VERSION "created by canmatrix"

NS_ :

BS_:

BU_: IPD

BO_ 882 BCM_BDCAN_100ms_FrP41: 8 Vector__XXX
 SG_ RrTireStdPrs : 35|4@0+ (0.1,1.5) [1.5|3] "null" IPD
 SG_ FrtTireStdPrs : 39|4@0+ (0.1,1.5) [1.5|3] "null" IPD

BO_ 1949 DIAG_DTCInfo_ICBAD: 8 IPD
 SG_ DTCInfomationIPD : 7|56@0+ (1,0) [0|72057594037927935] "null" Vector__XXX

BO_ 1319 DKMM_LHBDCANFD_Event_FrS03: 8 Vector__XXX
 SG_ AIParkngSpcID : 31|5@0+ (1,0) [0|31] "null" IPD

BO_ 2015 Diag_BKPCANFD_FuncReq: 64 Vector__XXX

BO_ 1845 Diag_BKPCANFD_PhyReq_IPD: 64 Vector__XXX

BO_ 1853 Diag_BKPCANFD_PhyResp_IPD: 64 IPD

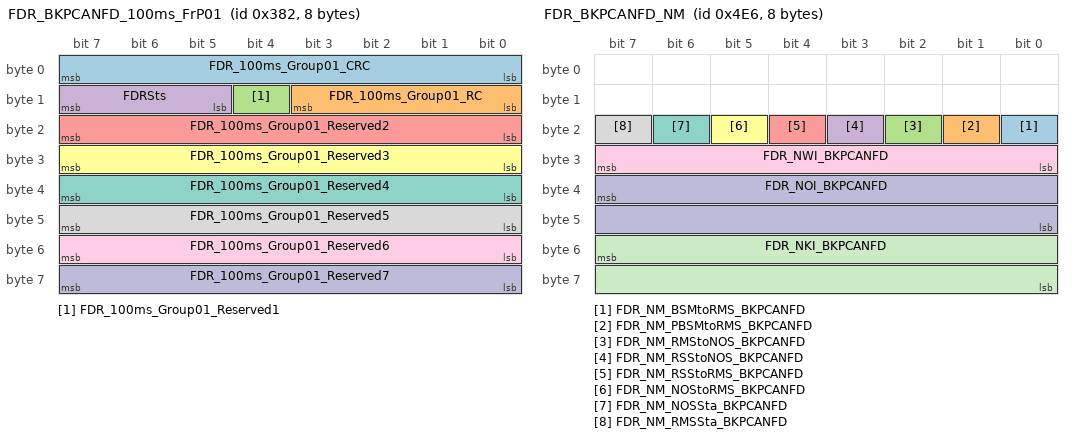
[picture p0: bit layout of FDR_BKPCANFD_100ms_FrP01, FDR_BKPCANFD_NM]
BO_ 898 FDR_BKPCANFD_100ms_FrP01: 8 Vector__XXX
 SG_ FDR_100ms_Group01_CRC : 7|8@0+ (1,0) [0|255] "null" IPD
 SG_ FDR_100ms_Group01_RC : 11|4@0+ (1,0) [0|15] "null" IPD
 SG_ FDR_100ms_Group01_Reserved1 : 12|1@0+ (1,0) [0|1] "null" IPD
 SG_ FDRSts : 15|3@0+ (1,0) [0|7] "null" IPD
 SG_ FDR_100ms_Group01_Reserved2 : 23|8@0+ (1,0) [0|255] "null" IPD
 SG_ FDR_100ms_Group01_Reserved3 : 31|8@0+ (1,0) [0|255] "null" IPD
 SG_ FDR_100ms_Group01_Reserved4 : 39|8@0+ (1,0) [0|255] "null" IPD
 SG_ FDR_100ms_Group01_Reserved5 : 47|8@0+ (1,0) [0|255] "null" IPD
 SG_ FDR_100ms_Group01_Reserved6 : 55|8@0+ (1,0) [0|255] "null" IPD
 SG_ FDR_100ms_Group01_Reserved7 : 63|8@0+ (1,0) [0|255] "null" IPD

BO_ 1254 FDR_BKPCANFD_NM: 8 Vector__XXX
 SG_ FDR_NM_BSMtoRMS_BKPCANFD : 16|1@0+ (1,0) [0|1] "null" Vector__XXX
 SG_ FDR_NM_PBSMtoRMS_BKPCANFD : 17|1@0+ (1,0) [0|1] "null" Vector__XXX
 SG_ FDR_NM_RMStoNOS_BKPCANFD : 18|1@0+ (1,0) [0|1] "null" Vector__XXX
 SG_ FDR_NM_RSStoNOS_BKPCANFD : 19|1@0+ (1,0) [0|1] "null" Vector__XXX
 SG_ FDR_NM_RSStoRMS_BKPCANFD : 20|1@0+ (1,0) [0|1] "null" Vector__XXX
 SG_ FDR_NM_NOStoRMS_BKPCANFD : 21|1@0+ (1,0) [0|1] "null" Vector__XXX
 SG_ FDR_NM_NOSSta_BKPCANFD : 22|1@0+ (1,0) [0|1] "null" Vector__XXX
 SG_ FDR_NM_RMSSta_BKPCANFD : 23|1@0+ (1,0) [0|1] "null" Vector__XXX
 SG_ FDR_NWI_BKPCANFD : 31|8@0+ (1,0) [0|255] "null" Vector__XXX
 SG_ FDR_NOI_BKPCANFD : 39|16@0+ (1,0) [0|65535] "null" Vector__XXX
 SG_ FDR_NKI_BKPCANFD : 55|16@0+ (1,0) [0|65535] "null" Vector__XXX

BO_ 958 FVCM_BKPCANFD_100ms_FrP04: 64 IPD
 SG_ ACCDetObj1LatRltvDist : 23|15@0+ (0.0078,-128) [-128.0000|127.5826] "null" Vector__XXX
 SG_ ACCDetObj1Risk : 24|1@0+ (1,0) [0|1] "null" Vector__XXX
 SG_ ACCDetObj2LatRltvDist : 39|15@0+ (0.0078,-128) [-128.0000|127.5826] "null" Vector__XXX
 SG_ ACCDetObj2Risk : 40|1@0+ (1,0) [0|1] "null" Vector__XXX
 SG_ ACCDetObj3LatRltvDist : 55|15@0+ (0.0078,-128) [-128.0000|127.5826] "null" Vector__XXX
 SG_ ACCDetObj3Risk : 56|1@0+ (1,0) [0|1] "null" Vector__XXX
 SG_ ACCDetObj1LongtRltvDist : 71|12@0+ (0.0625,0) [0.0000|255.9375] "null" Vector__XXX
 SG_ ACCDetObj1LongtRltvSpd : 75|12@0+ (0.0625,-128) [-128.0000|127.9375] "null" Vector__XXX
 SG_ ACCDetObj2LongtRltvDist : 95|12@0+ (0.0625,0) [0.0000|255.9375] "null" Vector__XXX
 SG_ ACCDetObj2LongtRltvSpd : 99|12@0+ (0.0625,-128) [-128.0000|127.9375] "null" Vector__XXX
 SG_ ACCDetObj3LongtRltvDist : 119|12@0+ (0.0625,0) [0.0000|255.9375] "null" Vector__XXX
 SG_ ACCDetObj3LongtRltvSpd : 123|12@0+ (0.0625,-128) [-128.0000|127.9375] "null" Vector__XXX
 SG_ ACCConfmSw : 137|2@0+ (1,0) [0|3] "null" Vector__XXX
 SG_ ACCDetObj1ExistPrblty : 143|6@0+ (0.015625,0) [0.000000|0.984375] "null" Vector__XXX
 SG_ ACCCurveSpdSw : 145|2@0+ (1,0) [0|3] "null" Vector__XXX
 SG_ ACCDetObj1Id : 151|6@0+ (1,0) [0|63] "null" Vector__XXX
 SG_ ACCDetObj2Id : 153|6@0+ (1,0) [0|63] "null" Vector__XXX
 SG_ ACCDetObj2ExistPrblty : 159|6@0+ (0.015625,0) [0.000000|0.984375] "null" Vector__XXX
 SG_ ACCDetObj3ExistPrblty : 163|6@0+ (0.015625,0) [0.000000|0.984375] "null" Vector__XXX
 SG_ ACCDetObj3Id : 183|6@0+ (1,0) [0|63] "null" Vector__XXX
 SG_ ELKWarning : 191|4@0+ (1,0) [0|15] "null" Vector__XXX
 SG_ ACCDetObj2SyncCtr : 195|4@0+ (1,0) [0|15] "null" Vector__XXX
 SG_ ACCDetObj1SyncCtr : 199|4@0+ (1,0) [0|15] "null" Vector__XXX
 SG_ ACCDetObj3SyncCtr : 207|4@0+ (1,0) [0|15] "null" Vector__XXX
 SG_ ACCDetObj2Typ : 217|3@0+ (1,0) [0|7] "null" Vector__XXX
 SG_ ACCDetObj1Typ : 230|3@0+ (1,0) [0|7] "null" Vector__XXX
 SG_ ACCDrvrTkovReq : 256|1@0+ (1,0) [0|1] "null" Vector__XXX
 SG_ ACCDetObj3Typ : 506|3@0+ (1,0) [0|7] "null" Vector__XXX

BO_ 956 FVCM_BKPCANFD_100ms_FrP05: 64 IPD
 SG_ PilotSysMsg : 15|4@0+ (1,0) [0|15] "null" Vector__XXX
 SG_ Lane0_C0 : 23|12@0+ (0.00390625,-8) [-8.00000000|7.99609375] "null" Vector__XXX
 SG_ Lane0_C1 : 27|12@0+ (0.00048828125,-1) [-1.00000000000|0.99951171875] "null" Vector__XXX
 SG_ Lane0_C2 : 47|12@0+ (0.000015259,-0.03124285) [-0.031242850|0.031242755] "null" Vector__XXX
 SG_ Lane0_C3 : 51|12@0+ (4.768E-007,-2.3842E-007) [-2.3842E-007|0.00195225758] "null" Vector__XXX
 SG_ Lane1_C0 : 71|12@0+ (0.00390625,-8) [-8.00000000|7.99609375] "null" Vector__XXX
 SG_ Lane1_C1 : 75|12@0+ (0.00048828125,-1) [-1.00000000000|0.99951171875] "null" Vector__XXX
 SG_ Lane1_C2 : 95|12@0+ (0.000015259,-0.03124285) [-0.031242850|0.031242755] "null" Vector__XXX
 SG_ Lane1_C3 : 99|12@0+ (4.768E-007,-2.3842E-007) [-2.3842E-007|0.00195225758] "null" Vector__XXX
 SG_ Lane2_C0 : 119|12@0+ (0.00390625,-8) [-8.00000000|7.99609375] "null" Vector__XXX
 SG_ Lane2_C1 : 123|12@0+ (0.00048828125,-1) [-1.00000000000|0.99951171875] "null" Vector__XXX
 SG_ Lane2_C2 : 143|12@0+ (0.000015259,-0.03124285) [-0.031242850|0.031242755] "null" Vector__XXX
 SG_ Lane2_C3 : 147|12@0+ (0.0000038147,-0.0078125) [-0.0078125000|0.0078086965] "null" Vector__XXX
 SG_ Lane3_C0 : 167|12@0+ (0.00390625,-8) [-8.00000000|7.99609375] "null" Vector__XXX
 SG_ Lane3_C1 : 171|12@0+ (0.00048828125,-1) [-1.00000000000|0.99951171875] "null" Vector__XXX
 SG_ Lane3_C2 : 191|12@0+ (0.000015259,-0.03124285) [-0.031242850|0.031242755] "null" Vector__XXX
 SG_ Lane3_C3 : 195|12@0+ (0.0000038147,-0.0078125) [-0.0078125000|0.0078086965] "null" Vector__XXX
 SG_ Lane0_ViewRangeStart : 215|8@0+ (0.25,0) [0.00|63.75] "null" Vector__XXX
 SG_ Lane1_ViewRangeStart : 223|8@0+ (0.25,0) [0.00|63.75] "null" Vector__XXX
 SG_ Lane2_ViewRangeStart : 231|8@0+ (0.25,0) [0.00|63.75] "null" Vector__XXX
 SG_ Lane3_ViewRangeStart : 239|8@0+ (0.25,0) [0.00|63.75] "null" Vector__XXX
 SG_ Lane0_ViewRangeEnd : 247|9@0+ (0.25,0) [0.00|127.75] "null" Vector__XXX
 SG_ Lane1_ViewRangeEnd : 248|9@0+ (0.25,0) [0.00|127.75] "null" Vector__XXX
 SG_ Lane0_ExistPrblty : 254|6@0+ (0.015625,0) [0.000000|0.984375] "null" Vector__XXX
 SG_ Lane2_ViewRangeEnd : 271|9@0+ (0.25,0) [0.00|127.75] "null" Vector__XXX
 SG_ Lane3_ViewRangeEnd : 272|9@0+ (0.25,0) [0.00|127.75] "null" Vector__XXX
 SG_ Lane1_ExistPrblty : 278|6@0+ (0.015625,0) [0.000000|0.984375] "null" Vector__XXX
 SG_ Lane0_Part0_SyncFrameIndex : 291|4@0+ (1,0) [0|15] "null" Vector__XXX
 SG_ Lane0_ID : 295|4@0+ (1,0) [0|15] "null" Vector__XXX
 SG_ Lane1_Part0_SyncFrameIndex : 299|4@0+ (1,0) [0|15] "null" Vector__XXX
 SG_ Lane1_ID : 303|4@0+ (1,0) [0|15] "null" Vector__XXX
 SG_ Lane2_Part0_SyncFrameIndex : 307|4@0+ (1,0) [0|15] "null" Vector__XXX
 SG_ Lane2_ID : 311|4@0+ (1,0) [0|15] "null" Vector__XXX
 SG_ Lane3_Part0_SyncFrameIndex : 315|4@0+ (1,0) [0|15] "null" Vector__XXX
 SG_ Lane3_ID : 319|4@0+ (1,0) [0|15] "null" Vector__XXX
 SG_ TLRMsgReq : 321|2@0+ (1,0) [0|3] "null" Vector__XXX
 SG_ Lane0_MarkerColor : 324|3@0+ (1,0) [0|7] "null" Vector__XXX
 SG_ Lane0_location : 327|3@0+ (1,0) [0|7] "null" Vector__XXX
 SG_ TLRSysSts : 329|2@0+ (1,0) [0|3] "null" Vector__XXX
 SG_ Lane1_location : 332|3@0+ (1,0) [0|7] "null" Vector__XXX
 SG_ Lane0_MarkerType : 335|3@0+ (1,0) [0|7] "null" Vector__XXX
 SG_ Lane1_MarkerType : 340|3@0+ (1,0) [0|7] "null" Vector__XXX
 SG_ Lane1_MarkerColor : 343|3@0+ (1,0) [0|7] "null" Vector__XXX
 SG_ Lane2_ExistPrblty : 351|6@0+ (0.015625,0) [0.000000|0.984375] "null" Vector__XXX
 SG_ Lane2_MarkerColor : 356|3@0+ (1,0) [0|7] "null" Vector__XXX
 SG_ Lane2_location : 359|3@0+ (1,0) [0|7] "null" Vector__XXX
 SG_ Lane3_location : 364|3@0+ (1,0) [0|7] "null" Vector__XXX
 SG_ Lane2_MarkerType : 367|3@0+ (1,0) [0|7] "null" Vector__XXX
 SG_ Lane3_ExistPrblty : 375|6@0+ (0.015625,0) [0.000000|0.984375] "null" Vector__XXX
 SG_ Lane3_MarkerType : 380|3@0+ (1,0) [0|7] "null" Vector__XXX
 SG_ Lane3_MarkerColor : 383|3@0+ (1,0) [0|7] "null" Vector__XXX
 SG_ TLRWarning : 388|3@0+ (1,0) [0|7] "null" Vector__XXX
 SG_ TLRMdSwDspCmd : 391|3@0+ (1,0) [0|7] "null" Vector__XXX
 SG_ SpdLmtOfstSetResp : 399|6@0+ (1,-20) [-20|43] "null" Vector__XXX
 SG_ ACCDetObjHdngAng : 495|8@0+ (2,-180) [-180|330] "null" Vector__XXX
 SG_ CCSpdVcCmdCnfm : 503|3@0+ (1,0) [0|7] "null" Vector__XXX

BO_ 307 FVCM_BKPCANFD_20ms_FrP02: 16 IPD
 SG_ FVCM_20ms_Group02_CRC : 7|8@0+ (1,0) [0|255] "null" Vector__XXX
 SG_ FVCM_20ms_Group02_RC : 11|4@0+ (1,0) [0|15] "null" Vector__XXX
 SG_ FVCM_20ms_Group02_Reserved1 : 15|4@0+ (1,0) [0|15] "null" Vector__XXX
 SG_ ACCTotWhlToqReqVal : 23|16@0+ (1,-30000) [-30000|35535] "null" Vector__XXX
 SG_ ACCDrvrSelTrgtSpd : 39|15@0+ (0.015625,0) [0.000000|511.984375] "ms" Vector__XXX
 SG_ ACCGoNotfr : 40|1@0+ (1,0) [0|1] "null" Vector__XXX
 SG_ FVCM_20ms_Group02_Reserved2 : 48|1@0+ (1,0) [0|1] "null" Vector__XXX
 SG_ ACCDetObjDistLvl : 51|3@0+ (1,0) [0|7] "null" Vector__XXX
 SG_ ELKSysSts_IPD : 55|4@0+ (1,0) [0|15] "null" Vector__XXX
 SG_ ACCTotWhlToqReqSts : 57|2@0+ (1,0) [0|3] "null" Vector__XXX
 SG_ ACCTJAMdSwDspCmd : 60|3@0+ (1,0) [0|7] "null" Vector__XXX
 SG_ ACCSeldTrgtDistLvl : 63|3@0+ (1,0) [0|7] "null" Vector__XXX
 SG_ FVCM_20ms_Group02_Reserved3 : 71|8@0+ (1,0) [0|255] "null" Vector__XXX
 SG_ HandOffStrgWhlDetnSta : 73|2@0+ (1,0) [0|3] "null" Vector__XXX
 SG_ ILCActvnDircnDspCmd : 76|3@0+ (1,0) [0|7] "null" Vector__XXX
 SG_ FVCM_20ms_Group02_Reserved4 : 79|3@0+ (1,0) [0|7] "null" Vector__XXX
 SG_ ILCSwDspCmd : 81|2@0+ (1,0) [0|3] "null" Vector__XXX
 SG_ ILCSysSts : 84|3@0+ (1,0) [0|7] "null" Vector__XXX
 SG_ ILCActvnVelDspCmd : 87|3@0+ (1,0) [0|7] "null" Vector__XXX
 SG_ HandOffStrgWhlDetnStaV : 88|1@0+ (1,0) [0|1] "null" Vector__XXX
 SG_ LDWLKAAudReq : 90|2@0+ (1,0) [0|3] "null" Vector__XXX
 SG_ LDWAdoWrnngDspCmd : 92|2@0+ (1,0) [0|3] "null" Vector__XXX
 SG_ LDWLKADspCmd : 95|3@0+ (1,0) [0|7] "null" Vector__XXX
 SG_ FVCM_20ms_Group02_Reserved5 : 98|3@0+ (1,0) [0|7] "null" Vector__XXX
 SG_ LKADrvrTkovReq : 99|1@0+ (1,0) [0|1] "null" Vector__XXX
 SG_ LDWSnstvtLvl : 101|2@0+ (1,0) [0|3] "null" Vector__XXX
 SG_ LDWLKAHptWrnngDspCmd : 103|2@0+ (1,0) [0|3] "null" Vector__XXX
 SG_ EyeOffRoadDetnSta : 105|2@0+ (1,0) [0|3] "null" Vector__XXX
 SG_ FVCM_20ms_Group02_Reserved6 : 111|6@0+ (1,0) [0|63] "null" Vector__XXX
 SG_ FVCM_20ms_Group02_Reserved7 : 113|2@0+ (1,0) [0|3] "null" Vector__XXX
 SG_ EyeOffRoadDetnStaV : 114|1@0+ (1,0) [0|1] "null" Vector__XXX
 SG_ ACCMsgReq : 119|5@0+ (1,0) [0|31] "null" Vector__XXX
 SG_ FVCM_20ms_Group02_Reserved8 : 127|8@0+ (1,0) [0|255] "null" Vector__XXX

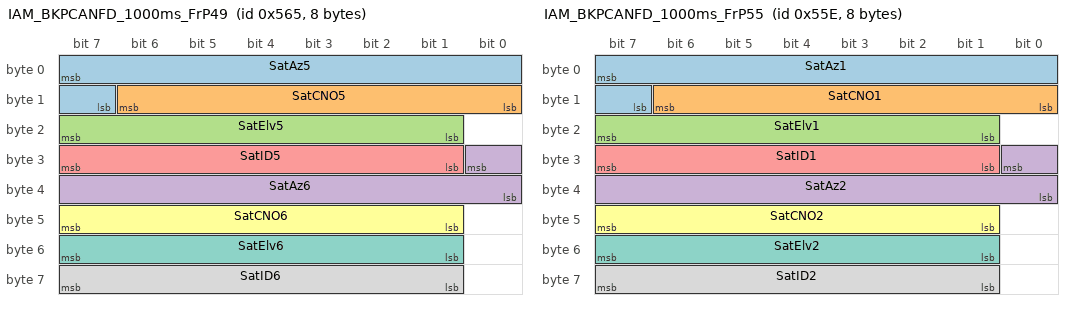
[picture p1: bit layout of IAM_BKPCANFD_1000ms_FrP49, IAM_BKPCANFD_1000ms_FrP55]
BO_ 1381 IAM_BKPCANFD_1000ms_FrP49: 8 Vector__XXX
 SG_ SatAz5 : 7|9@0+ (1,0) [0|511] "Degree" IPD
 SG_ SatCNO5 : 14|7@0+ (1,0) [0|127] "dB" IPD
 SG_ SatElv5 : 23|7@0+ (1,0) [0|127] "Degree" IPD
 SG_ SatAz6 : 24|9@0+ (1,0) [0|511] "Degree" IPD
 SG_ SatID5 : 31|7@0+ (1,0) [0|127] "null" IPD
 SG_ SatCNO6 : 47|7@0+ (1,0) [0|127] "dB" IPD
 SG_ SatElv6 : 55|7@0+ (1,0) [0|127] "Degree" IPD
 SG_ SatID6 : 63|7@0+ (1,0) [0|127] "null" IPD

BO_ 1374 IAM_BKPCANFD_1000ms_FrP55: 8 Vector__XXX
 SG_ SatAz1 : 7|9@0+ (1,0) [0|511] "Degree" IPD
 SG_ SatCNO1 : 14|7@0+ (1,0) [0|127] "dB" IPD
 SG_ SatElv1 : 23|7@0+ (1,0) [0|127] "Degree" IPD
 SG_ SatAz2 : 24|9@0+ (1,0) [0|511] "Degree" IPD
 SG_ SatID1 : 31|7@0+ (1,0) [0|127] "null" IPD
 SG_ SatCNO2 : 47|7@0+ (1,0) [0|127] "dB" IPD
 SG_ SatElv2 : 55|7@0+ (1,0) [0|127] "Degree" IPD
 SG_ SatID2 : 63|7@0+ (1,0) [0|127] "null" IPD

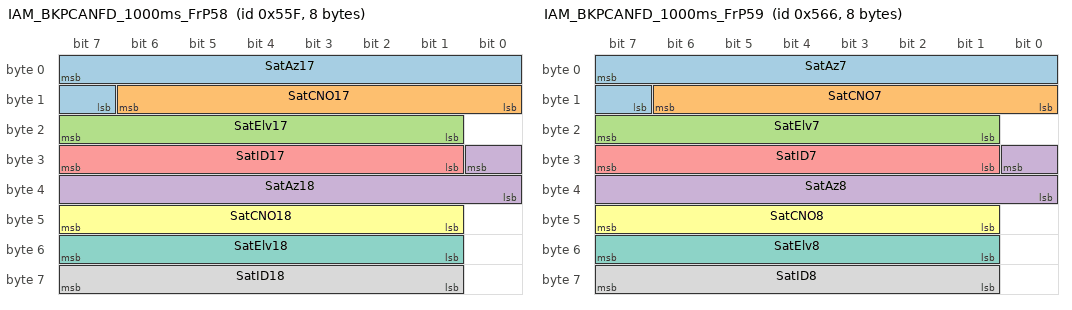
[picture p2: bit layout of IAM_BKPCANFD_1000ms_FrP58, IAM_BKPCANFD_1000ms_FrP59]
BO_ 1375 IAM_BKPCANFD_1000ms_FrP58: 8 Vector__XXX
 SG_ SatAz17 : 7|9@0+ (1,0) [0|511] "Degree" IPD
 SG_ SatCNO17 : 14|7@0+ (1,0) [0|127] "dB" IPD
 SG_ SatElv17 : 23|7@0+ (1,0) [0|127] "Degree" IPD
 SG_ SatAz18 : 24|9@0+ (1,0) [0|511] "Degree" IPD
 SG_ SatID17 : 31|7@0+ (1,0) [0|127] "null" IPD
 SG_ SatCNO18 : 47|7@0+ (1,0) [0|127] "dB" IPD
 SG_ SatElv18 : 55|7@0+ (1,0) [0|127] "Degree" IPD
 SG_ SatID18 : 63|7@0+ (1,0) [0|127] "null" IPD

BO_ 1382 IAM_BKPCANFD_1000ms_FrP59: 8 Vector__XXX
 SG_ SatAz7 : 7|9@0+ (1,0) [0|511] "Degree" IPD
 SG_ SatCNO7 : 14|7@0+ (1,0) [0|127] "dB" IPD
 SG_ SatElv7 : 23|7@0+ (1,0) [0|127] "Degree" IPD
 SG_ SatAz8 : 24|9@0+ (1,0) [0|511] "Degree" IPD
 SG_ SatID7 : 31|7@0+ (1,0) [0|127] "null" IPD
 SG_ SatCNO8 : 47|7@0+ (1,0) [0|127] "dB" IPD
 SG_ SatElv8 : 55|7@0+ (1,0) [0|127] "Degree" IPD
 SG_ SatID8 : 63|7@0+ (1,0) [0|127] "null" IPD

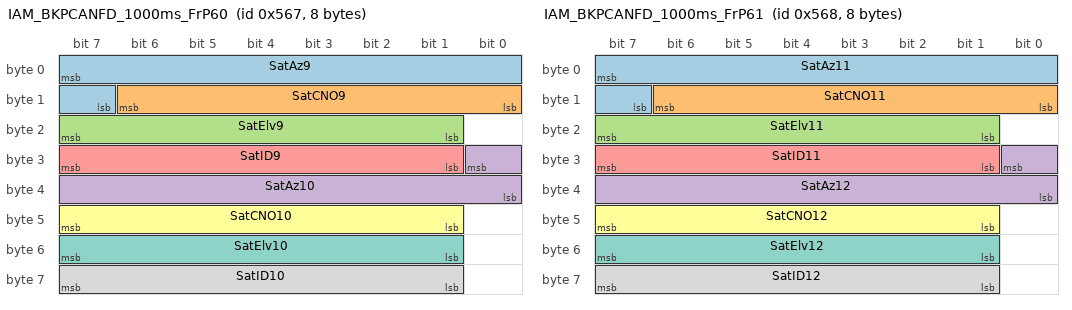
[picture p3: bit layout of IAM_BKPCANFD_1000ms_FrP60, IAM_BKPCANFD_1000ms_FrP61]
BO_ 1383 IAM_BKPCANFD_1000ms_FrP60: 8 Vector__XXX
 SG_ SatAz9 : 7|9@0+ (1,0) [0|511] "Degree" IPD
 SG_ SatCNO9 : 14|7@0+ (1,0) [0|127] "dB" IPD
 SG_ SatElv9 : 23|7@0+ (1,0) [0|127] "Degree" IPD
 SG_ SatAz10 : 24|9@0+ (1,0) [0|511] "Degree" IPD
 SG_ SatID9 : 31|7@0+ (1,0) [0|127] "null" IPD
 SG_ SatCNO10 : 47|7@0+ (1,0) [0|127] "dB" IPD
 SG_ SatElv10 : 55|7@0+ (1,0) [0|127] "Degree" IPD
 SG_ SatID10 : 63|7@0+ (1,0) [0|127] "null" IPD

BO_ 1384 IAM_BKPCANFD_1000ms_FrP61: 8 Vector__XXX
 SG_ SatAz11 : 7|9@0+ (1,0) [0|511] "Degree" IPD
 SG_ SatCNO11 : 14|7@0+ (1,0) [0|127] "dB" IPD
 SG_ SatElv11 : 23|7@0+ (1,0) [0|127] "Degree" IPD
 SG_ SatAz12 : 24|9@0+ (1,0) [0|511] "Degree" IPD
 SG_ SatID11 : 31|7@0+ (1,0) [0|127] "null" IPD
 SG_ SatCNO12 : 47|7@0+ (1,0) [0|127] "dB" IPD
 SG_ SatElv12 : 55|7@0+ (1,0) [0|127] "Degree" IPD
 SG_ SatID12 : 63|7@0+ (1,0) [0|127] "null" IPD

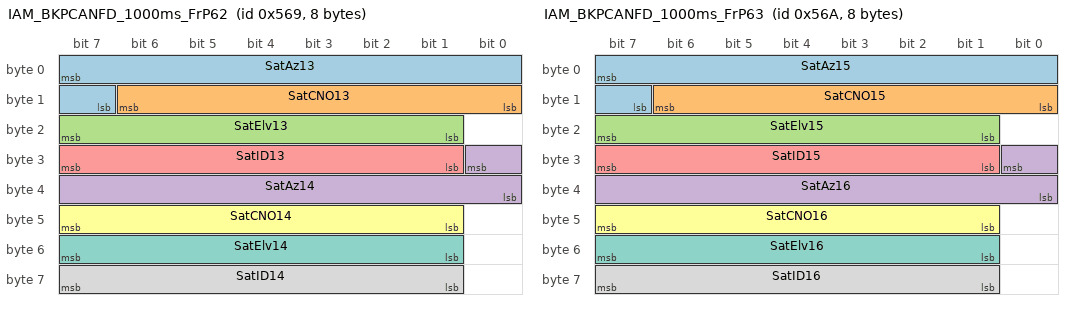
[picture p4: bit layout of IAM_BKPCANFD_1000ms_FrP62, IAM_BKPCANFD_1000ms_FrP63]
BO_ 1385 IAM_BKPCANFD_1000ms_FrP62: 8 Vector__XXX
 SG_ SatAz13 : 7|9@0+ (1,0) [0|511] "Degree" IPD
 SG_ SatCNO13 : 14|7@0+ (1,0) [0|127] "dB" IPD
 SG_ SatElv13 : 23|7@0+ (1,0) [0|127] "Degree" IPD
 SG_ SatAz14 : 24|9@0+ (1,0) [0|511] "Degree" IPD
 SG_ SatID13 : 31|7@0+ (1,0) [0|127] "null" IPD
 SG_ SatCNO14 : 47|7@0+ (1,0) [0|127] "dB" IPD
 SG_ SatElv14 : 55|7@0+ (1,0) [0|127] "Degree" IPD
 SG_ SatID14 : 63|7@0+ (1,0) [0|127] "null" IPD

BO_ 1386 IAM_BKPCANFD_1000ms_FrP63: 8 Vector__XXX
 SG_ SatAz15 : 7|9@0+ (1,0) [0|511] "Degree" IPD
 SG_ SatCNO15 : 14|7@0+ (1,0) [0|127] "dB" IPD
 SG_ SatElv15 : 23|7@0+ (1,0) [0|127] "Degree" IPD
 SG_ SatAz16 : 24|9@0+ (1,0) [0|511] "Degree" IPD
 SG_ SatID15 : 31|7@0+ (1,0) [0|127] "null" IPD
 SG_ SatCNO16 : 47|7@0+ (1,0) [0|127] "dB" IPD
 SG_ SatElv16 : 55|7@0+ (1,0) [0|127] "Degree" IPD
 SG_ SatID16 : 63|7@0+ (1,0) [0|127] "null" IPD

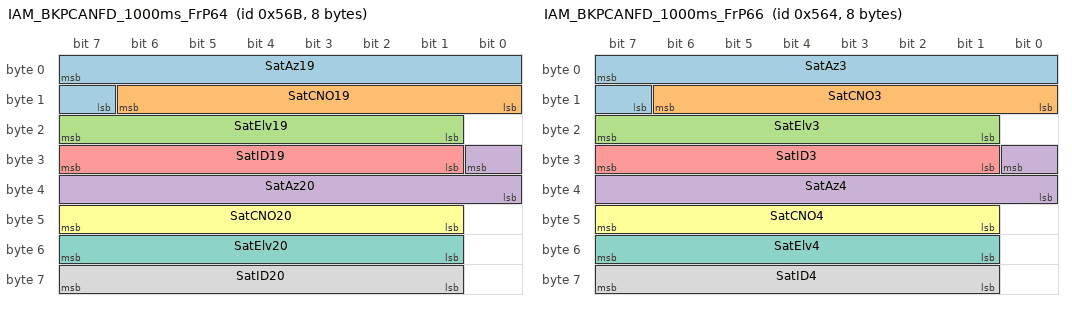
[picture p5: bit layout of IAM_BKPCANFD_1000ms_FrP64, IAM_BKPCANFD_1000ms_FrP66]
BO_ 1387 IAM_BKPCANFD_1000ms_FrP64: 8 Vector__XXX
 SG_ SatAz19 : 7|9@0+ (1,0) [0|511] "Degree" IPD
 SG_ SatCNO19 : 14|7@0+ (1,0) [0|127] "dB" IPD
 SG_ SatElv19 : 23|7@0+ (1,0) [0|127] "Degree" IPD
 SG_ SatAz20 : 24|9@0+ (1,0) [0|511] "Degree" IPD
 SG_ SatID19 : 31|7@0+ (1,0) [0|127] "null" IPD
 SG_ SatCNO20 : 47|7@0+ (1,0) [0|127] "dB" IPD
 SG_ SatElv20 : 55|7@0+ (1,0) [0|127] "Degree" IPD
 SG_ SatID20 : 63|7@0+ (1,0) [0|127] "null" IPD

BO_ 1388 IAM_BKPCANFD_1000ms_FrP65: 8 Vector__XXX
 SG_ SatNum : 7|7@0+ (1,0) [0|127] "null" IPD
 SG_ SvGroup : 15|8@0+ (1,0) [0|255] "null" IPD

BO_ 1380 IAM_BKPCANFD_1000ms_FrP66: 8 Vector__XXX
 SG_ SatAz3 : 7|9@0+ (1,0) [0|511] "Degree" IPD
 SG_ SatCNO3 : 14|7@0+ (1,0) [0|127] "dB" IPD
 SG_ SatElv3 : 23|7@0+ (1,0) [0|127] "Degree" IPD
 SG_ SatAz4 : 24|9@0+ (1,0) [0|511] "Degree" IPD
 SG_ SatID3 : 31|7@0+ (1,0) [0|127] "null" IPD
 SG_ SatCNO4 : 47|7@0+ (1,0) [0|127] "dB" IPD
 SG_ SatElv4 : 55|7@0+ (1,0) [0|127] "Degree" IPD
 SG_ SatID4 : 63|7@0+ (1,0) [0|127] "null" IPD

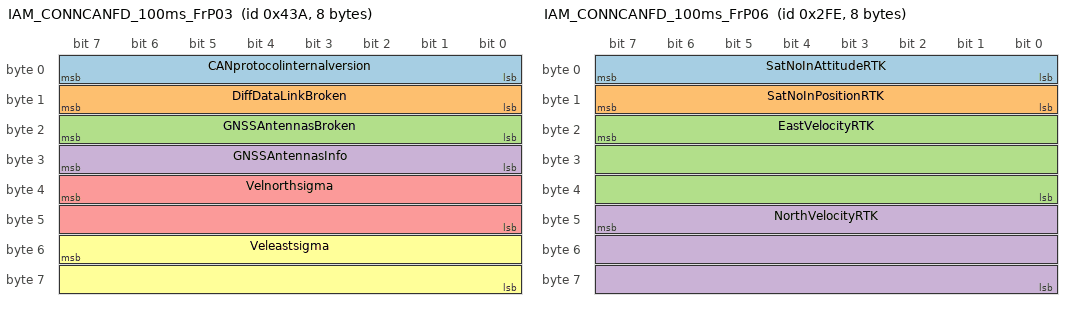
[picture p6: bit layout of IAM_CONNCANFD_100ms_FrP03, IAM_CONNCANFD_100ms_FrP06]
BO_ 1082 IAM_CONNCANFD_100ms_FrP03: 8 Vector__XXX
 SG_ CANprotocolinternalversion : 7|8@0+ (1,0) [0|255] "null" IPD
 SG_ DiffDataLinkBroken : 15|8@0+ (1,0) [0|255] "null" IPD
 SG_ GNSSAntennasBroken : 23|8@0+ (1,0) [0|255] "null" IPD
 SG_ GNSSAntennasInfo : 31|8@0+ (1,0) [0|255] "null" IPD
 SG_ Velnorthsigma : 39|16@0+ (0.001,0) [0.000|65.535] "null" IPD
 SG_ Veleastsigma : 55|16@0+ (0.001,0) [0.000|65.535] "null" IPD

BO_ 766 IAM_CONNCANFD_100ms_FrP06: 8 Vector__XXX
 SG_ SatNoInAttitudeRTK : 7|8@0+ (1,0) [0|255] "null" IPD
 SG_ SatNoInPositionRTK : 15|8@0+ (1,0) [0|255] "null" IPD
 SG_ EastVelocityRTK : 23|24@0- (0.001,0) [-8388.608|8388.607] "null" IPD
 SG_ NorthVelocityRTK : 47|24@0- (0.001,0) [-8388.608|8388.607] "null" IPD

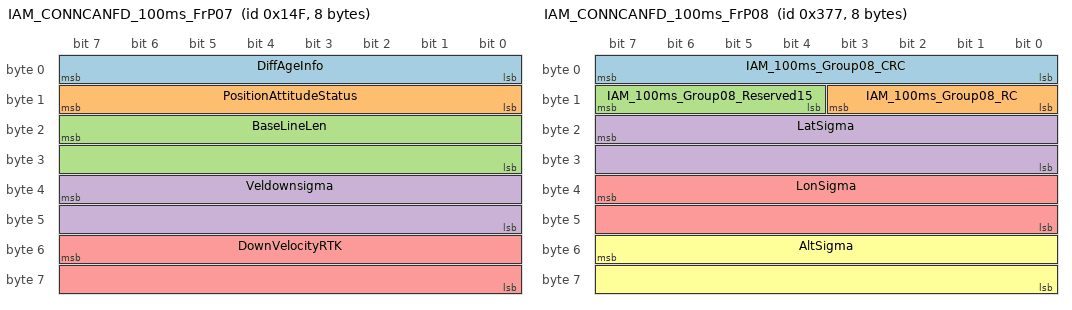
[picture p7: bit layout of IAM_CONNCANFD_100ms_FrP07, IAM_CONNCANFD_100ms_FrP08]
BO_ 335 IAM_CONNCANFD_100ms_FrP07: 8 Vector__XXX
 SG_ DiffAgeInfo : 7|8@0+ (1,0) [0|255] "null" IPD
 SG_ PositionAttitudeStatus : 15|8@0+ (1,0) [0|255] "null" IPD
 SG_ BaseLineLen : 23|16@0+ (0.001,0) [0.000|65.535] "null" IPD
 SG_ Veldownsigma : 39|16@0+ (0.001,0) [0.000|65.535] "null" IPD
 SG_ DownVelocityRTK : 55|16@0- (0.001,0) [-32.768|32.767] "null" IPD

BO_ 887 IAM_CONNCANFD_100ms_FrP08: 8 Vector__XXX
 SG_ IAM_100ms_Group08_CRC : 7|8@0+ (1,0) [0|255] "null" IPD
 SG_ IAM_100ms_Group08_RC : 11|4@0+ (1,0) [0|15] "null" IPD
 SG_ IAM_100ms_Group08_Reserved15 : 15|4@0+ (1,0) [0|15] "null" IPD
 SG_ LatSigma : 23|16@0+ (0.001,0) [0.000|65.535] "null" IPD
 SG_ LonSigma : 39|16@0+ (0.001,0) [0.000|65.535] "null" IPD
 SG_ AltSigma : 55|16@0+ (0.001,0) [0.000|65.535] "null" IPD

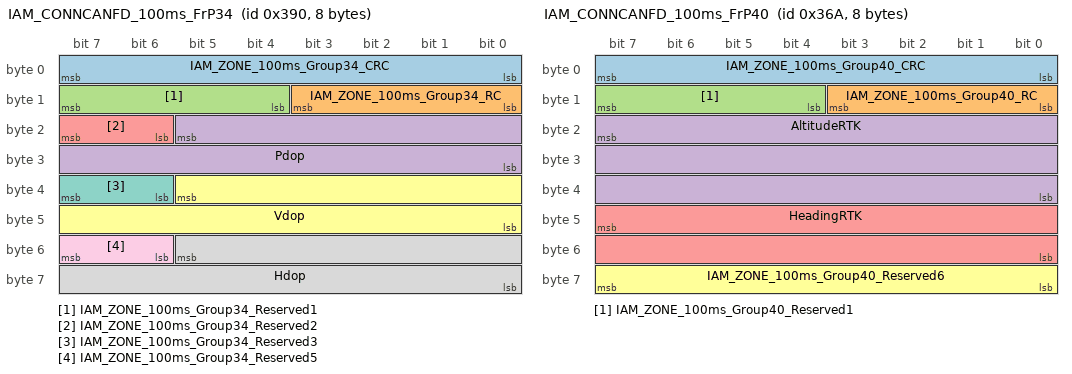
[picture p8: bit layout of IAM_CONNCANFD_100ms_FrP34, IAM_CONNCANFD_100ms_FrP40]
BO_ 912 IAM_CONNCANFD_100ms_FrP34: 8 Vector__XXX
 SG_ IAM_ZONE_100ms_Group34_CRC : 7|8@0+ (1,0) [0|255] "null" IPD
 SG_ IAM_ZONE_100ms_Group34_RC : 11|4@0+ (1,0) [0|15] "null" IPD
 SG_ IAM_ZONE_100ms_Group34_Reserved1 : 15|4@0+ (1,0) [0|15] "null" IPD
 SG_ Pdop : 21|14@0+ (0.01,0) [0.00|163.83] "null" IPD
 SG_ IAM_ZONE_100ms_Group34_Reserved2 : 23|2@0+ (1,0) [0|3] "null" IPD
 SG_ Vdop : 37|14@0+ (0.01,0) [0.00|163.83] "null" IPD
 SG_ IAM_ZONE_100ms_Group34_Reserved3 : 39|2@0+ (1,0) [0|3] "null" IPD
 SG_ Hdop : 53|14@0+ (0.01,0) [0.00|163.83] "null" IPD
 SG_ IAM_ZONE_100ms_Group34_Reserved5 : 55|2@0+ (1,0) [0|3] "null" IPD

BO_ 874 IAM_CONNCANFD_100ms_FrP40: 8 Vector__XXX
 SG_ IAM_ZONE_100ms_Group40_CRC : 7|8@0+ (1,0) [0|255] "null" IPD
 SG_ IAM_ZONE_100ms_Group40_RC : 11|4@0+ (1,0) [0|15] "null" IPD
 SG_ IAM_ZONE_100ms_Group40_Reserved1 : 15|4@0+ (1,0) [0|15] "null" IPD
 SG_ AltitudeRTK : 23|24@0- (0.001,0) [-8388.608|8388.607] "null" IPD
 SG_ HeadingRTK : 47|16@0+ (0.01,0) [0.00|655.35] "null" IPD
 SG_ IAM_ZONE_100ms_Group40_Reserved6 : 63|8@0+ (1,0) [0|255] "null" IPD

BO_ 336 IAM_CONNCANFD_20ms_FrP32: 16 Vector__XXX
 SG_ IAM_20ms_Group32_CRC : 7|8@0+ (1,0) [0|255] "null" IPD
 SG_ IAM_20ms_Group32_RC : 11|4@0+ (1,0) [0|15] "null" IPD
 SG_ RmtParkngAstParkngOutDircnSeln : 15|4@0+ (1,0) [0|15] "null" IPD
 SG_ RmtParkngAstBtnSts : 16|1@0+ (1,0) [0|1] "null" IPD
 SG_ VehFwdSwReq : 18|2@0+ (1,0) [0|3] "null" IPD
 SG_ VehBkwdSwReq : 20|2@0+ (1,0) [0|3] "null" IPD
 SG_ RmtParkngAstDvcSts : 23|3@0+ (1,0) [0|7] "null" IPD
 SG_ RmtDrvrTrgtEPSStrgWhlAng : 31|16@0+ (0.0625,-2048) [-2048.0000|2047.9375] "degree" IPD
 SG_ VehRoadWhlRReq : 41|2@0+ (1,0) [0|3] "null" IPD
 SG_ VehRoadWhlLReq : 43|2@0+ (1,0) [0|3] "null" IPD
 SG_ RmtParkngAstAbotBtnSts : 44|1@0+ (1,0) [0|1] "null" IPD
 SG_ RmtParkngAstDvcFlrRsn : 47|3@0+ (1,0) [0|7] "null" IPD
 SG_ IAM_20ms_Group32_Reserved1 : 51|4@0+ (1,0) [0|15] "null" IPD
 SG_ VehRoadWhlRReqV : 52|1@0+ (1,0) [0|1] "null" IPD
 SG_ VehRoadWhlLReqV : 53|1@0+ (1,0) [0|1] "null" IPD
 SG_ VehFwdSwReqV : 54|1@0+ (1,0) [0|1] "null" IPD
 SG_ VehBkwdSwReqV : 55|1@0+ (1,0) [0|1] "null" IPD
 SG_ IAM_20ms_Group32_Reserved2 : 63|8@0+ (1,0) [0|255] "null" IPD
 SG_ IAM_20ms_Group32_Reserved3 : 71|8@0+ (1,0) [0|255] "null" IPD
 SG_ IAM_20ms_Group32_Reserved4 : 79|8@0+ (1,0) [0|255] "null" IPD
 SG_ IAM_20ms_Group32_Reserved5 : 87|8@0+ (1,0) [0|255] "null" IPD
 SG_ IAM_20ms_Group32_Reserved6 : 95|8@0+ (1,0) [0|255] "null" IPD
 SG_ IAM_20ms_Group32_Reserved7 : 103|8@0+ (1,0) [0|255] "null" IPD
 SG_ IAM_20ms_Group32_Reserved8 : 111|8@0+ (1,0) [0|255] "null" IPD
 SG_ IAM_20ms_Group32_Reserved9 : 119|8@0+ (1,0) [0|255] "null" IPD
 SG_ IAM_20ms_Group32_Reserved10 : 127|8@0+ (1,0) [0|255] "null" IPD

BO_ 89 IAM_CONNCANFD_Event_FrS04: 16 Vector__XXX
 SG_ IAMReststs : 33|2@0+ (1,0) [0|3] "null" IPD

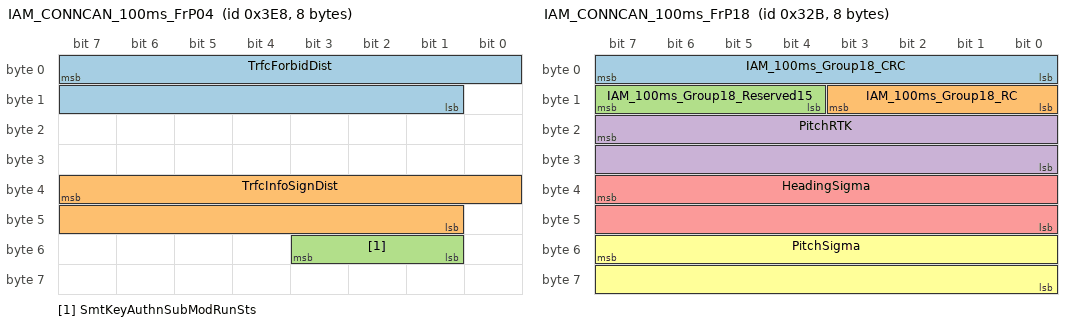
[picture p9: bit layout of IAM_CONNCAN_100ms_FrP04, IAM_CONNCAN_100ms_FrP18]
BO_ 1000 IAM_CONNCAN_100ms_FrP04: 8 Vector__XXX
 SG_ TrfcForbidDist : 7|15@0+ (0.0156,-256) [-256.0000|255.1652] "null" IPD
 SG_ TrfcInfoSignDist : 39|15@0+ (0.0156,-256) [-256.0000|255.1652] "null" IPD
 SG_ SmtKeyAuthnSubModRunSts : 51|3@0+ (1,0) [0|7] "null" Vector__XXX

BO_ 811 IAM_CONNCAN_100ms_FrP18: 8 Vector__XXX
 SG_ IAM_100ms_Group18_CRC : 7|8@0+ (1,0) [0|255] "null" IPD
 SG_ IAM_100ms_Group18_RC : 11|4@0+ (1,0) [0|15] "null" IPD
 SG_ IAM_100ms_Group18_Reserved15 : 15|4@0+ (1,0) [0|15] "null" IPD
 SG_ PitchRTK : 23|16@0- (0.01,0) [-327.68|327.67] "null" IPD
 SG_ HeadingSigma : 39|16@0+ (0.001,0) [0.000|65.535] "null" IPD
 SG_ PitchSigma : 55|16@0+ (0.001,0) [0.000|65.535] "null" IPD

BO_ 1358 IAM_CONNCAN_100ms_FrS21: 8 Vector__XXX
 SG_ KeyDeleResp : 43|4@0+ (1,0) [0|15] "null" Vector__XXX
 SG_ AIParkngReq : 55|8@0+ (1,0) [0|255] "null" IPD

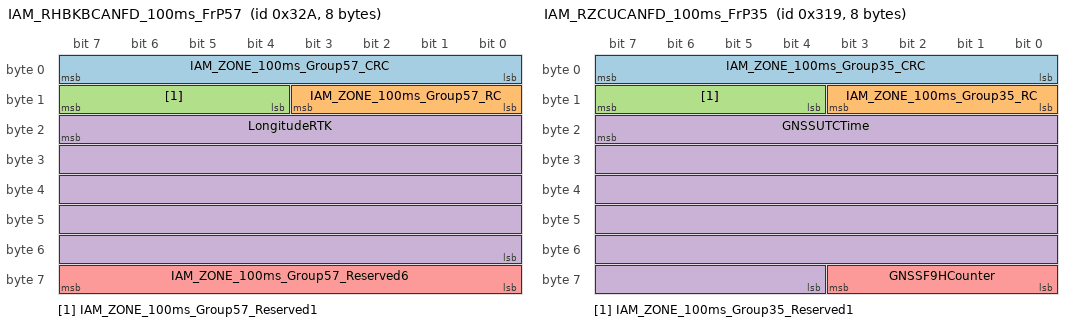
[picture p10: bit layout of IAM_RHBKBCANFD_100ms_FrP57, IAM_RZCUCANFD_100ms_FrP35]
BO_ 810 IAM_RHBKBCANFD_100ms_FrP57: 8 Vector__XXX
 SG_ IAM_ZONE_100ms_Group57_CRC : 7|8@0+ (1,0) [0|255] "null" IPD
 SG_ IAM_ZONE_100ms_Group57_RC : 11|4@0+ (1,0) [0|15] "null" IPD
 SG_ IAM_ZONE_100ms_Group57_Reserved1 : 15|4@0+ (1,0) [0|15] "null" IPD
 SG_ LongitudeRTK : 23|40@0- (1.0E-009,0) [-549.7558138880|549.7558138870] "null" IPD
 SG_ IAM_ZONE_100ms_Group57_Reserved6 : 63|8@0+ (1,0) [0|255] "null" IPD

BO_ 793 IAM_RZCUCANFD_100ms_FrP35: 8 Vector__XXX
 SG_ IAM_ZONE_100ms_Group35_CRC : 7|8@0+ (1,0) [0|255] "null" IPD
 SG_ IAM_ZONE_100ms_Group35_RC : 11|4@0+ (1,0) [0|15] "null" IPD
 SG_ IAM_ZONE_100ms_Group35_Reserved1 : 15|4@0+ (1,0) [0|15] "null" IPD
 SG_ GNSSUTCTime : 23|44@0+ (1,0) [0|17592186044415] "null" IPD
 SG_ GNSSF9HCounter : 59|4@0+ (1,0) [0|15] "null" IPD

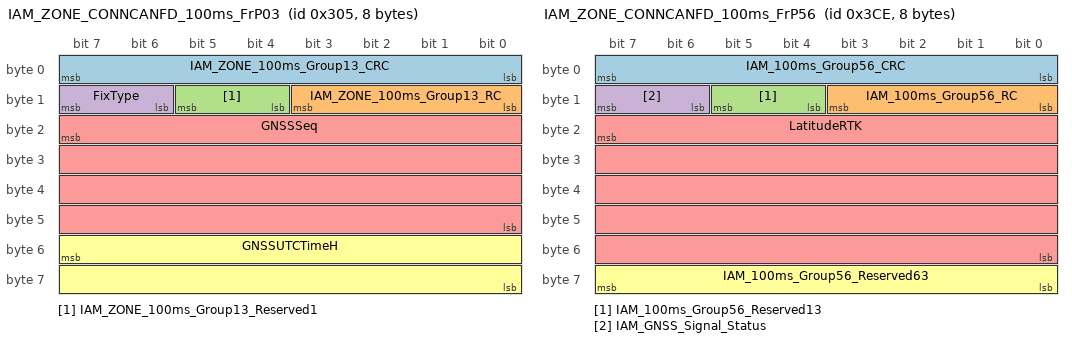
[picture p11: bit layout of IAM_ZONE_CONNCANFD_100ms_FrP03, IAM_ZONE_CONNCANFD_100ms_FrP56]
BO_ 773 IAM_ZONE_CONNCANFD_100ms_FrP03: 8 Vector__XXX
 SG_ IAM_ZONE_100ms_Group13_CRC : 7|8@0+ (1,0) [0|255] "null" IPD
 SG_ IAM_ZONE_100ms_Group13_RC : 11|4@0+ (1,0) [0|15] "null" IPD
 SG_ IAM_ZONE_100ms_Group13_Reserved1 : 13|2@0+ (1,0) [0|3] "null" IPD
 SG_ FixType : 15|2@0+ (1,0) [0|3] "null" IPD
 SG_ GNSSSeq : 23|32@0+ (1,0) [0|4294967295] "null" IPD
 SG_ GNSSUTCTimeH : 55|16@0+ (1,0) [0|65535] "null" IPD

BO_ 974 IAM_ZONE_CONNCANFD_100ms_FrP56: 8 Vector__XXX
 SG_ IAM_100ms_Group56_CRC : 7|8@0+ (1,0) [0|255] "null" IPD
 SG_ IAM_100ms_Group56_RC : 11|4@0+ (1,0) [0|15] "null" IPD
 SG_ IAM_100ms_Group56_Reserved13 : 13|2@0+ (1,0) [0|3] "null" IPD
 SG_ IAM_GNSS_Signal_Status : 15|2@0+ (1,0) [0|3] "null" IPD
 SG_ LatitudeRTK : 23|40@0- (1.0E-009,0) [-549.7558138880|549.7558138870] "null" IPD
 SG_ IAM_100ms_Group56_Reserved63 : 63|8@0+ (1,0) [0|255] "null" IPD

BO_ 348 ICBAD_BKPCANFD_100ms_FrP27: 16 IPD
 SG_ FCWSnstvtLvl : 15|3@0+ (1,0) [0|7] "null" Vector__XXX
 SG_ AEBDspCmd : 19|2@0+ (1,0) [0|3] "null" Vector__XXX
 SG_ AEBMsgReq : 23|4@0+ (1,0) [0|15] "null" Vector__XXX
 SG_ FCWDspCmd : 25|2@0+ (1,0) [0|3] "null" Vector__XXX
 SG_ FCWSysFltSts : 28|3@0+ (1,0) [0|7] "null" Vector__XXX
 SG_ FCWrnngSts : 31|3@0+ (1,0) [0|7] "null" Vector__XXX
 SG_ FCTSysFltSts : 81|2@0+ (1,0) [0|3] "null" Vector__XXX
 SG_ FCTSwSts : 86|3@0+ (1,0) [0|7] "null" Vector__XXX
 SG_ LFCTWrnng : 92|3@0+ (1,0) [0|7] "null" Vector__XXX
 SG_ RFCTWrnng : 95|3@0+ (1,0) [0|7] "null" Vector__XXX

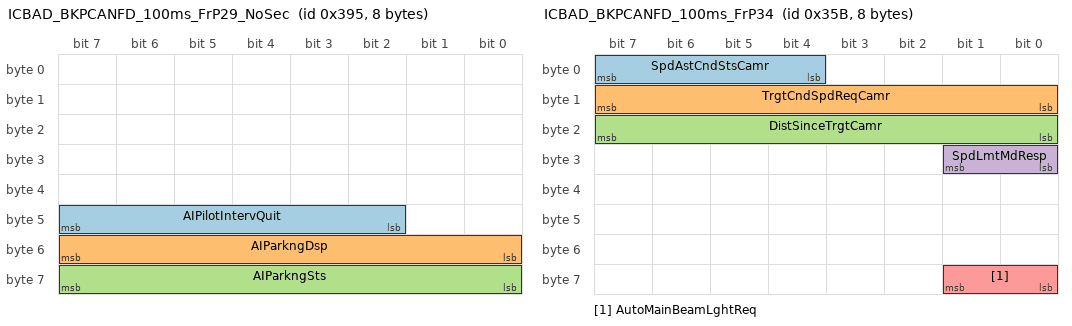
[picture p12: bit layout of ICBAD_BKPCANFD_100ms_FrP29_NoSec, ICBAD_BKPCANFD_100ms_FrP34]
BO_ 917 ICBAD_BKPCANFD_100ms_FrP29_NoSec: 8 IPD
 SG_ AIPilotIntervQuit : 47|6@0+ (1,0) [0|63] "null" Vector__XXX
 SG_ AIParkngDsp : 55|8@0+ (1,0) [0|255] "null" Vector__XXX
 SG_ AIParkngSts : 63|8@0+ (1,0) [0|255] "null" Vector__XXX

BO_ 859 ICBAD_BKPCANFD_100ms_FrP34: 8 IPD
 SG_ SpdAstCndStsCamr : 7|4@0+ (1,0) [0|15] "null" Vector__XXX
 SG_ TrgtCndSpdReqCamr : 15|8@0+ (1.5,0) [0|382.5] "kph/mph" Vector__XXX
 SG_ DistSinceTrgtCamr : 23|8@0+ (8.235,-100) [-100.000|1999.925] "null" Vector__XXX
 SG_ SpdLmtMdResp : 25|2@0+ (1,0) [0|3] "null" Vector__XXX
 SG_ AutoMainBeamLghtReq : 57|2@0+ (1,0) [0|3] "null" Vector__XXX

BO_ 895 ICBAD_BKPCANFD_100ms_FrP36: 16 IPD
 SG_ NarwSpcAstSwSts : 9|2@0+ (1,0) [0|3] "null" Vector__XXX
 SG_ IPDStsResp : 11|2@0+ (1,0) [0|3] "null" Vector__XXX
 SG_ NarwSpcAstBtnSts : 23|3@0+ (1,0) [0|7] "null" Vector__XXX
 SG_ IPD_VehLckCtrlReq : 31|8@0+ (1,0) [0|255] "null" Vector__XXX
 SG_ IPDMCUTemp : 71|8@0+ (1,-40) [-40|215] "" Vector__XXX
 SG_ IPDWtrClntInltReqFlg : 79|1@0+ (1,0) [0|1] "null" Vector__XXX
 SG_ TrfGreenLghtActn : 103|1@0+ (1,0) [0|1] "null" Vector__XXX

BA_DEF_ BO_ "FrameTriggeringName" STRING;
BA_DEF_ BO_ "GenMsgCycleTime" INT 0 65535;
BA_DEF_ BO_ "GenMsgDelayTime" INT 0 65535;
BA_DEF_ BO_ "GenMsgSendType" ENUM  "cyclicX","spontanX","cyclicIfActiveX","spontanWithDelay","cyclicAndSpontanX","cyclicAndSpontanWithDelay","spontanWithRepitition","cyclicIfActiveAndSpontanWD","cyclicIfActiveFast","cyclicWithRepeatOnDemand","none";
BA_DEF_ BO_ "GenMsgStartValue" STRING;
BA_DEF_ BO_ "PduName" STRING;
BA_DEF_ BO_ "SystemMessageLongSymbol" STRING;
BA_DEF_ BO_ "VFrameFormat" ENUM  "StandardCAN","ExtendedCAN","reserved","reserved","reserved","reserved","reserved","reserved","reserved","reserved","reserved","reserved","reserved","reserved","StandardCAN_FD","ExtendedCAN_FD";
BA_DEF_ SG_ "CompuMethodName" STRING;
BA_DEF_ SG_ "GenSigStartValue" FLOAT 0 100000000000;
BA_DEF_ SG_ "ISignalName" STRING;
BA_DEF_ SG_ "LongName" STRING;
BA_DEF_ SG_ "SysSignalName" STRING;
BA_DEF_ SG_ "SystemSignalLongSymbol" STRING;
BA_DEF_ BU_ "NWM-Knoten" ENUM  "nein","ja";
BA_DEF_ BU_ "NWM-Stationsadresse" HEX 0 63;
BA_DEF_  "BusType" STRING;
BA_ "NWM-Knoten" BU_ IPD 0;
BA_ "NWM-Stationsadresse" BU_ IPD 0;

BA_ "BusType"   "CAN FD";

BA_ "FrameTriggeringName" BO_ 882 "BCM_BDCAN_100ms_FrP41";
BA_ "GenMsgCycleTime" BO_ 882 100;
BA_ "GenMsgSendType" BO_ 882 0;
BA_ "GenMsgStartValue" BO_ 882 "0000000000000000";
BA_ "PduName" BO_ 882 "BCM_100ms_PDU41";
BA_ "VFrameFormat" BO_ 882 14;
BA_ "FrameTriggeringName" BO_ 1949 "DIAG_DTCInfo_ICBAD";
BA_ "GenMsgSendType" BO_ 1949 1;
BA_ "GenMsgStartValue" BO_ 1949 "0000000000000000";
BA_ "PduName" BO_ 1949 "DIAG_DTCInfo_ICBAD";
BA_ "VFrameFormat" BO_ 1949 14;
BA_ "FrameTriggeringName" BO_ 1319 "DKMM_LHBDCANFD_Event_FrS03";
BA_ "GenMsgDelayTime" BO_ 1319 10;
BA_ "GenMsgSendType" BO_ 1319 1;
BA_ "GenMsgStartValue" BO_ 1319 "0000000000000000";
BA_ "PduName" BO_ 1319 "DKMM_Sporadic_PDU03";
BA_ "VFrameFormat" BO_ 1319 14;
BA_ "FrameTriggeringName" BO_ 2015 "Diag_BKPCANFD_FuncReq_BKPCANFD";
BA_ "GenMsgSendType" BO_ 2015 1;
BA_ "GenMsgStartValue" BO_ 2015 "00000000000000000000000000000000000000000000000000000000000000000000000000000000000000000000000000000000000000000000000000000000";
BA_ "PduName" BO_ 2015 "Diag_BKPCANFD_FuncReq";
BA_ "VFrameFormat" BO_ 2015 14;
BA_ "FrameTriggeringName" BO_ 1845 "Diag_BKPCANFD_PhyReq_IPD_BKPCANFD";
BA_ "GenMsgSendType" BO_ 1845 1;
BA_ "GenMsgStartValue" BO_ 1845 "00000000000000000000000000000000000000000000000000000000000000000000000000000000000000000000000000000000000000000000000000000000";
BA_ "PduName" BO_ 1845 "Diag_BKPCANFD_PhyReq_IPD";
BA_ "VFrameFormat" BO_ 1845 14;
BA_ "FrameTriggeringName" BO_ 1853 "Diag_BKPCANFD_PhyResp_IPD_BKPCANFD";
BA_ "GenMsgSendType" BO_ 1853 1;
BA_ "GenMsgStartValue" BO_ 1853 "00000000000000000000000000000000000000000000000000000000000000000000000000000000000000000000000000000000000000000000000000000000";
BA_ "PduName" BO_ 1853 "Diag_BKPCANFD_PhyResp_IPD";
BA_ "VFrameFormat" BO_ 1853 14;
BA_ "FrameTriggeringName" BO_ 898 "FDR_BKPCANFD_100ms_FrP01";
BA_ "GenMsgCycleTime" BO_ 898 100;
BA_ "GenMsgSendType" BO_ 898 0;
BA_ "GenMsgStartValue" BO_ 898 "0010ffffffffffff";
BA_ "PduName" BO_ 898 "FDR_100ms_PDU01";
BA_ "VFrameFormat" BO_ 898 14;
BA_ "FrameTriggeringName" BO_ 1254 "FDR_BKPCANFD_NM";
BA_ "GenMsgSendType" BO_ 1254 1;
BA_ "GenMsgStartValue" BO_ 1254 "0000000000000000";
BA_ "PduName" BO_ 1254 "NmPDU_BKPCANFD_FDR";
BA_ "VFrameFormat" BO_ 1254 14;
BA_ "FrameTriggeringName" BO_ 958 "FVCM_BKPCANFD_100ms_FrP04";
BA_ "GenMsgCycleTime" BO_ 958 100;
BA_ "GenMsgSendType" BO_ 958 0;
BA_ "GenMsgStartValue" BO_ 958 "00000000000000000000000000000000000000000000006000000000000000000000000000000000000000000000000000000000000000000000000000000000";
BA_ "PduName" BO_ 958 "FVCM_100ms_PDU04";
BA_ "VFrameFormat" BO_ 958 14;
BA_ "FrameTriggeringName" BO_ 956 "FVCM_BKPCANFD_100ms_FrP05";
BA_ "GenMsgCycleTime" BO_ 956 100;
BA_ "GenMsgSendType" BO_ 956 0;
BA_ "GenMsgStartValue" BO_ 956 "00000000000000000000000000000000000000000000000000000000000000000000000000000000000000000000000000500000000000000000000000000000";
BA_ "PduName" BO_ 956 "FVCM_100ms_PDU05";
BA_ "VFrameFormat" BO_ 956 14;
BA_ "FrameTriggeringName" BO_ 307 "FVCM_BKPCANFD_20ms_FrP02";
BA_ "GenMsgCycleTime" BO_ 307 20;
BA_ "GenMsgSendType" BO_ 307 0;
BA_ "GenMsgStartValue" BO_ 307 "00f0753000000160ffe0000007fc03ff";
BA_ "PduName" BO_ 307 "FVCM_20ms_PDU02";
BA_ "VFrameFormat" BO_ 307 14;
BA_ "FrameTriggeringName" BO_ 1381 "IAM_BKPCANFD_1000ms_FrP49";
BA_ "GenMsgCycleTime" BO_ 1381 1000;
BA_ "GenMsgSendType" BO_ 1381 0;
BA_ "GenMsgStartValue" BO_ 1381 "0000000000000000";
BA_ "PduName" BO_ 1381 "IAM_ZONE_1000ms_PDU49";
BA_ "VFrameFormat" BO_ 1381 14;
BA_ "FrameTriggeringName" BO_ 1374 "IAM_BKPCANFD_1000ms_FrP55";
BA_ "GenMsgCycleTime" BO_ 1374 1000;
BA_ "GenMsgSendType" BO_ 1374 0;
BA_ "GenMsgStartValue" BO_ 1374 "0000000000000000";
BA_ "PduName" BO_ 1374 "IAM_ZONE_1000ms_PDU55";
BA_ "VFrameFormat" BO_ 1374 14;
BA_ "FrameTriggeringName" BO_ 1375 "IAM_BKPCANFD_1000ms_FrP58";
BA_ "GenMsgCycleTime" BO_ 1375 1000;
BA_ "GenMsgSendType" BO_ 1375 0;
BA_ "GenMsgStartValue" BO_ 1375 "0000000000000000";
BA_ "PduName" BO_ 1375 "IAM_ZONE_1000ms_PDU58";
BA_ "VFrameFormat" BO_ 1375 14;
BA_ "FrameTriggeringName" BO_ 1382 "IAM_BKPCANFD_1000ms_FrP59";
BA_ "GenMsgCycleTime" BO_ 1382 1000;
BA_ "GenMsgSendType" BO_ 1382 0;
BA_ "GenMsgStartValue" BO_ 1382 "0000000000000000";
BA_ "PduName" BO_ 1382 "IAM_ZONE_1000ms_PDU59";
BA_ "VFrameFormat" BO_ 1382 14;
BA_ "FrameTriggeringName" BO_ 1383 "IAM_BKPCANFD_1000ms_FrP60";
BA_ "GenMsgCycleTime" BO_ 1383 1000;
BA_ "GenMsgSendType" BO_ 1383 0;
BA_ "GenMsgStartValue" BO_ 1383 "0000000000000000";
BA_ "PduName" BO_ 1383 "IAM_ZONE_1000ms_PDU60";
BA_ "VFrameFormat" BO_ 1383 14;
BA_ "FrameTriggeringName" BO_ 1384 "IAM_BKPCANFD_1000ms_FrP61";
BA_ "GenMsgCycleTime" BO_ 1384 1000;
BA_ "GenMsgSendType" BO_ 1384 0;
BA_ "GenMsgStartValue" BO_ 1384 "0000000000000000";
BA_ "PduName" BO_ 1384 "IAM_ZONE_1000ms_PDU61";
BA_ "VFrameFormat" BO_ 1384 14;
BA_ "FrameTriggeringName" BO_ 1385 "IAM_BKPCANFD_1000ms_FrP62";
BA_ "GenMsgCycleTime" BO_ 1385 1000;
BA_ "GenMsgSendType" BO_ 1385 0;
BA_ "GenMsgStartValue" BO_ 1385 "0000000000000000";
BA_ "PduName" BO_ 1385 "IAM_ZONE_1000ms_PDU62";
BA_ "VFrameFormat" BO_ 1385 14;
BA_ "FrameTriggeringName" BO_ 1386 "IAM_BKPCANFD_1000ms_FrP63";
BA_ "GenMsgCycleTime" BO_ 1386 1000;
BA_ "GenMsgSendType" BO_ 1386 0;
BA_ "GenMsgStartValue" BO_ 1386 "0000000000000000";
BA_ "PduName" BO_ 1386 "IAM_ZONE_1000ms_PDU63";
BA_ "VFrameFormat" BO_ 1386 14;
BA_ "FrameTriggeringName" BO_ 1387 "IAM_BKPCANFD_1000ms_FrP64";
BA_ "GenMsgCycleTime" BO_ 1387 1000;
BA_ "GenMsgSendType" BO_ 1387 0;
BA_ "GenMsgStartValue" BO_ 1387 "0000000000000000";
BA_ "PduName" BO_ 1387 "IAM_ZONE_1000ms_PDU64";
BA_ "VFrameFormat" BO_ 1387 14;
BA_ "FrameTriggeringName" BO_ 1388 "IAM_BKPCANFD_1000ms_FrP65";
BA_ "GenMsgCycleTime" BO_ 1388 1000;
BA_ "GenMsgSendType" BO_ 1388 0;
BA_ "GenMsgStartValue" BO_ 1388 "0000000000000000";
BA_ "PduName" BO_ 1388 "IAM_ZONE_1000ms_PDU65";
BA_ "VFrameFormat" BO_ 1388 14;
BA_ "FrameTriggeringName" BO_ 1380 "IAM_BKPCANFD_1000ms_FrP66";
BA_ "GenMsgCycleTime" BO_ 1380 1000;
BA_ "GenMsgSendType" BO_ 1380 0;
BA_ "GenMsgStartValue" BO_ 1380 "0000000000000000";
BA_ "PduName" BO_ 1380 "IAM_ZONE_1000ms_PDU66";
BA_ "VFrameFormat" BO_ 1380 14;
BA_ "FrameTriggeringName" BO_ 1082 "IAM_CONNCANFD_100ms_FrP03";
BA_ "GenMsgCycleTime" BO_ 1082 100;
BA_ "GenMsgSendType" BO_ 1082 0;
BA_ "GenMsgStartValue" BO_ 1082 "0000000000000000";
BA_ "PduName" BO_ 1082 "IAM_100ms_PDU03";
BA_ "VFrameFormat" BO_ 1082 14;
BA_ "FrameTriggeringName" BO_ 766 "IAM_CONNCANFD_100ms_FrP06";
BA_ "GenMsgCycleTime" BO_ 766 100;
BA_ "GenMsgSendType" BO_ 766 0;
BA_ "GenMsgStartValue" BO_ 766 "0000000000000000";
BA_ "PduName" BO_ 766 "IAM_100ms_PDU06";
BA_ "VFrameFormat" BO_ 766 14;
BA_ "FrameTriggeringName" BO_ 335 "IAM_CONNCANFD_100ms_FrP07";
BA_ "GenMsgCycleTime" BO_ 335 100;
BA_ "GenMsgSendType" BO_ 335 0;
BA_ "GenMsgStartValue" BO_ 335 "0000000000000000";
BA_ "PduName" BO_ 335 "IAM_100ms_PDU07";
BA_ "VFrameFormat" BO_ 335 14;
BA_ "FrameTriggeringName" BO_ 887 "IAM_CONNCANFD_100ms_FrP08";
BA_ "GenMsgCycleTime" BO_ 887 100;
BA_ "GenMsgSendType" BO_ 887 0;
BA_ "GenMsgStartValue" BO_ 887 "00f0000000000000";
BA_ "PduName" BO_ 887 "IAM_100ms_PDU08";
BA_ "VFrameFormat" BO_ 887 14;
BA_ "FrameTriggeringName" BO_ 912 "IAM_CONNCANFD_100ms_FrP34";
BA_ "GenMsgCycleTime" BO_ 912 100;
BA_ "GenMsgSendType" BO_ 912 0;
BA_ "GenMsgStartValue" BO_ 912 "00f0c000c000c000";
BA_ "PduName" BO_ 912 "IAM_ZONE_100ms_PDU34";
BA_ "VFrameFormat" BO_ 912 14;
BA_ "FrameTriggeringName" BO_ 874 "IAM_CONNCANFD_100ms_FrP40";
BA_ "GenMsgCycleTime" BO_ 874 100;
BA_ "GenMsgSendType" BO_ 874 0;
BA_ "GenMsgStartValue" BO_ 874 "00f00000000000ff";
BA_ "PduName" BO_ 874 "IAM_ZONE_100ms_PDU40";
BA_ "VFrameFormat" BO_ 874 14;
BA_ "FrameTriggeringName" BO_ 336 "IAM_CONNCANFD_20ms_FrP32";
BA_ "GenMsgCycleTime" BO_ 336 20;
BA_ "GenMsgSendType" BO_ 336 0;
BA_ "GenMsgStartValue" BO_ 336 "0000008000100fffffffffffffffffff";
BA_ "PduName" BO_ 336 "IAM_20ms_PDU32";
BA_ "VFrameFormat" BO_ 336 14;
BA_ "FrameTriggeringName" BO_ 89 "IAM_CONNCANFD_Event_FrS04";
BA_ "GenMsgSendType" BO_ 89 1;
BA_ "GenMsgStartValue" BO_ 89 "00000000000000000000000000000000";
BA_ "PduName" BO_ 89 "IAM_Sporadic_PDU04";
BA_ "VFrameFormat" BO_ 89 14;
BA_ "FrameTriggeringName" BO_ 1000 "IAM_CONNCAN_100ms_FrP04";
BA_ "GenMsgCycleTime" BO_ 1000 100;
BA_ "GenMsgSendType" BO_ 1000 0;
BA_ "GenMsgStartValue" BO_ 1000 "0000000000000000";
BA_ "PduName" BO_ 1000 "IAM_100ms_PDU04";
BA_ "VFrameFormat" BO_ 1000 14;
BA_ "FrameTriggeringName" BO_ 811 "IAM_CONNCAN_100ms_FrP18";
BA_ "GenMsgCycleTime" BO_ 811 100;
BA_ "GenMsgSendType" BO_ 811 0;
BA_ "GenMsgStartValue" BO_ 811 "00f0000000000000";
BA_ "PduName" BO_ 811 "IAM_100ms_PDU18";
BA_ "VFrameFormat" BO_ 811 14;
BA_ "FrameTriggeringName" BO_ 1358 "IAM_CONNCAN_100ms_FrS21";
BA_ "GenMsgCycleTime" BO_ 1358 100;
BA_ "GenMsgSendType" BO_ 1358 0;
BA_ "GenMsgStartValue" BO_ 1358 "0000000000000000";
BA_ "PduName" BO_ 1358 "IAM_100ms_PDU21";
BA_ "VFrameFormat" BO_ 1358 14;
BA_ "FrameTriggeringName" BO_ 810 "IAM_RHBKBCANFD_100ms_FrP57";
BA_ "GenMsgCycleTime" BO_ 810 100;
BA_ "GenMsgSendType" BO_ 810 0;
BA_ "GenMsgStartValue" BO_ 810 "00f00000000000ff";
BA_ "PduName" BO_ 810 "IAM_ZONE_100ms_PDU57";
BA_ "VFrameFormat" BO_ 810 14;
BA_ "FrameTriggeringName" BO_ 793 "IAM_RZCUCANFD_100ms_FrP35";
BA_ "GenMsgCycleTime" BO_ 793 100;
BA_ "GenMsgSendType" BO_ 793 0;
BA_ "GenMsgStartValue" BO_ 793 "00f0000000000000";
BA_ "PduName" BO_ 793 "IAM_ZONE_100ms_PDU35";
BA_ "VFrameFormat" BO_ 793 14;
BA_ "FrameTriggeringName" BO_ 773 "IAM_ZONE_CONNCANFD_100ms_FrP03";
BA_ "GenMsgCycleTime" BO_ 773 100;
BA_ "GenMsgSendType" BO_ 773 0;
BA_ "GenMsgStartValue" BO_ 773 "0030000000000000";
BA_ "PduName" BO_ 773 "IAM_ZONE_100ms_PDU13";
BA_ "VFrameFormat" BO_ 773 14;
BA_ "FrameTriggeringName" BO_ 974 "IAM_ZONE_CONNCANFD_100ms_FrP56";
BA_ "GenMsgCycleTime" BO_ 974 100;
BA_ "GenMsgSendType" BO_ 974 0;
BA_ "GenMsgStartValue" BO_ 974 "00300000000000ff";
BA_ "PduName" BO_ 974 "IAM_ZONE_100ms_PDU56";
BA_ "VFrameFormat" BO_ 974 14;
BA_ "FrameTriggeringName" BO_ 348 "ICBAD_BKPCANFD_100ms_FrP27";
BA_ "GenMsgCycleTime" BO_ 348 100;
BA_ "GenMsgSendType" BO_ 348 0;
BA_ "GenMsgStartValue" BO_ 348 "00400802000000000000100000000000";
BA_ "PduName" BO_ 348 "ICBAD_100ms_PDU27";
BA_ "VFrameFormat" BO_ 348 14;
BA_ "FrameTriggeringName" BO_ 917 "ICBAD_BKPCANFD_100ms_FrP29_NoSecOC";
BA_ "GenMsgCycleTime" BO_ 917 100;
BA_ "GenMsgSendType" BO_ 917 0;
BA_ "GenMsgStartValue" BO_ 917 "0000000000000000";
BA_ "PduName" BO_ 917 "ICBAD_100ms_PDU29";
BA_ "SystemMessageLongSymbol" BO_ 917 "ICBAD_BKPCANFD_100ms_FrP29_NoSecOC";
BA_ "VFrameFormat" BO_ 917 14;
BA_ "FrameTriggeringName" BO_ 859 "ICBAD_BKPCANFD_100ms_FrP34";
BA_ "GenMsgCycleTime" BO_ 859 100;
BA_ "GenMsgSendType" BO_ 859 0;
BA_ "GenMsgStartValue" BO_ 859 "0000000000000000";
BA_ "PduName" BO_ 859 "ICBAD_100ms_PDU34";
BA_ "VFrameFormat" BO_ 859 14;
BA_ "FrameTriggeringName" BO_ 895 "ICBAD_BKPCANFD_100ms_FrP36";
BA_ "GenMsgCycleTime" BO_ 895 100;
BA_ "GenMsgSendType" BO_ 895 0;
BA_ "GenMsgStartValue" BO_ 895 "0002000000000000ff00000000000000";
BA_ "PduName" BO_ 895 "ICBAD_100ms_PDU36";
BA_ "VFrameFormat" BO_ 895 14;

BA_ "CompuMethodName" SG_ 882 RrTireStdPrs "RrTireStdPrs";
BA_ "ISignalName" SG_ 882 RrTireStdPrs "IRrTireStdPrs";
BA_ "LongName" SG_ 882 RrTireStdPrs "Rear_Tire_Standard_Pressure";
BA_ "SysSignalName" SG_ 882 RrTireStdPrs "RrTireStdPrs";
BA_ "CompuMethodName" SG_ 882 FrtTireStdPrs "FrtTireStdPrs";
BA_ "ISignalName" SG_ 882 FrtTireStdPrs "IFrtTireStdPrs";
BA_ "LongName" SG_ 882 FrtTireStdPrs "Front Tire Standard Pressure";
BA_ "SysSignalName" SG_ 882 FrtTireStdPrs "FrtTireStdPrs";
BA_ "CompuMethodName" SG_ 1949 DTCInfomationIPD "DTCInfomationIPD";
BA_ "ISignalName" SG_ 1949 DTCInfomationIPD "IDTCInfomationIPD";
BA_ "LongName" SG_ 1949 DTCInfomationIPD "Diagnostic Trouble Code Information IPD";
BA_ "SysSignalName" SG_ 1949 DTCInfomationIPD "DTCInfomationIPD";
BA_ "CompuMethodName" SG_ 1319 AIParkngSpcID "AIParkngSpcID";
BA_ "ISignalName" SG_ 1319 AIParkngSpcID "IAIParkngSpcID";
BA_ "LongName" SG_ 1319 AIParkngSpcID "AI_Parking_Space_ID";
BA_ "SysSignalName" SG_ 1319 AIParkngSpcID "AIParkngSpcID";
BA_ "CompuMethodName" SG_ 898 FDR_100ms_Group01_CRC "FDR_100ms_Group01_CRC";
BA_ "ISignalName" SG_ 898 FDR_100ms_Group01_CRC "IFDR_100ms_Group01_CRC";
BA_ "SysSignalName" SG_ 898 FDR_100ms_Group01_CRC "FDR_100ms_Group01_CRC";
BA_ "CompuMethodName" SG_ 898 FDR_100ms_Group01_RC "FDR_100ms_Group01_RC";
BA_ "ISignalName" SG_ 898 FDR_100ms_Group01_RC "IFDR_100ms_Group01_RC";
BA_ "SysSignalName" SG_ 898 FDR_100ms_Group01_RC "FDR_100ms_Group01_RC";
BA_ "CompuMethodName" SG_ 898 FDR_100ms_Group01_Reserved1 "FDR_100ms_Group01_Reserved1";
BA_ "GenSigStartValue" SG_ 898 FDR_100ms_Group01_Reserved1 1;
BA_ "ISignalName" SG_ 898 FDR_100ms_Group01_Reserved1 "IFDR_100ms_Group01_Reserved1";
BA_ "SysSignalName" SG_ 898 FDR_100ms_Group01_Reserved1 "FDR_100ms_Group01_Reserved1";
BA_ "CompuMethodName" SG_ 898 FDRSts "FDRSts";
BA_ "ISignalName" SG_ 898 FDRSts "IFDRSts";
BA_ "LongName" SG_ 898 FDRSts "FDR Status";
BA_ "SysSignalName" SG_ 898 FDRSts "FDRSts";
BA_ "CompuMethodName" SG_ 898 FDR_100ms_Group01_Reserved2 "FDR_100ms_Group01_Reserved2";
BA_ "GenSigStartValue" SG_ 898 FDR_100ms_Group01_Reserved2 255;
BA_ "ISignalName" SG_ 898 FDR_100ms_Group01_Reserved2 "IFDR_100ms_Group01_Reserved2";
BA_ "SysSignalName" SG_ 898 FDR_100ms_Group01_Reserved2 "FDR_100ms_Group01_Reserved2";
BA_ "CompuMethodName" SG_ 898 FDR_100ms_Group01_Reserved3 "FDR_100ms_Group01_Reserved3";
BA_ "GenSigStartValue" SG_ 898 FDR_100ms_Group01_Reserved3 255;
BA_ "ISignalName" SG_ 898 FDR_100ms_Group01_Reserved3 "IFDR_100ms_Group01_Reserved3";
BA_ "SysSignalName" SG_ 898 FDR_100ms_Group01_Reserved3 "FDR_100ms_Group01_Reserved3";
BA_ "CompuMethodName" SG_ 898 FDR_100ms_Group01_Reserved4 "FDR_100ms_Group01_Reserved4";
BA_ "GenSigStartValue" SG_ 898 FDR_100ms_Group01_Reserved4 255;
BA_ "ISignalName" SG_ 898 FDR_100ms_Group01_Reserved4 "IFDR_100ms_Group01_Reserved4";
BA_ "SysSignalName" SG_ 898 FDR_100ms_Group01_Reserved4 "FDR_100ms_Group01_Reserved4";
BA_ "CompuMethodName" SG_ 898 FDR_100ms_Group01_Reserved5 "FDR_100ms_Group01_Reserved5";
BA_ "GenSigStartValue" SG_ 898 FDR_100ms_Group01_Reserved5 255;
BA_ "ISignalName" SG_ 898 FDR_100ms_Group01_Reserved5 "IFDR_100ms_Group01_Reserved5";
BA_ "SysSignalName" SG_ 898 FDR_100ms_Group01_Reserved5 "FDR_100ms_Group01_Reserved5";
BA_ "CompuMethodName" SG_ 898 FDR_100ms_Group01_Reserved6 "FDR_100ms_Group01_Reserved6";
BA_ "GenSigStartValue" SG_ 898 FDR_100ms_Group01_Reserved6 255;
BA_ "ISignalName" SG_ 898 FDR_100ms_Group01_Reserved6 "IFDR_100ms_Group01_Reserved6";
BA_ "SysSignalName" SG_ 898 FDR_100ms_Group01_Reserved6 "FDR_100ms_Group01_Reserved6";
BA_ "CompuMethodName" SG_ 898 FDR_100ms_Group01_Reserved7 "FDR_100ms_Group01_Reserved7";
BA_ "GenSigStartValue" SG_ 898 FDR_100ms_Group01_Reserved7 255;
BA_ "ISignalName" SG_ 898 FDR_100ms_Group01_Reserved7 "IFDR_100ms_Group01_Reserved7";
BA_ "SysSignalName" SG_ 898 FDR_100ms_Group01_Reserved7 "FDR_100ms_Group01_Reserved7";
BA_ "CompuMethodName" SG_ 1254 FDR_NM_BSMtoRMS_BKPCANFD "FDR_NM_BSMtoRMS_BKPCANFD";
BA_ "ISignalName" SG_ 1254 FDR_NM_BSMtoRMS_BKPCANFD "IFDR_NM_BSMtoRMS_BKPCANFD";
BA_ "LongName" SG_ 1254 FDR_NM_BSMtoRMS_BKPCANFD "FDR_NM_BSMtoRMS_BKPCANFD";
BA_ "SysSignalName" SG_ 1254 FDR_NM_BSMtoRMS_BKPCANFD "FDR_NM_BSMtoRMS_BKPCANFD";
BA_ "CompuMethodName" SG_ 1254 FDR_NM_PBSMtoRMS_BKPCANFD "FDR_NM_PBSMtoRMS_BKPCANFD";
BA_ "ISignalName" SG_ 1254 FDR_NM_PBSMtoRMS_BKPCANFD "IFDR_NM_PBSMtoRMS_BKPCANFD";
BA_ "LongName" SG_ 1254 FDR_NM_PBSMtoRMS_BKPCANFD "FDR_NM_PBSMtoRMS_BKPCANFD";
BA_ "SysSignalName" SG_ 1254 FDR_NM_PBSMtoRMS_BKPCANFD "FDR_NM_PBSMtoRMS_BKPCANFD";
BA_ "CompuMethodName" SG_ 1254 FDR_NM_RMStoNOS_BKPCANFD "FDR_NM_RMStoNOS_BKPCANFD";
BA_ "ISignalName" SG_ 1254 FDR_NM_RMStoNOS_BKPCANFD "IFDR_NM_RMStoNOS_BKPCANFD";
BA_ "LongName" SG_ 1254 FDR_NM_RMStoNOS_BKPCANFD "FDR_NM_RMStoNOS_BKPCANFD";
BA_ "SysSignalName" SG_ 1254 FDR_NM_RMStoNOS_BKPCANFD "FDR_NM_RMStoNOS_BKPCANFD";
BA_ "CompuMethodName" SG_ 1254 FDR_NM_RSStoNOS_BKPCANFD "FDR_NM_RSStoNOS_BKPCANFD";
BA_ "ISignalName" SG_ 1254 FDR_NM_RSStoNOS_BKPCANFD "IFDR_NM_RSStoNOS_BKPCANFD";
BA_ "LongName" SG_ 1254 FDR_NM_RSStoNOS_BKPCANFD "FDR_NM_RSStoNOS_BKPCANFD";
BA_ "SysSignalName" SG_ 1254 FDR_NM_RSStoNOS_BKPCANFD "FDR_NM_RSStoNOS_BKPCANFD";
BA_ "CompuMethodName" SG_ 1254 FDR_NM_RSStoRMS_BKPCANFD "FDR_NM_RSStoRMS_BKPCANFD";
BA_ "ISignalName" SG_ 1254 FDR_NM_RSStoRMS_BKPCANFD "IFDR_NM_RSStoRMS_BKPCANFD";
BA_ "LongName" SG_ 1254 FDR_NM_RSStoRMS_BKPCANFD "FDR_NM_RSStoRMS_BKPCANFD";
BA_ "SysSignalName" SG_ 1254 FDR_NM_RSStoRMS_BKPCANFD "FDR_NM_RSStoRMS_BKPCANFD";
BA_ "CompuMethodName" SG_ 1254 FDR_NM_NOStoRMS_BKPCANFD "FDR_NM_NOStoRMS_BKPCANFD";
BA_ "ISignalName" SG_ 1254 FDR_NM_NOStoRMS_BKPCANFD "IFDR_NM_NOStoRMS_BKPCANFD";
BA_ "LongName" SG_ 1254 FDR_NM_NOStoRMS_BKPCANFD "FDR_NM_NOStoRMS_BKPCANFD";
BA_ "SysSignalName" SG_ 1254 FDR_NM_NOStoRMS_BKPCANFD "FDR_NM_NOStoRMS_BKPCANFD";
BA_ "CompuMethodName" SG_ 1254 FDR_NM_NOSSta_BKPCANFD "FDR_NM_NOSSta_BKPCANFD";
BA_ "ISignalName" SG_ 1254 FDR_NM_NOSSta_BKPCANFD "IFDR_NM_NOSSta_BKPCANFD";
BA_ "LongName" SG_ 1254 FDR_NM_NOSSta_BKPCANFD "FDR_NM_NOSSta_BKPCANFD";
BA_ "SysSignalName" SG_ 1254 FDR_NM_NOSSta_BKPCANFD "FDR_NM_NOSSta_BKPCANFD";
BA_ "CompuMethodName" SG_ 1254 FDR_NM_RMSSta_BKPCANFD "FDR_NM_RMSSta_BKPCANFD";
BA_ "ISignalName" SG_ 1254 FDR_NM_RMSSta_BKPCANFD "IFDR_NM_RMSSta_BKPCANFD";
BA_ "LongName" SG_ 1254 FDR_NM_RMSSta_BKPCANFD "FDR_NM_RMSSta_BKPCANFD";
BA_ "SysSignalName" SG_ 1254 FDR_NM_RMSSta_BKPCANFD "FDR_NM_RMSSta_BKPCANFD";
BA_ "CompuMethodName" SG_ 1254 FDR_NWI_BKPCANFD "FDR_NWI_BKPCANFD";
BA_ "ISignalName" SG_ 1254 FDR_NWI_BKPCANFD "IFDR_NWI_BKPCANFD";
BA_ "LongName" SG_ 1254 FDR_NWI_BKPCANFD "FDR BKPCANFD Network_Wakeup_Indication";
BA_ "SysSignalName" SG_ 1254 FDR_NWI_BKPCANFD "FDR_NWI_BKPCANFD";
BA_ "CompuMethodName" SG_ 1254 FDR_NOI_BKPCANFD "FDR_NOI_BKPCANFD";
BA_ "ISignalName" SG_ 1254 FDR_NOI_BKPCANFD "IFDR_NOI_BKPCANFD";
BA_ "LongName" SG_ 1254 FDR_NOI_BKPCANFD "FDR BKPCANFD Network Operation Indication";
BA_ "SysSignalName" SG_ 1254 FDR_NOI_BKPCANFD "FDR_NOI_BKPCANFD";
BA_ "CompuMethodName" SG_ 1254 FDR_NKI_BKPCANFD "FDR_NKI_BKPCANFD";
BA_ "ISignalName" SG_ 1254 FDR_NKI_BKPCANFD "IFDR_NKI_BKPCANFD";
BA_ "LongName" SG_ 1254 FDR_NKI_BKPCANFD "FDR BKPCANFD Network Keep Indication";
BA_ "SysSignalName" SG_ 1254 FDR_NKI_BKPCANFD "FDR_NKI_BKPCANFD";
BA_ "CompuMethodName" SG_ 958 ACCDetObj1LatRltvDist "ACCDetObj1LatRltvDist";
BA_ "ISignalName" SG_ 958 ACCDetObj1LatRltvDist "IACCDetObj1LatRltvDist";
BA_ "LongName" SG_ 958 ACCDetObj1LatRltvDist "Adaptive_Cruise_Control_Detected_Object_1_Lateral_Relative_Distance";
BA_ "SysSignalName" SG_ 958 ACCDetObj1LatRltvDist "ACCDetObj1LatRltvDist";
BA_ "CompuMethodName" SG_ 958 ACCDetObj1Risk "ACCDetObj1Risk";
BA_ "ISignalName" SG_ 958 ACCDetObj1Risk "IACCDetObj1Risk";
BA_ "LongName" SG_ 958 ACCDetObj1Risk "Adaptive_Cruise_Control_Detected_Object_1_Risk";
BA_ "SysSignalName" SG_ 958 ACCDetObj1Risk "ACCDetObj1Risk";
BA_ "CompuMethodName" SG_ 958 ACCDetObj2LatRltvDist "ACCDetObj2LatRltvDist";
BA_ "ISignalName" SG_ 958 ACCDetObj2LatRltvDist "IACCDetObj2LatRltvDist";
BA_ "LongName" SG_ 958 ACCDetObj2LatRltvDist "Adaptive_Cruise_Control_Detected_Object_2_Lateral_Relative_Distance";
BA_ "SysSignalName" SG_ 958 ACCDetObj2LatRltvDist "ACCDetObj2LatRltvDist";
BA_ "CompuMethodName" SG_ 958 ACCDetObj2Risk "ACCDetObj2Risk";
BA_ "ISignalName" SG_ 958 ACCDetObj2Risk "IACCDetObj2Risk";
BA_ "LongName" SG_ 958 ACCDetObj2Risk "Adaptive_Cruise_Control_Detected_Object_2_Risk";
BA_ "SysSignalName" SG_ 958 ACCDetObj2Risk "ACCDetObj2Risk";
BA_ "CompuMethodName" SG_ 958 ACCDetObj3LatRltvDist "ACCDetObj3LatRltvDist";
BA_ "ISignalName" SG_ 958 ACCDetObj3LatRltvDist "IACCDetObj3LatRltvDist";
BA_ "LongName" SG_ 958 ACCDetObj3LatRltvDist "Adaptive_Cruise_Control_Detected_Object_3_Lateral_Relative_Distance";
BA_ "SysSignalName" SG_ 958 ACCDetObj3LatRltvDist "ACCDetObj3LatRltvDist";
BA_ "CompuMethodName" SG_ 958 ACCDetObj3Risk "ACCDetObj3Risk";
BA_ "ISignalName" SG_ 958 ACCDetObj3Risk "IACCDetObj3Risk";
BA_ "LongName" SG_ 958 ACCDetObj3Risk "Adaptive_Cruise_Control_Detected_Object_3_Risk";
BA_ "SysSignalName" SG_ 958 ACCDetObj3Risk "ACCDetObj3Risk";
BA_ "CompuMethodName" SG_ 958 ACCDetObj1LongtRltvDist "ACCDetObj1LongtRltvDist";
BA_ "ISignalName" SG_ 958 ACCDetObj1LongtRltvDist "IACCDetObj1LongtRltvDist";
BA_ "LongName" SG_ 958 ACCDetObj1LongtRltvDist "Adaptive_Cruise_Control_Detected_Object_1_Longitudinal_Relative_Distance";
BA_ "SysSignalName" SG_ 958 ACCDetObj1LongtRltvDist "ACCDetObj1LongtRltvDist";
BA_ "CompuMethodName" SG_ 958 ACCDetObj1LongtRltvSpd "ACCDetObj1LongtRltvSpd";
BA_ "ISignalName" SG_ 958 ACCDetObj1LongtRltvSpd "IACCDetObj1LongtRltvSpd";
BA_ "LongName" SG_ 958 ACCDetObj1LongtRltvSpd "Adaptive_Cruise_Control_Detected_Object_1_Longitudinal_Relative_Speed";
BA_ "SysSignalName" SG_ 958 ACCDetObj1LongtRltvSpd "ACCDetObj1LongtRltvSpd";
BA_ "CompuMethodName" SG_ 958 ACCDetObj2LongtRltvDist "ACCDetObj2LongtRltvDist";
BA_ "ISignalName" SG_ 958 ACCDetObj2LongtRltvDist "IACCDetObj2LongtRltvDist";
BA_ "LongName" SG_ 958 ACCDetObj2LongtRltvDist "Adaptive_Cruise_Control_Detected_Object_2_Longitudinal_Relative_Distance";
BA_ "SysSignalName" SG_ 958 ACCDetObj2LongtRltvDist "ACCDetObj2LongtRltvDist";
BA_ "CompuMethodName" SG_ 958 ACCDetObj2LongtRltvSpd "ACCDetObj2LongtRltvSpd";
BA_ "ISignalName" SG_ 958 ACCDetObj2LongtRltvSpd "IACCDetObj2LongtRltvSpd";
BA_ "LongName" SG_ 958 ACCDetObj2LongtRltvSpd "Adaptive_Cruise_Control_Detected_Object_2_Longitudinal_Relative_Speed";
BA_ "SysSignalName" SG_ 958 ACCDetObj2LongtRltvSpd "ACCDetObj2LongtRltvSpd";
BA_ "CompuMethodName" SG_ 958 ACCDetObj3LongtRltvDist "ACCDetObj3LongtRltvDist";
BA_ "ISignalName" SG_ 958 ACCDetObj3LongtRltvDist "IACCDetObj3LongtRltvDist";
BA_ "LongName" SG_ 958 ACCDetObj3LongtRltvDist "Adaptive_Cruise_Control_Detected_Object_3_Longitudinal_Relative_Distance";
BA_ "SysSignalName" SG_ 958 ACCDetObj3LongtRltvDist "ACCDetObj3LongtRltvDist";
BA_ "CompuMethodName" SG_ 958 ACCDetObj3LongtRltvSpd "ACCDetObj3LongtRltvSpd";
BA_ "ISignalName" SG_ 958 ACCDetObj3LongtRltvSpd "IACCDetObj3LongtRltvSpd";
BA_ "LongName" SG_ 958 ACCDetObj3LongtRltvSpd "Adaptive_Cruise_Control_Detected_Object_3_Longitudinal_Relative_Speed";
BA_ "SysSignalName" SG_ 958 ACCDetObj3LongtRltvSpd "ACCDetObj3LongtRltvSpd";
BA_ "CompuMethodName" SG_ 958 ACCConfmSw "ACCConfmSw";
BA_ "ISignalName" SG_ 958 ACCConfmSw "IACCConfmSw";
BA_ "LongName" SG_ 958 ACCConfmSw "ACC confirm  switch";
BA_ "SysSignalName" SG_ 958 ACCConfmSw "ACCConfmSw";
BA_ "CompuMethodName" SG_ 958 ACCDetObj1ExistPrblty "ACCDetObj1ExistPrblty";
BA_ "ISignalName" SG_ 958 ACCDetObj1ExistPrblty "IACCDetObj1ExistPrblty";
BA_ "LongName" SG_ 958 ACCDetObj1ExistPrblty "Adaptive_Cruise_Control_Detected_Object_1_Exist_Probability";
BA_ "SysSignalName" SG_ 958 ACCDetObj1ExistPrblty "ACCDetObj1ExistPrblty";
BA_ "CompuMethodName" SG_ 958 ACCCurveSpdSw "ACCCurveSpdSw";
BA_ "ISignalName" SG_ 958 ACCCurveSpdSw "IACCCurveSpdSw";
BA_ "LongName" SG_ 958 ACCCurveSpdSw "ACC curve speed switch";
BA_ "SysSignalName" SG_ 958 ACCCurveSpdSw "ACCCurveSpdSw";
BA_ "CompuMethodName" SG_ 958 ACCDetObj1Id "ACCDetObj1Id";
BA_ "ISignalName" SG_ 958 ACCDetObj1Id "IACCDetObj1Id";
BA_ "LongName" SG_ 958 ACCDetObj1Id "Adaptive_Cruise_Control_Detected_Object_1_Identifier";
BA_ "SysSignalName" SG_ 958 ACCDetObj1Id "ACCDetObj1Id";
BA_ "CompuMethodName" SG_ 958 ACCDetObj2Id "ACCDetObj2Id";
BA_ "ISignalName" SG_ 958 ACCDetObj2Id "IACCDetObj2Id";
BA_ "LongName" SG_ 958 ACCDetObj2Id "Adaptive_Cruise_Control_Detected_Object_2_Identifier";
BA_ "SysSignalName" SG_ 958 ACCDetObj2Id "ACCDetObj2Id";
BA_ "CompuMethodName" SG_ 958 ACCDetObj2ExistPrblty "ACCDetObj2ExistPrblty";
BA_ "ISignalName" SG_ 958 ACCDetObj2ExistPrblty "IACCDetObj2ExistPrblty";
BA_ "LongName" SG_ 958 ACCDetObj2ExistPrblty "Adaptive_Cruise_Control_Detected_Object_2_Exist_Probability";
BA_ "SysSignalName" SG_ 958 ACCDetObj2ExistPrblty "ACCDetObj2ExistPrblty";
BA_ "CompuMethodName" SG_ 958 ACCDetObj3ExistPrblty "ACCDetObj3ExistPrblty";
BA_ "ISignalName" SG_ 958 ACCDetObj3ExistPrblty "IACCDetObj3ExistPrblty";
BA_ "LongName" SG_ 958 ACCDetObj3ExistPrblty "Adaptive_Cruise_Control_Detected_Object_3_Exist_Probability";
BA_ "SysSignalName" SG_ 958 ACCDetObj3ExistPrblty "ACCDetObj3ExistPrblty";
BA_ "CompuMethodName" SG_ 958 ACCDetObj3Id "ACCDetObj3Id";
BA_ "ISignalName" SG_ 958 ACCDetObj3Id "IACCDetObj3Id";
BA_ "LongName" SG_ 958 ACCDetObj3Id "Adaptive_Cruise_Control_Detected_Object_3_Identifier";
BA_ "SysSignalName" SG_ 958 ACCDetObj3Id "ACCDetObj3Id";
BA_ "CompuMethodName" SG_ 958 ELKWarning "ELKWarning";
BA_ "GenSigStartValue" SG_ 958 ELKWarning 6;
BA_ "ISignalName" SG_ 958 ELKWarning "IELKWarning";
BA_ "LongName" SG_ 958 ELKWarning "ELK Warning";
BA_ "SysSignalName" SG_ 958 ELKWarning "ELKWarning";
BA_ "CompuMethodName" SG_ 958 ACCDetObj2SyncCtr "ACCDetObj2SyncCtr";
BA_ "ISignalName" SG_ 958 ACCDetObj2SyncCtr "IACCDetObj2SyncCtr";
BA_ "LongName" SG_ 958 ACCDetObj2SyncCtr "Adaptive_Cruise_Control_Detected_Object_2_Synchronize_Counter";
BA_ "SysSignalName" SG_ 958 ACCDetObj2SyncCtr "ACCDetObj2SyncCtr";
BA_ "CompuMethodName" SG_ 958 ACCDetObj1SyncCtr "ACCDetObj1SyncCtr";
BA_ "ISignalName" SG_ 958 ACCDetObj1SyncCtr "IACCDetObj1SyncCtr";
BA_ "LongName" SG_ 958 ACCDetObj1SyncCtr "Adaptive_Cruise_Control_Detected_Object_1_Synchronize_Counter";
BA_ "SysSignalName" SG_ 958 ACCDetObj1SyncCtr "ACCDetObj1SyncCtr";
BA_ "CompuMethodName" SG_ 958 ACCDetObj3SyncCtr "ACCDetObj3SyncCtr";
BA_ "ISignalName" SG_ 958 ACCDetObj3SyncCtr "IACCDetObj3SyncCtr";
BA_ "LongName" SG_ 958 ACCDetObj3SyncCtr "Adaptive_Cruise_Control_Detected_Object_3_Synchronize_Counter";
BA_ "SysSignalName" SG_ 958 ACCDetObj3SyncCtr "ACCDetObj3SyncCtr";
BA_ "CompuMethodName" SG_ 958 ACCDetObj2Typ "ACCDetObj2Typ";
BA_ "ISignalName" SG_ 958 ACCDetObj2Typ "IACCDetObj2Typ";
BA_ "LongName" SG_ 958 ACCDetObj2Typ "Adaptive_Cruise_Control_Detected_Object_2_Type";
BA_ "SysSignalName" SG_ 958 ACCDetObj2Typ "ACCDetObj2Typ";
BA_ "CompuMethodName" SG_ 958 ACCDetObj1Typ "ACCDetObj1Typ";
BA_ "ISignalName" SG_ 958 ACCDetObj1Typ "IACCDetObj1Typ";
BA_ "LongName" SG_ 958 ACCDetObj1Typ "Adaptive_Cruise_Control_Detected_Object_1_Type";
BA_ "SysSignalName" SG_ 958 ACCDetObj1Typ "ACCDetObj1Typ";
BA_ "CompuMethodName" SG_ 958 ACCDrvrTkovReq "ACCDrvrTkovReq";
BA_ "ISignalName" SG_ 958 ACCDrvrTkovReq "IACCDrvrTkovReq";
BA_ "LongName" SG_ 958 ACCDrvrTkovReq "Adaptive_Cruise_Control_Driver_Takeover_Request";
BA_ "SysSignalName" SG_ 958 ACCDrvrTkovReq "ACCDrvrTkovReq";
BA_ "CompuMethodName" SG_ 958 ACCDetObj3Typ "ACCDetObj3Typ";
BA_ "ISignalName" SG_ 958 ACCDetObj3Typ "IACCDetObj3Typ";
BA_ "LongName" SG_ 958 ACCDetObj3Typ "Adaptive_Cruise_Control_Detected_Object_3_Type";
BA_ "SysSignalName" SG_ 958 ACCDetObj3Typ "ACCDetObj3Typ";
BA_ "CompuMethodName" SG_ 956 PilotSysMsg "PilotSysMsg";
BA_ "ISignalName" SG_ 956 PilotSysMsg "IPilotSysMsg";
BA_ "LongName" SG_ 956 PilotSysMsg "Pilot System Message";
BA_ "SysSignalName" SG_ 956 PilotSysMsg "PilotSysMsg";
BA_ "CompuMethodName" SG_ 956 Lane0_C0 "Lane0_C0";
BA_ "ISignalName" SG_ 956 Lane0_C0 "ILane0_C0";
BA_ "LongName" SG_ 956 Lane0_C0 "Lane_0_Curve_Parameter_C0";
BA_ "SysSignalName" SG_ 956 Lane0_C0 "Lane0_C0";
BA_ "CompuMethodName" SG_ 956 Lane0_C1 "Lane0_C1";
BA_ "ISignalName" SG_ 956 Lane0_C1 "ILane0_C1";
BA_ "LongName" SG_ 956 Lane0_C1 "Lane_0_Curve_Parameter_C1";
BA_ "SysSignalName" SG_ 956 Lane0_C1 "Lane0_C1";
BA_ "CompuMethodName" SG_ 956 Lane0_C2 "Lane0_C2";
BA_ "ISignalName" SG_ 956 Lane0_C2 "ILane0_C2";
BA_ "LongName" SG_ 956 Lane0_C2 "Lane_0_Curve_Parameter_C2";
BA_ "SysSignalName" SG_ 956 Lane0_C2 "Lane0_C2";
BA_ "CompuMethodName" SG_ 956 Lane0_C3 "Lane0_C3";
BA_ "ISignalName" SG_ 956 Lane0_C3 "ILane0_C3";
BA_ "LongName" SG_ 956 Lane0_C3 "Lane_0_Curve_Parameter_C3";
BA_ "SysSignalName" SG_ 956 Lane0_C3 "Lane0_C3";
BA_ "CompuMethodName" SG_ 956 Lane1_C0 "Lane1_C0";
BA_ "ISignalName" SG_ 956 Lane1_C0 "ILane1_C0";
BA_ "LongName" SG_ 956 Lane1_C0 "Lane_1_Curve_Parameter_C0";
BA_ "SysSignalName" SG_ 956 Lane1_C0 "Lane1_C0";
BA_ "CompuMethodName" SG_ 956 Lane1_C1 "Lane1_C1";
BA_ "ISignalName" SG_ 956 Lane1_C1 "ILane1_C1";
BA_ "LongName" SG_ 956 Lane1_C1 "Lane_1_Curve_Parameter_C1";
BA_ "SysSignalName" SG_ 956 Lane1_C1 "Lane1_C1";
BA_ "CompuMethodName" SG_ 956 Lane1_C2 "Lane1_C2";
BA_ "ISignalName" SG_ 956 Lane1_C2 "ILane1_C2";
BA_ "LongName" SG_ 956 Lane1_C2 "Lane_1_Curve_Parameter_C2";
BA_ "SysSignalName" SG_ 956 Lane1_C2 "Lane1_C2";
BA_ "CompuMethodName" SG_ 956 Lane1_C3 "Lane1_C3";
BA_ "ISignalName" SG_ 956 Lane1_C3 "ILane1_C3";
BA_ "LongName" SG_ 956 Lane1_C3 "Lane_1_Curve_Parameter_C3";
BA_ "SysSignalName" SG_ 956 Lane1_C3 "Lane1_C3";
BA_ "CompuMethodName" SG_ 956 Lane2_C0 "Lane2_C0";
BA_ "ISignalName" SG_ 956 Lane2_C0 "ILane2_C0";
BA_ "LongName" SG_ 956 Lane2_C0 "Lane_2_Curve_Parameter_C0";
BA_ "SysSignalName" SG_ 956 Lane2_C0 "Lane2_C0";
BA_ "CompuMethodName" SG_ 956 Lane2_C1 "Lane2_C1";
BA_ "ISignalName" SG_ 956 Lane2_C1 "ILane2_C1";
BA_ "LongName" SG_ 956 Lane2_C1 "Lane_2_Curve_Parameter_C1";
BA_ "SysSignalName" SG_ 956 Lane2_C1 "Lane2_C1";
BA_ "CompuMethodName" SG_ 956 Lane2_C2 "Lane2_C2";
BA_ "ISignalName" SG_ 956 Lane2_C2 "ILane2_C2";
BA_ "LongName" SG_ 956 Lane2_C2 "Lane_2_Curve_Parameter_C2";
BA_ "SysSignalName" SG_ 956 Lane2_C2 "Lane2_C2";
BA_ "CompuMethodName" SG_ 956 Lane2_C3 "Lane2_C3";
BA_ "ISignalName" SG_ 956 Lane2_C3 "ILane2_C3";
BA_ "LongName" SG_ 956 Lane2_C3 "Lane_2_Curve_Parameter_C3";
BA_ "SysSignalName" SG_ 956 Lane2_C3 "Lane2_C3";
BA_ "CompuMethodName" SG_ 956 Lane3_C0 "Lane3_C0";
BA_ "ISignalName" SG_ 956 Lane3_C0 "ILane3_C0";
BA_ "LongName" SG_ 956 Lane3_C0 "Lane_3_Curve_Parameter_C0";
BA_ "SysSignalName" SG_ 956 Lane3_C0 "Lane3_C0";
BA_ "CompuMethodName" SG_ 956 Lane3_C1 "Lane3_C1";
BA_ "ISignalName" SG_ 956 Lane3_C1 "ILane3_C1";
BA_ "LongName" SG_ 956 Lane3_C1 "Lane_3_Curve_Parameter_C1";
BA_ "SysSignalName" SG_ 956 Lane3_C1 "Lane3_C1";
BA_ "CompuMethodName" SG_ 956 Lane3_C2 "Lane3_C2";
BA_ "ISignalName" SG_ 956 Lane3_C2 "ILane3_C2";
BA_ "LongName" SG_ 956 Lane3_C2 "Lane_3_Curve_Parameter_C2";
BA_ "SysSignalName" SG_ 956 Lane3_C2 "Lane3_C2";
BA_ "CompuMethodName" SG_ 956 Lane3_C3 "Lane3_C3";
BA_ "ISignalName" SG_ 956 Lane3_C3 "ILane3_C3";
BA_ "LongName" SG_ 956 Lane3_C3 "Lane_3_Curve_Parameter_C3";
BA_ "SysSignalName" SG_ 956 Lane3_C3 "Lane3_C3";
BA_ "CompuMethodName" SG_ 956 Lane0_ViewRangeStart "Lane0_ViewRangeStart";
BA_ "ISignalName" SG_ 956 Lane0_ViewRangeStart "ILane0_ViewRangeStart";
BA_ "LongName" SG_ 956 Lane0_ViewRangeStart "Lane_0_Curve_Longitudinal_Distance_Start";
BA_ "SysSignalName" SG_ 956 Lane0_ViewRangeStart "Lane0_ViewRangeStart";
BA_ "CompuMethodName" SG_ 956 Lane1_ViewRangeStart "Lane1_ViewRangeStart";
BA_ "ISignalName" SG_ 956 Lane1_ViewRangeStart "ILane1_ViewRangeStart";
BA_ "LongName" SG_ 956 Lane1_ViewRangeStart "Lane_1_Curve_Longitudinal_Distance_Start";
BA_ "SysSignalName" SG_ 956 Lane1_ViewRangeStart "Lane1_ViewRangeStart";
BA_ "CompuMethodName" SG_ 956 Lane2_ViewRangeStart "Lane2_ViewRangeStart";
BA_ "ISignalName" SG_ 956 Lane2_ViewRangeStart "ILane2_ViewRangeStart";
BA_ "LongName" SG_ 956 Lane2_ViewRangeStart "Lane_2_Curve_Longitudinal_Distance_Start";
BA_ "SysSignalName" SG_ 956 Lane2_ViewRangeStart "Lane2_ViewRangeStart";
BA_ "CompuMethodName" SG_ 956 Lane3_ViewRangeStart "Lane3_ViewRangeStart";
BA_ "ISignalName" SG_ 956 Lane3_ViewRangeStart "ILane3_ViewRangeStart";
BA_ "LongName" SG_ 956 Lane3_ViewRangeStart "Lane_3_Curve_Longitudinal_Distance_Start";
BA_ "SysSignalName" SG_ 956 Lane3_ViewRangeStart "Lane3_ViewRangeStart";
BA_ "CompuMethodName" SG_ 956 Lane0_ViewRangeEnd "Lane0_ViewRangeEnd";
BA_ "ISignalName" SG_ 956 Lane0_ViewRangeEnd "ILane0_ViewRangeEnd";
BA_ "LongName" SG_ 956 Lane0_ViewRangeEnd "Lane_0_Curve_Longitudinal_Distance_Stop";
BA_ "SysSignalName" SG_ 956 Lane0_ViewRangeEnd "Lane0_ViewRangeEnd";
BA_ "CompuMethodName" SG_ 956 Lane1_ViewRangeEnd "Lane1_ViewRangeEnd";
BA_ "ISignalName" SG_ 956 Lane1_ViewRangeEnd "ILane1_ViewRangeEnd";
BA_ "LongName" SG_ 956 Lane1_ViewRangeEnd "Lane_1_Curve_Longitudinal_Distance_Stop";
BA_ "SysSignalName" SG_ 956 Lane1_ViewRangeEnd "Lane1_ViewRangeEnd";
BA_ "CompuMethodName" SG_ 956 Lane0_ExistPrblty "Lane0_ExistPrblty";
BA_ "ISignalName" SG_ 956 Lane0_ExistPrblty "ILane0_ExistPrblty";
BA_ "LongName" SG_ 956 Lane0_ExistPrblty "Lane_0_Exist_Probability";
BA_ "SysSignalName" SG_ 956 Lane0_ExistPrblty "Lane0_ExistPrblty";
BA_ "CompuMethodName" SG_ 956 Lane2_ViewRangeEnd "Lane2_ViewRangeEnd";
BA_ "ISignalName" SG_ 956 Lane2_ViewRangeEnd "ILane2_ViewRangeEnd";
BA_ "LongName" SG_ 956 Lane2_ViewRangeEnd "Lane_2_Curve_Longitudinal_Distance_Stop";
BA_ "SysSignalName" SG_ 956 Lane2_ViewRangeEnd "Lane2_ViewRangeEnd";
BA_ "CompuMethodName" SG_ 956 Lane3_ViewRangeEnd "Lane3_ViewRangeEnd";
BA_ "ISignalName" SG_ 956 Lane3_ViewRangeEnd "ILane3_ViewRangeEnd";
BA_ "LongName" SG_ 956 Lane3_ViewRangeEnd "Lane_3_Curve_Longitudinal_Distance_Stop";
BA_ "SysSignalName" SG_ 956 Lane3_ViewRangeEnd "Lane3_ViewRangeEnd";
BA_ "CompuMethodName" SG_ 956 Lane1_ExistPrblty "Lane1_ExistPrblty";
BA_ "ISignalName" SG_ 956 Lane1_ExistPrblty "ILane1_ExistPrblty";
BA_ "LongName" SG_ 956 Lane1_ExistPrblty "Lane_1_Exist_Probability";
BA_ "SysSignalName" SG_ 956 Lane1_ExistPrblty "Lane1_ExistPrblty";
BA_ "CompuMethodName" SG_ 956 Lane0_Part0_SyncFrameIndex "Lane0_Part0_SyncFrameIndex";
BA_ "ISignalName" SG_ 956 Lane0_Part0_SyncFrameIndex "ILane0_Part0_SyncFrameIndex";
BA_ "LongName" SG_ 956 Lane0_Part0_SyncFrameIndex "Lane_0_Synchronize_Counter";
BA_ "SysSignalName" SG_ 956 Lane0_Part0_SyncFrameIndex "Lane0_Part0_SyncFrameIndex";
BA_ "CompuMethodName" SG_ 956 Lane0_ID "Lane0_ID";
BA_ "ISignalName" SG_ 956 Lane0_ID "ILane0_ID";
BA_ "LongName" SG_ 956 Lane0_ID "Lane_0_Identifier";
BA_ "SysSignalName" SG_ 956 Lane0_ID "Lane0_ID";
BA_ "CompuMethodName" SG_ 956 Lane1_Part0_SyncFrameIndex "Lane1_Part0_SyncFrameIndex";
BA_ "ISignalName" SG_ 956 Lane1_Part0_SyncFrameIndex "ILane1_Part0_SyncFrameIndex";
BA_ "LongName" SG_ 956 Lane1_Part0_SyncFrameIndex "Lane_1_Synchronize_Counter";
BA_ "SysSignalName" SG_ 956 Lane1_Part0_SyncFrameIndex "Lane1_Part0_SyncFrameIndex";
BA_ "CompuMethodName" SG_ 956 Lane1_ID "Lane1_ID";
BA_ "ISignalName" SG_ 956 Lane1_ID "ILane1_ID";
BA_ "LongName" SG_ 956 Lane1_ID "Lane_1_Identifier";
BA_ "SysSignalName" SG_ 956 Lane1_ID "Lane1_ID";
BA_ "CompuMethodName" SG_ 956 Lane2_Part0_SyncFrameIndex "Lane2_Part0_SyncFrameIndex";
BA_ "ISignalName" SG_ 956 Lane2_Part0_SyncFrameIndex "ILane2_Part0_SyncFrameIndex";
BA_ "LongName" SG_ 956 Lane2_Part0_SyncFrameIndex "Lane_2_Synchronize_Counter";
BA_ "SysSignalName" SG_ 956 Lane2_Part0_SyncFrameIndex "Lane2_Part0_SyncFrameIndex";
BA_ "CompuMethodName" SG_ 956 Lane2_ID "Lane2_ID";
BA_ "ISignalName" SG_ 956 Lane2_ID "ILane2_ID";
BA_ "LongName" SG_ 956 Lane2_ID "Lane_2_Identifier";
BA_ "SysSignalName" SG_ 956 Lane2_ID "Lane2_ID";
BA_ "CompuMethodName" SG_ 956 Lane3_Part0_SyncFrameIndex "Lane3_Part0_SyncFrameIndex";
BA_ "ISignalName" SG_ 956 Lane3_Part0_SyncFrameIndex "ILane3_Part0_SyncFrameIndex";
BA_ "LongName" SG_ 956 Lane3_Part0_SyncFrameIndex "Lane_3_Synchronize_Counter";
BA_ "SysSignalName" SG_ 956 Lane3_Part0_SyncFrameIndex "Lane3_Part0_SyncFrameIndex";
BA_ "CompuMethodName" SG_ 956 Lane3_ID "Lane3_ID";
BA_ "ISignalName" SG_ 956 Lane3_ID "ILane3_ID";
BA_ "LongName" SG_ 956 Lane3_ID "Lane_3_Identifier";
BA_ "SysSignalName" SG_ 956 Lane3_ID "Lane3_ID";
BA_ "CompuMethodName" SG_ 956 TLRMsgReq "TLRMsgReq";
BA_ "ISignalName" SG_ 956 TLRMsgReq "ITLRMsgReq";
BA_ "LongName" SG_ 956 TLRMsgReq "Traffic_lights_recognition_Message_Request";
BA_ "SysSignalName" SG_ 956 TLRMsgReq "TLRMsgReq";
BA_ "CompuMethodName" SG_ 956 Lane0_MarkerColor "Lane0_MarkerColor";
BA_ "ISignalName" SG_ 956 Lane0_MarkerColor "ILane0_MarkerColor";
BA_ "LongName" SG_ 956 Lane0_MarkerColor "Lane_0_Line_Color";
BA_ "SysSignalName" SG_ 956 Lane0_MarkerColor "Lane0_MarkerColor";
BA_ "CompuMethodName" SG_ 956 Lane0_location "Lane0_location";
BA_ "ISignalName" SG_ 956 Lane0_location "ILane0_location";
BA_ "LongName" SG_ 956 Lane0_location "Lane_0_Position";
BA_ "SysSignalName" SG_ 956 Lane0_location "Lane0_location";
BA_ "CompuMethodName" SG_ 956 TLRSysSts "TLRSysSts";
BA_ "ISignalName" SG_ 956 TLRSysSts "ITLRSysSts";
BA_ "LongName" SG_ 956 TLRSysSts "Traffic_lights_recognition_System_Status";
BA_ "SysSignalName" SG_ 956 TLRSysSts "TLRSysSts";
BA_ "CompuMethodName" SG_ 956 Lane1_location "Lane1_location";
BA_ "ISignalName" SG_ 956 Lane1_location "ILane1_location";
BA_ "LongName" SG_ 956 Lane1_location "Lane_1_Position";
BA_ "SysSignalName" SG_ 956 Lane1_location "Lane1_location";
BA_ "CompuMethodName" SG_ 956 Lane0_MarkerType "Lane0_MarkerType";
BA_ "ISignalName" SG_ 956 Lane0_MarkerType "ILane0_MarkerType";
BA_ "LongName" SG_ 956 Lane0_MarkerType "Lane_0_Marker_Type";
BA_ "SysSignalName" SG_ 956 Lane0_MarkerType "Lane0_MarkerType";
BA_ "CompuMethodName" SG_ 956 Lane1_MarkerType "Lane1_MarkerType";
BA_ "ISignalName" SG_ 956 Lane1_MarkerType "ILane1_MarkerType";
BA_ "LongName" SG_ 956 Lane1_MarkerType "Lane_1_Marker_Type";
BA_ "SysSignalName" SG_ 956 Lane1_MarkerType "Lane1_MarkerType";
BA_ "CompuMethodName" SG_ 956 Lane1_MarkerColor "Lane1_MarkerColor";
BA_ "ISignalName" SG_ 956 Lane1_MarkerColor "ILane1_MarkerColor";
BA_ "LongName" SG_ 956 Lane1_MarkerColor "Lane_1_Line_Color";
BA_ "SysSignalName" SG_ 956 Lane1_MarkerColor "Lane1_MarkerColor";
BA_ "CompuMethodName" SG_ 956 Lane2_ExistPrblty "Lane2_ExistPrblty";
BA_ "ISignalName" SG_ 956 Lane2_ExistPrblty "ILane2_ExistPrblty";
BA_ "LongName" SG_ 956 Lane2_ExistPrblty "Lane_2_Exist_Probability";
BA_ "SysSignalName" SG_ 956 Lane2_ExistPrblty "Lane2_ExistPrblty";
BA_ "CompuMethodName" SG_ 956 Lane2_MarkerColor "Lane2_MarkerColor";
BA_ "ISignalName" SG_ 956 Lane2_MarkerColor "ILane2_MarkerColor";
BA_ "LongName" SG_ 956 Lane2_MarkerColor "Lane_2_Line_Color";
BA_ "SysSignalName" SG_ 956 Lane2_MarkerColor "Lane2_MarkerColor";
BA_ "CompuMethodName" SG_ 956 Lane2_location "Lane2_location";
BA_ "ISignalName" SG_ 956 Lane2_location "ILane2_location";
BA_ "LongName" SG_ 956 Lane2_location "Lane_2_Position";
BA_ "SysSignalName" SG_ 956 Lane2_location "Lane2_location";
BA_ "CompuMethodName" SG_ 956 Lane3_location "Lane3_location";
BA_ "ISignalName" SG_ 956 Lane3_location "ILane3_location";
BA_ "LongName" SG_ 956 Lane3_location "Lane_3_Position";
BA_ "SysSignalName" SG_ 956 Lane3_location "Lane3_location";
BA_ "CompuMethodName" SG_ 956 Lane2_MarkerType "Lane2_MarkerType";
BA_ "ISignalName" SG_ 956 Lane2_MarkerType "ILane2_MarkerType";
BA_ "LongName" SG_ 956 Lane2_MarkerType "Lane_2_Marker_Type";
BA_ "SysSignalName" SG_ 956 Lane2_MarkerType "Lane2_MarkerType";
BA_ "CompuMethodName" SG_ 956 Lane3_ExistPrblty "Lane3_ExistPrblty";
BA_ "ISignalName" SG_ 956 Lane3_ExistPrblty "ILane3_ExistPrblty";
BA_ "LongName" SG_ 956 Lane3_ExistPrblty "Lane_3_Exist_Probability";
BA_ "SysSignalName" SG_ 956 Lane3_ExistPrblty "Lane3_ExistPrblty";
BA_ "CompuMethodName" SG_ 956 Lane3_MarkerType "Lane3_MarkerType";
BA_ "ISignalName" SG_ 956 Lane3_MarkerType "ILane3_MarkerType";
BA_ "LongName" SG_ 956 Lane3_MarkerType "Lane_3_Marker_Type";
BA_ "SysSignalName" SG_ 956 Lane3_MarkerType "Lane3_MarkerType";
BA_ "CompuMethodName" SG_ 956 Lane3_MarkerColor "Lane3_MarkerColor";
BA_ "ISignalName" SG_ 956 Lane3_MarkerColor "ILane3_MarkerColor";
BA_ "LongName" SG_ 956 Lane3_MarkerColor "Lane_3_Line_Color";
BA_ "SysSignalName" SG_ 956 Lane3_MarkerColor "Lane3_MarkerColor";
BA_ "CompuMethodName" SG_ 956 TLRWarning "TLRWarning";
BA_ "ISignalName" SG_ 956 TLRWarning "ITLRWarning";
BA_ "LongName" SG_ 956 TLRWarning "Traffic_lights_recognition_Warning";
BA_ "SysSignalName" SG_ 956 TLRWarning "TLRWarning";
BA_ "CompuMethodName" SG_ 956 TLRMdSwDspCmd "TLRMdSwDspCmd";
BA_ "ISignalName" SG_ 956 TLRMdSwDspCmd "ITLRMdSwDspCmd";
BA_ "LongName" SG_ 956 TLRMdSwDspCmd "Traffic_lights_recognition_Mode_Switch_Display_Command";
BA_ "SysSignalName" SG_ 956 TLRMdSwDspCmd "TLRMdSwDspCmd";
BA_ "CompuMethodName" SG_ 956 SpdLmtOfstSetResp "SpdLmtOfstSetResp";
BA_ "GenSigStartValue" SG_ 956 SpdLmtOfstSetResp 20;
BA_ "ISignalName" SG_ 956 SpdLmtOfstSetResp "ISpdLmtOfstSetResp";
BA_ "LongName" SG_ 956 SpdLmtOfstSetResp "Speed Limit Offset Set Response";
BA_ "SysSignalName" SG_ 956 SpdLmtOfstSetResp "SpdLmtOfstSetResp";
BA_ "CompuMethodName" SG_ 956 ACCDetObjHdngAng "ACCDetObjHdngAng";
BA_ "ISignalName" SG_ 956 ACCDetObjHdngAng "IACCDetObjHdngAng";
BA_ "LongName" SG_ 956 ACCDetObjHdngAng "Adaptive Cruise Control Detected Object Heading Angle";
BA_ "SysSignalName" SG_ 956 ACCDetObjHdngAng "ACCDetObjHdngAng";
BA_ "CompuMethodName" SG_ 956 CCSpdVcCmdCnfm "CCSpdVcCmdCnfm";
BA_ "ISignalName" SG_ 956 CCSpdVcCmdCnfm "ICCSpdVcCmdCnfm";
BA_ "LongName" SG_ 956 CCSpdVcCmdCnfm "Cruise_Control_Speed_Voice_Command_Confirm";
BA_ "SysSignalName" SG_ 956 CCSpdVcCmdCnfm "CCSpdVcCmdCnfm";
BA_ "CompuMethodName" SG_ 307 FVCM_20ms_Group02_CRC "FVCM_20ms_Group02_CRC";
BA_ "ISignalName" SG_ 307 FVCM_20ms_Group02_CRC "IFVCM_20ms_Group02_CRC";
BA_ "SysSignalName" SG_ 307 FVCM_20ms_Group02_CRC "FVCM_20ms_Group02_CRC";
BA_ "CompuMethodName" SG_ 307 FVCM_20ms_Group02_RC "FVCM_20ms_Group02_RC";
BA_ "ISignalName" SG_ 307 FVCM_20ms_Group02_RC "IFVCM_20ms_Group02_RC";
BA_ "SysSignalName" SG_ 307 FVCM_20ms_Group02_RC "FVCM_20ms_Group02_RC";
BA_ "CompuMethodName" SG_ 307 FVCM_20ms_Group02_Reserved1 "FVCM_20ms_Group02_Reserved1";
BA_ "GenSigStartValue" SG_ 307 FVCM_20ms_Group02_Reserved1 15;
BA_ "ISignalName" SG_ 307 FVCM_20ms_Group02_Reserved1 "IFVCM_20ms_Group02_Reserved1";
BA_ "SysSignalName" SG_ 307 FVCM_20ms_Group02_Reserved1 "FVCM_20ms_Group02_Reserved1";
BA_ "CompuMethodName" SG_ 307 ACCTotWhlToqReqVal "ACCTotWhlToqReqVal";
BA_ "GenSigStartValue" SG_ 307 ACCTotWhlToqReqVal 30000;
BA_ "ISignalName" SG_ 307 ACCTotWhlToqReqVal "IACCTotWhlToqReqVal";
BA_ "LongName" SG_ 307 ACCTotWhlToqReqVal "Adaptive Cruise Control Total Wheel Torque Request Value";
BA_ "SysSignalName" SG_ 307 ACCTotWhlToqReqVal "ACCTotWhlToqReqVal";
BA_ "CompuMethodName" SG_ 307 ACCDrvrSelTrgtSpd "ACCDrvrSelTrgtSpd";
BA_ "ISignalName" SG_ 307 ACCDrvrSelTrgtSpd "IACCDrvrSelTrgtSpd";
BA_ "LongName" SG_ 307 ACCDrvrSelTrgtSpd "Adaptive_Cruise_Control_Driver_Select_Target_Speed";
BA_ "SysSignalName" SG_ 307 ACCDrvrSelTrgtSpd "ACCDrvrSelTrgtSpd";
BA_ "CompuMethodName" SG_ 307 ACCGoNotfr "ACCGoNotfr";
BA_ "ISignalName" SG_ 307 ACCGoNotfr "IACCGoNotfr";
BA_ "LongName" SG_ 307 ACCGoNotfr "Adaptive_Cruise_Control_Go_Notifier";
BA_ "SysSignalName" SG_ 307 ACCGoNotfr "ACCGoNotfr";
BA_ "CompuMethodName" SG_ 307 FVCM_20ms_Group02_Reserved2 "FVCM_20ms_Group02_Reserved2";
BA_ "GenSigStartValue" SG_ 307 FVCM_20ms_Group02_Reserved2 1;
BA_ "ISignalName" SG_ 307 FVCM_20ms_Group02_Reserved2 "IFVCM_20ms_Group02_Reserved2";
BA_ "SysSignalName" SG_ 307 FVCM_20ms_Group02_Reserved2 "FVCM_20ms_Group02_Reserved2";
BA_ "CompuMethodName" SG_ 307 ACCDetObjDistLvl "ACCDetObjDistLvl";
BA_ "ISignalName" SG_ 307 ACCDetObjDistLvl "IACCDetObjDistLvl";
BA_ "LongName" SG_ 307 ACCDetObjDistLvl "Adaptive Cruise Control Detected Object Distance Level";
BA_ "SysSignalName" SG_ 307 ACCDetObjDistLvl "ACCDetObjDistLvl";
BA_ "CompuMethodName" SG_ 307 ELKSysSts_IPD "ELKSysSts_IPD";
BA_ "ISignalName" SG_ 307 ELKSysSts_IPD "IELKSysSts_IPD";
BA_ "LongName" SG_ 307 ELKSysSts_IPD "ELK System status";
BA_ "SysSignalName" SG_ 307 ELKSysSts_IPD "ELKSysSts_IPD";
BA_ "CompuMethodName" SG_ 307 ACCTotWhlToqReqSts "ACCTotWhlToqReqSts";
BA_ "ISignalName" SG_ 307 ACCTotWhlToqReqSts "IACCTotWhlToqReqSts";
BA_ "LongName" SG_ 307 ACCTotWhlToqReqSts "Adaptive Cruise Control Total Wheel Torque Request Status";
BA_ "SysSignalName" SG_ 307 ACCTotWhlToqReqSts "ACCTotWhlToqReqSts";
BA_ "CompuMethodName" SG_ 307 ACCTJAMdSwDspCmd "ACCTJAMdSwDspCmd";
BA_ "ISignalName" SG_ 307 ACCTJAMdSwDspCmd "IACCTJAMdSwDspCmd";
BA_ "LongName" SG_ 307 ACCTJAMdSwDspCmd "Adaptive_Cruise_Control_Traffic_Jam_Assist_Mode_Switch_Display_Command";
BA_ "SysSignalName" SG_ 307 ACCTJAMdSwDspCmd "ACCTJAMdSwDspCmd";
BA_ "CompuMethodName" SG_ 307 ACCSeldTrgtDistLvl "ACCSeldTrgtDistLvl";
BA_ "GenSigStartValue" SG_ 307 ACCSeldTrgtDistLvl 3;
BA_ "ISignalName" SG_ 307 ACCSeldTrgtDistLvl "IACCSeldTrgtDistLvl";
BA_ "LongName" SG_ 307 ACCSeldTrgtDistLvl "Adaptive_Cruise_Control_Selected_Target_Distance_Level";
BA_ "SysSignalName" SG_ 307 ACCSeldTrgtDistLvl "ACCSeldTrgtDistLvl";
BA_ "CompuMethodName" SG_ 307 FVCM_20ms_Group02_Reserved3 "FVCM_20ms_Group02_Reserved3";
BA_ "GenSigStartValue" SG_ 307 FVCM_20ms_Group02_Reserved3 255;
BA_ "ISignalName" SG_ 307 FVCM_20ms_Group02_Reserved3 "IFVCM_20ms_Group02_Reserved3";
BA_ "SysSignalName" SG_ 307 FVCM_20ms_Group02_Reserved3 "FVCM_20ms_Group02_Reserved3";
BA_ "CompuMethodName" SG_ 307 HandOffStrgWhlDetnSta "HandOffStrgWhlDetnSta";
BA_ "ISignalName" SG_ 307 HandOffStrgWhlDetnSta "IHandOffStrgWhlDetnSta";
BA_ "LongName" SG_ 307 HandOffStrgWhlDetnSta "Hand_Off_Steering_Wheel_Detection_State";
BA_ "SysSignalName" SG_ 307 HandOffStrgWhlDetnSta "HandOffStrgWhlDetnSta";
BA_ "CompuMethodName" SG_ 307 ILCActvnDircnDspCmd "ILCActvnDircnDspCmd";
BA_ "ISignalName" SG_ 307 ILCActvnDircnDspCmd "IILCActvnDircnDspCmd";
BA_ "LongName" SG_ 307 ILCActvnDircnDspCmd "Intelligent_Lateral_Control_Activation_Direction_Display_Command";
BA_ "SysSignalName" SG_ 307 ILCActvnDircnDspCmd "ILCActvnDircnDspCmd";
BA_ "CompuMethodName" SG_ 307 FVCM_20ms_Group02_Reserved4 "FVCM_20ms_Group02_Reserved4";
BA_ "GenSigStartValue" SG_ 307 FVCM_20ms_Group02_Reserved4 7;
BA_ "ISignalName" SG_ 307 FVCM_20ms_Group02_Reserved4 "IFVCM_20ms_Group02_Reserved4";
BA_ "SysSignalName" SG_ 307 FVCM_20ms_Group02_Reserved4 "FVCM_20ms_Group02_Reserved4";
BA_ "CompuMethodName" SG_ 307 ILCSwDspCmd "ILCSwDspCmd";
BA_ "ISignalName" SG_ 307 ILCSwDspCmd "IILCSwDspCmd";
BA_ "LongName" SG_ 307 ILCSwDspCmd "Intelligent_Lateral_Control_Switch_Display_Command";
BA_ "SysSignalName" SG_ 307 ILCSwDspCmd "ILCSwDspCmd";
BA_ "CompuMethodName" SG_ 307 ILCSysSts "ILCSysSts";
BA_ "ISignalName" SG_ 307 ILCSysSts "IILCSysSts";
BA_ "LongName" SG_ 307 ILCSysSts "Intelligent_Lateral_Control_System_Status";
BA_ "SysSignalName" SG_ 307 ILCSysSts "ILCSysSts";
BA_ "CompuMethodName" SG_ 307 ILCActvnVelDspCmd "ILCActvnVelDspCmd";
BA_ "ISignalName" SG_ 307 ILCActvnVelDspCmd "IILCActvnVelDspCmd";
BA_ "LongName" SG_ 307 ILCActvnVelDspCmd "Intelligent_Longitudinal_Control_Activation_Velocity_Display_Command";
BA_ "SysSignalName" SG_ 307 ILCActvnVelDspCmd "ILCActvnVelDspCmd";
BA_ "CompuMethodName" SG_ 307 HandOffStrgWhlDetnStaV "HandOffStrgWhlDetnStaV";
BA_ "ISignalName" SG_ 307 HandOffStrgWhlDetnStaV "IHandOffStrgWhlDetnStaV";
BA_ "LongName" SG_ 307 HandOffStrgWhlDetnStaV "Hand Off Steering Wheel Detection State Validity";
BA_ "SysSignalName" SG_ 307 HandOffStrgWhlDetnStaV "HandOffStrgWhlDetnStaV";
BA_ "CompuMethodName" SG_ 307 LDWLKAAudReq "LDWLKAAudReq";
BA_ "ISignalName" SG_ 307 LDWLKAAudReq "ILDWLKAAudReq";
BA_ "LongName" SG_ 307 LDWLKAAudReq "Lane_Departure_Warning_Lane_Keeping_Assist_Audible_Request";
BA_ "SysSignalName" SG_ 307 LDWLKAAudReq "LDWLKAAudReq";
BA_ "CompuMethodName" SG_ 307 LDWAdoWrnngDspCmd "LDWAdoWrnngDspCmd";
BA_ "ISignalName" SG_ 307 LDWAdoWrnngDspCmd "ILDWAdoWrnngDspCmd";
BA_ "LongName" SG_ 307 LDWAdoWrnngDspCmd "Lane_Departure_Warning_Audio_Warning_Display_Command";
BA_ "SysSignalName" SG_ 307 LDWAdoWrnngDspCmd "LDWAdoWrnngDspCmd";
BA_ "CompuMethodName" SG_ 307 LDWLKADspCmd "LDWLKADspCmd";
BA_ "ISignalName" SG_ 307 LDWLKADspCmd "ILDWLKADspCmd";
BA_ "LongName" SG_ 307 LDWLKADspCmd "Lane_Departure_Warning_Lane_Keeping_Assist_Display_Command";
BA_ "SysSignalName" SG_ 307 LDWLKADspCmd "LDWLKADspCmd";
BA_ "CompuMethodName" SG_ 307 FVCM_20ms_Group02_Reserved5 "FVCM_20ms_Group02_Reserved5";
BA_ "GenSigStartValue" SG_ 307 FVCM_20ms_Group02_Reserved5 7;
BA_ "ISignalName" SG_ 307 FVCM_20ms_Group02_Reserved5 "IFVCM_20ms_Group02_Reserved5";
BA_ "SysSignalName" SG_ 307 FVCM_20ms_Group02_Reserved5 "FVCM_20ms_Group02_Reserved5";
BA_ "CompuMethodName" SG_ 307 LKADrvrTkovReq "LKADrvrTkovReq";
BA_ "ISignalName" SG_ 307 LKADrvrTkovReq "ILKADrvrTkovReq";
BA_ "LongName" SG_ 307 LKADrvrTkovReq "Lane_Keeping_Assist_Driver_Takeover_Request";
BA_ "SysSignalName" SG_ 307 LKADrvrTkovReq "LKADrvrTkovReq";
BA_ "CompuMethodName" SG_ 307 LDWSnstvtLvl "LDWSnstvtLvl";
BA_ "ISignalName" SG_ 307 LDWSnstvtLvl "ILDWSnstvtLvl";
BA_ "LongName" SG_ 307 LDWSnstvtLvl "Lane_Departure_Warning_Sensitivity_Level";
BA_ "SysSignalName" SG_ 307 LDWSnstvtLvl "LDWSnstvtLvl";
BA_ "CompuMethodName" SG_ 307 LDWLKAHptWrnngDspCmd "LDWLKAHptWrnngDspCmd";
BA_ "ISignalName" SG_ 307 LDWLKAHptWrnngDspCmd "ILDWLKAHptWrnngDspCmd";
BA_ "LongName" SG_ 307 LDWLKAHptWrnngDspCmd "Lane_Departure_Warning_Lane_Keeping_Assist_Haptic_Warning_Display_Command";
BA_ "SysSignalName" SG_ 307 LDWLKAHptWrnngDspCmd "LDWLKAHptWrnngDspCmd";
BA_ "CompuMethodName" SG_ 307 EyeOffRoadDetnSta "EyeOffRoadDetnSta";
BA_ "ISignalName" SG_ 307 EyeOffRoadDetnSta "IEyeOffRoadDetnSta";
BA_ "LongName" SG_ 307 EyeOffRoadDetnSta "Eye_Off_Road_Detection_State";
BA_ "SysSignalName" SG_ 307 EyeOffRoadDetnSta "EyeOffRoadDetnSta";
BA_ "CompuMethodName" SG_ 307 FVCM_20ms_Group02_Reserved6 "FVCM_20ms_Group02_Reserved6";
BA_ "GenSigStartValue" SG_ 307 FVCM_20ms_Group02_Reserved6 63;
BA_ "ISignalName" SG_ 307 FVCM_20ms_Group02_Reserved6 "IFVCM_20ms_Group02_Reserved6";
BA_ "SysSignalName" SG_ 307 FVCM_20ms_Group02_Reserved6 "FVCM_20ms_Group02_Reserved6";
BA_ "CompuMethodName" SG_ 307 FVCM_20ms_Group02_Reserved7 "FVCM_20ms_Group02_Reserved7";
BA_ "GenSigStartValue" SG_ 307 FVCM_20ms_Group02_Reserved7 3;
BA_ "ISignalName" SG_ 307 FVCM_20ms_Group02_Reserved7 "IFVCM_20ms_Group02_Reserved7";
BA_ "SysSignalName" SG_ 307 FVCM_20ms_Group02_Reserved7 "FVCM_20ms_Group02_Reserved7";
BA_ "CompuMethodName" SG_ 307 EyeOffRoadDetnStaV "EyeOffRoadDetnStaV";
BA_ "ISignalName" SG_ 307 EyeOffRoadDetnStaV "IEyeOffRoadDetnStaV";
BA_ "LongName" SG_ 307 EyeOffRoadDetnStaV "Eye_Off_Road_Detection_State_Validity";
BA_ "SysSignalName" SG_ 307 EyeOffRoadDetnStaV "EyeOffRoadDetnStaV";
BA_ "CompuMethodName" SG_ 307 ACCMsgReq "ACCMsgReq";
BA_ "ISignalName" SG_ 307 ACCMsgReq "IACCMsgReq";
BA_ "LongName" SG_ 307 ACCMsgReq "Adaptive_Cruise_Control_Message_Request";
BA_ "SysSignalName" SG_ 307 ACCMsgReq "ACCMsgReq";
BA_ "CompuMethodName" SG_ 307 FVCM_20ms_Group02_Reserved8 "FVCM_20ms_Group02_Reserved8";
BA_ "GenSigStartValue" SG_ 307 FVCM_20ms_Group02_Reserved8 255;
BA_ "ISignalName" SG_ 307 FVCM_20ms_Group02_Reserved8 "IFVCM_20ms_Group02_Reserved8";
BA_ "SysSignalName" SG_ 307 FVCM_20ms_Group02_Reserved8 "FVCM_20ms_Group02_Reserved8";
BA_ "CompuMethodName" SG_ 1381 SatAz5 "SatAz5";
BA_ "ISignalName" SG_ 1381 SatAz5 "ISatAz5";
BA_ "LongName" SG_ 1381 SatAz5 "Satellite5 Azimuth Angle";
BA_ "SysSignalName" SG_ 1381 SatAz5 "SatAz5";
BA_ "CompuMethodName" SG_ 1381 SatCNO5 "SatCNO5";
BA_ "ISignalName" SG_ 1381 SatCNO5 "ISatCNO5";
BA_ "LongName" SG_ 1381 SatCNO5 "Satellite5 Cno";
BA_ "SysSignalName" SG_ 1381 SatCNO5 "SatCNO5";
BA_ "CompuMethodName" SG_ 1381 SatElv5 "SatElv5";
BA_ "ISignalName" SG_ 1381 SatElv5 "ISatElv5";
BA_ "LongName" SG_ 1381 SatElv5 "Satellite5 Elevation Angle";
BA_ "SysSignalName" SG_ 1381 SatElv5 "SatElv5";
BA_ "CompuMethodName" SG_ 1381 SatAz6 "SatAz6";
BA_ "ISignalName" SG_ 1381 SatAz6 "ISatAz6";
BA_ "LongName" SG_ 1381 SatAz6 "Satellite6 Azimuth Angle";
BA_ "SysSignalName" SG_ 1381 SatAz6 "SatAz6";
BA_ "CompuMethodName" SG_ 1381 SatID5 "SatID5";
BA_ "ISignalName" SG_ 1381 SatID5 "ISatID5";
BA_ "LongName" SG_ 1381 SatID5 "Satellite5 Id";
BA_ "SysSignalName" SG_ 1381 SatID5 "SatID5";
BA_ "CompuMethodName" SG_ 1381 SatCNO6 "SatCNO6";
BA_ "ISignalName" SG_ 1381 SatCNO6 "ISatCNO6";
BA_ "LongName" SG_ 1381 SatCNO6 "Satellite6 Cno";
BA_ "SysSignalName" SG_ 1381 SatCNO6 "SatCNO6";
BA_ "CompuMethodName" SG_ 1381 SatElv6 "SatElv6";
BA_ "ISignalName" SG_ 1381 SatElv6 "ISatElv6";
BA_ "LongName" SG_ 1381 SatElv6 "Satellite6 Elevation Angle";
BA_ "SysSignalName" SG_ 1381 SatElv6 "SatElv6";
BA_ "CompuMethodName" SG_ 1381 SatID6 "SatID6";
BA_ "ISignalName" SG_ 1381 SatID6 "ISatID6";
BA_ "LongName" SG_ 1381 SatID6 "Satellite6 Id";
BA_ "SysSignalName" SG_ 1381 SatID6 "SatID6";
BA_ "CompuMethodName" SG_ 1374 SatAz1 "SatAz1";
BA_ "ISignalName" SG_ 1374 SatAz1 "ISatAz1";
BA_ "LongName" SG_ 1374 SatAz1 "Satellite1 Azimuth Angle";
BA_ "SysSignalName" SG_ 1374 SatAz1 "SatAz1";
BA_ "CompuMethodName" SG_ 1374 SatCNO1 "SatCNO1";
BA_ "ISignalName" SG_ 1374 SatCNO1 "ISatCNO1";
BA_ "LongName" SG_ 1374 SatCNO1 "Satellite1 Cno";
BA_ "SysSignalName" SG_ 1374 SatCNO1 "SatCNO1";
BA_ "CompuMethodName" SG_ 1374 SatElv1 "SatElv1";
BA_ "ISignalName" SG_ 1374 SatElv1 "ISatElv1";
BA_ "LongName" SG_ 1374 SatElv1 "Satellite1 Elevation Angle";
BA_ "SysSignalName" SG_ 1374 SatElv1 "SatElv1";
BA_ "CompuMethodName" SG_ 1374 SatAz2 "SatAz2";
BA_ "ISignalName" SG_ 1374 SatAz2 "ISatAz2";
BA_ "LongName" SG_ 1374 SatAz2 "Satellite2 Azimuth Angle";
BA_ "SysSignalName" SG_ 1374 SatAz2 "SatAz2";
BA_ "CompuMethodName" SG_ 1374 SatID1 "SatID1";
BA_ "ISignalName" SG_ 1374 SatID1 "ISatID1";
BA_ "LongName" SG_ 1374 SatID1 "Satellite1 Id";
BA_ "SysSignalName" SG_ 1374 SatID1 "SatID1";
BA_ "CompuMethodName" SG_ 1374 SatCNO2 "SatCNO2";
BA_ "ISignalName" SG_ 1374 SatCNO2 "ISatCNO2";
BA_ "LongName" SG_ 1374 SatCNO2 "Satellite2 Cno";
BA_ "SysSignalName" SG_ 1374 SatCNO2 "SatCNO2";
BA_ "CompuMethodName" SG_ 1374 SatElv2 "SatElv2";
BA_ "ISignalName" SG_ 1374 SatElv2 "ISatElv2";
BA_ "LongName" SG_ 1374 SatElv2 "Satellite2 Elevation Angle";
BA_ "SysSignalName" SG_ 1374 SatElv2 "SatElv2";
BA_ "CompuMethodName" SG_ 1374 SatID2 "SatID2";
BA_ "ISignalName" SG_ 1374 SatID2 "ISatID2";
BA_ "LongName" SG_ 1374 SatID2 "Satellite2 Id";
BA_ "SysSignalName" SG_ 1374 SatID2 "SatID2";
BA_ "CompuMethodName" SG_ 1375 SatAz17 "SatAz17";
BA_ "ISignalName" SG_ 1375 SatAz17 "ISatAz17";
BA_ "LongName" SG_ 1375 SatAz17 "Satellite17 Azimuth Angle";
BA_ "SysSignalName" SG_ 1375 SatAz17 "SatAz17";
BA_ "CompuMethodName" SG_ 1375 SatCNO17 "SatCNO17";
BA_ "ISignalName" SG_ 1375 SatCNO17 "ISatCNO17";
BA_ "LongName" SG_ 1375 SatCNO17 "Satellite17 Cno";
BA_ "SysSignalName" SG_ 1375 SatCNO17 "SatCNO17";
BA_ "CompuMethodName" SG_ 1375 SatElv17 "SatElv17";
BA_ "ISignalName" SG_ 1375 SatElv17 "ISatElv17";
BA_ "LongName" SG_ 1375 SatElv17 "Satellite17 Elevation Angle";
BA_ "SysSignalName" SG_ 1375 SatElv17 "SatElv17";
BA_ "CompuMethodName" SG_ 1375 SatAz18 "SatAz18";
BA_ "ISignalName" SG_ 1375 SatAz18 "ISatAz18";
BA_ "LongName" SG_ 1375 SatAz18 "Satellite18 Azimuth Angle";
BA_ "SysSignalName" SG_ 1375 SatAz18 "SatAz18";
BA_ "CompuMethodName" SG_ 1375 SatID17 "SatID17";
BA_ "ISignalName" SG_ 1375 SatID17 "ISatID17";
BA_ "LongName" SG_ 1375 SatID17 "Satellite17 Id";
BA_ "SysSignalName" SG_ 1375 SatID17 "SatID17";
BA_ "CompuMethodName" SG_ 1375 SatCNO18 "SatCNO18";
BA_ "ISignalName" SG_ 1375 SatCNO18 "ISatCNO18";
BA_ "LongName" SG_ 1375 SatCNO18 "Satellite18 Cno";
BA_ "SysSignalName" SG_ 1375 SatCNO18 "SatCNO18";
BA_ "CompuMethodName" SG_ 1375 SatElv18 "SatElv18";
BA_ "ISignalName" SG_ 1375 SatElv18 "ISatElv18";
BA_ "LongName" SG_ 1375 SatElv18 "Satellite18 Elevation Angle";
BA_ "SysSignalName" SG_ 1375 SatElv18 "SatElv18";
BA_ "CompuMethodName" SG_ 1375 SatID18 "SatID18";
BA_ "ISignalName" SG_ 1375 SatID18 "ISatID18";
BA_ "LongName" SG_ 1375 SatID18 "Satellite18 Id";
BA_ "SysSignalName" SG_ 1375 SatID18 "SatID18";
BA_ "CompuMethodName" SG_ 1382 SatAz7 "SatAz7";
BA_ "ISignalName" SG_ 1382 SatAz7 "ISatAz7";
BA_ "LongName" SG_ 1382 SatAz7 "Satellite7 Azimuth Angle";
BA_ "SysSignalName" SG_ 1382 SatAz7 "SatAz7";
BA_ "CompuMethodName" SG_ 1382 SatCNO7 "SatCNO7";
BA_ "ISignalName" SG_ 1382 SatCNO7 "ISatCNO7";
BA_ "LongName" SG_ 1382 SatCNO7 "Satellite7 Cno";
BA_ "SysSignalName" SG_ 1382 SatCNO7 "SatCNO7";
BA_ "CompuMethodName" SG_ 1382 SatElv7 "SatElv7";
BA_ "ISignalName" SG_ 1382 SatElv7 "ISatElv7";
BA_ "LongName" SG_ 1382 SatElv7 "Satellite7 Elevation Angle";
BA_ "SysSignalName" SG_ 1382 SatElv7 "SatElv7";
BA_ "CompuMethodName" SG_ 1382 SatAz8 "SatAz8";
BA_ "ISignalName" SG_ 1382 SatAz8 "ISatAz8";
BA_ "LongName" SG_ 1382 SatAz8 "Satellite8 Azimuth Angle";
BA_ "SysSignalName" SG_ 1382 SatAz8 "SatAz8";
BA_ "CompuMethodName" SG_ 1382 SatID7 "SatID7";
BA_ "ISignalName" SG_ 1382 SatID7 "ISatID7";
BA_ "LongName" SG_ 1382 SatID7 "Satellite7 Id";
BA_ "SysSignalName" SG_ 1382 SatID7 "SatID7";
BA_ "CompuMethodName" SG_ 1382 SatCNO8 "SatCNO8";
BA_ "ISignalName" SG_ 1382 SatCNO8 "ISatCNO8";
BA_ "LongName" SG_ 1382 SatCNO8 "Satellite8 Cno";
BA_ "SysSignalName" SG_ 1382 SatCNO8 "SatCNO8";
BA_ "CompuMethodName" SG_ 1382 SatElv8 "SatElv8";
BA_ "ISignalName" SG_ 1382 SatElv8 "ISatElv8";
BA_ "LongName" SG_ 1382 SatElv8 "Satellite8 Elevation Angle";
BA_ "SysSignalName" SG_ 1382 SatElv8 "SatElv8";
BA_ "CompuMethodName" SG_ 1382 SatID8 "SatID8";
BA_ "ISignalName" SG_ 1382 SatID8 "ISatID8";
BA_ "LongName" SG_ 1382 SatID8 "Satellite8 Id";
BA_ "SysSignalName" SG_ 1382 SatID8 "SatID8";
BA_ "CompuMethodName" SG_ 1383 SatAz9 "SatAz9";
BA_ "ISignalName" SG_ 1383 SatAz9 "ISatAz9";
BA_ "LongName" SG_ 1383 SatAz9 "Satellite9 Azimuth Angle";
BA_ "SysSignalName" SG_ 1383 SatAz9 "SatAz9";
BA_ "CompuMethodName" SG_ 1383 SatCNO9 "SatCNO9";
BA_ "ISignalName" SG_ 1383 SatCNO9 "ISatCNO9";
BA_ "LongName" SG_ 1383 SatCNO9 "Satellite9 Cno";
BA_ "SysSignalName" SG_ 1383 SatCNO9 "SatCNO9";
BA_ "CompuMethodName" SG_ 1383 SatElv9 "SatElv9";
BA_ "ISignalName" SG_ 1383 SatElv9 "ISatElv9";
BA_ "LongName" SG_ 1383 SatElv9 "Satellite9 Elevation Angle";
BA_ "SysSignalName" SG_ 1383 SatElv9 "SatElv9";
BA_ "CompuMethodName" SG_ 1383 SatAz10 "SatAz10";
BA_ "ISignalName" SG_ 1383 SatAz10 "ISatAz10";
BA_ "LongName" SG_ 1383 SatAz10 "Satellite10 Azimuth Angle";
BA_ "SysSignalName" SG_ 1383 SatAz10 "SatAz10";
BA_ "CompuMethodName" SG_ 1383 SatID9 "SatID9";
BA_ "ISignalName" SG_ 1383 SatID9 "ISatID9";
BA_ "LongName" SG_ 1383 SatID9 "Satellite9 Id";
BA_ "SysSignalName" SG_ 1383 SatID9 "SatID9";
BA_ "CompuMethodName" SG_ 1383 SatCNO10 "SatCNO10";
BA_ "ISignalName" SG_ 1383 SatCNO10 "ISatCNO10";
BA_ "LongName" SG_ 1383 SatCNO10 "Satellite10 Cno";
BA_ "SysSignalName" SG_ 1383 SatCNO10 "SatCNO10";
BA_ "CompuMethodName" SG_ 1383 SatElv10 "SatElv10";
BA_ "ISignalName" SG_ 1383 SatElv10 "ISatElv10";
BA_ "LongName" SG_ 1383 SatElv10 "Satellite10 Elevation Angle";
BA_ "SysSignalName" SG_ 1383 SatElv10 "SatElv10";
BA_ "CompuMethodName" SG_ 1383 SatID10 "SatID10";
BA_ "ISignalName" SG_ 1383 SatID10 "ISatID10";
BA_ "LongName" SG_ 1383 SatID10 "Satellite10 Id";
BA_ "SysSignalName" SG_ 1383 SatID10 "SatID10";
BA_ "CompuMethodName" SG_ 1384 SatAz11 "SatAz11";
BA_ "ISignalName" SG_ 1384 SatAz11 "ISatAz11";
BA_ "LongName" SG_ 1384 SatAz11 "Satellite11 Azimuth Angle";
BA_ "SysSignalName" SG_ 1384 SatAz11 "SatAz11";
BA_ "CompuMethodName" SG_ 1384 SatCNO11 "SatCNO11";
BA_ "ISignalName" SG_ 1384 SatCNO11 "ISatCNO11";
BA_ "LongName" SG_ 1384 SatCNO11 "Satellite11 Cno";
BA_ "SysSignalName" SG_ 1384 SatCNO11 "SatCNO11";
BA_ "CompuMethodName" SG_ 1384 SatElv11 "SatElv11";
BA_ "ISignalName" SG_ 1384 SatElv11 "ISatElv11";
BA_ "LongName" SG_ 1384 SatElv11 "Satellite11 Elevation Angle";
BA_ "SysSignalName" SG_ 1384 SatElv11 "SatElv11";
BA_ "CompuMethodName" SG_ 1384 SatAz12 "SatAz12";
BA_ "ISignalName" SG_ 1384 SatAz12 "ISatAz12";
BA_ "LongName" SG_ 1384 SatAz12 "Satellite12 Azimuth Angle";
BA_ "SysSignalName" SG_ 1384 SatAz12 "SatAz12";
BA_ "CompuMethodName" SG_ 1384 SatID11 "SatID11";
BA_ "ISignalName" SG_ 1384 SatID11 "ISatID11";
BA_ "LongName" SG_ 1384 SatID11 "Satellite11 Id";
BA_ "SysSignalName" SG_ 1384 SatID11 "SatID11";
BA_ "CompuMethodName" SG_ 1384 SatCNO12 "SatCNO12";
BA_ "ISignalName" SG_ 1384 SatCNO12 "ISatCNO12";
BA_ "LongName" SG_ 1384 SatCNO12 "Satellite12 Cno";
BA_ "SysSignalName" SG_ 1384 SatCNO12 "SatCNO12";
BA_ "CompuMethodName" SG_ 1384 SatElv12 "SatElv12";
BA_ "ISignalName" SG_ 1384 SatElv12 "ISatElv12";
BA_ "LongName" SG_ 1384 SatElv12 "Satellite12 Elevation Angle";
BA_ "SysSignalName" SG_ 1384 SatElv12 "SatElv12";
BA_ "CompuMethodName" SG_ 1384 SatID12 "SatID12";
BA_ "ISignalName" SG_ 1384 SatID12 "ISatID12";
BA_ "LongName" SG_ 1384 SatID12 "Satellite12 Id";
BA_ "SysSignalName" SG_ 1384 SatID12 "SatID12";
BA_ "CompuMethodName" SG_ 1385 SatAz13 "SatAz13";
BA_ "ISignalName" SG_ 1385 SatAz13 "ISatAz13";
BA_ "LongName" SG_ 1385 SatAz13 "Satellite13 Azimuth Angle";
BA_ "SysSignalName" SG_ 1385 SatAz13 "SatAz13";
BA_ "CompuMethodName" SG_ 1385 SatCNO13 "SatCNO13";
BA_ "ISignalName" SG_ 1385 SatCNO13 "ISatCNO13";
BA_ "LongName" SG_ 1385 SatCNO13 "Satellite13 Cno";
BA_ "SysSignalName" SG_ 1385 SatCNO13 "SatCNO13";
BA_ "CompuMethodName" SG_ 1385 SatElv13 "SatElv13";
BA_ "ISignalName" SG_ 1385 SatElv13 "ISatElv13";
BA_ "LongName" SG_ 1385 SatElv13 "Satellite13 Elevation Angle";
BA_ "SysSignalName" SG_ 1385 SatElv13 "SatElv13";
BA_ "CompuMethodName" SG_ 1385 SatAz14 "SatAz14";
BA_ "ISignalName" SG_ 1385 SatAz14 "ISatAz14";
BA_ "LongName" SG_ 1385 SatAz14 "Satellite14 Azimuth Angle";
BA_ "SysSignalName" SG_ 1385 SatAz14 "SatAz14";
BA_ "CompuMethodName" SG_ 1385 SatID13 "SatID13";
BA_ "ISignalName" SG_ 1385 SatID13 "ISatID13";
BA_ "LongName" SG_ 1385 SatID13 "Satellite13 Id";
BA_ "SysSignalName" SG_ 1385 SatID13 "SatID13";
BA_ "CompuMethodName" SG_ 1385 SatCNO14 "SatCNO14";
BA_ "ISignalName" SG_ 1385 SatCNO14 "ISatCNO14";
BA_ "LongName" SG_ 1385 SatCNO14 "Satellite14 Cno";
BA_ "SysSignalName" SG_ 1385 SatCNO14 "SatCNO14";
BA_ "CompuMethodName" SG_ 1385 SatElv14 "SatElv14";
BA_ "ISignalName" SG_ 1385 SatElv14 "ISatElv14";
BA_ "LongName" SG_ 1385 SatElv14 "Satellite14 Elevation Angle";
BA_ "SysSignalName" SG_ 1385 SatElv14 "SatElv14";
BA_ "CompuMethodName" SG_ 1385 SatID14 "SatID14";
BA_ "ISignalName" SG_ 1385 SatID14 "ISatID14";
BA_ "LongName" SG_ 1385 SatID14 "Satellite14 Id";
BA_ "SysSignalName" SG_ 1385 SatID14 "SatID14";
BA_ "CompuMethodName" SG_ 1386 SatAz15 "SatAz15";
BA_ "ISignalName" SG_ 1386 SatAz15 "ISatAz15";
BA_ "LongName" SG_ 1386 SatAz15 "Satellite15 Azimuth Angle";
BA_ "SysSignalName" SG_ 1386 SatAz15 "SatAz15";
BA_ "CompuMethodName" SG_ 1386 SatCNO15 "SatCNO15";
BA_ "ISignalName" SG_ 1386 SatCNO15 "ISatCNO15";
BA_ "LongName" SG_ 1386 SatCNO15 "Satellite15 Cno";
BA_ "SysSignalName" SG_ 1386 SatCNO15 "SatCNO15";
BA_ "CompuMethodName" SG_ 1386 SatElv15 "SatElv15";
BA_ "ISignalName" SG_ 1386 SatElv15 "ISatElv15";
BA_ "LongName" SG_ 1386 SatElv15 "Satellite15 Elevation Angle";
BA_ "SysSignalName" SG_ 1386 SatElv15 "SatElv15";
BA_ "CompuMethodName" SG_ 1386 SatAz16 "SatAz16";
BA_ "ISignalName" SG_ 1386 SatAz16 "ISatAz16";
BA_ "LongName" SG_ 1386 SatAz16 "Satellite16 Azimuth Angle";
BA_ "SysSignalName" SG_ 1386 SatAz16 "SatAz16";
BA_ "CompuMethodName" SG_ 1386 SatID15 "SatID15";
BA_ "ISignalName" SG_ 1386 SatID15 "ISatID15";
BA_ "LongName" SG_ 1386 SatID15 "Satellite15 Id";
BA_ "SysSignalName" SG_ 1386 SatID15 "SatID15";
BA_ "CompuMethodName" SG_ 1386 SatCNO16 "SatCNO16";
BA_ "ISignalName" SG_ 1386 SatCNO16 "ISatCNO16";
BA_ "LongName" SG_ 1386 SatCNO16 "Satellite16 Cno";
BA_ "SysSignalName" SG_ 1386 SatCNO16 "SatCNO16";
BA_ "CompuMethodName" SG_ 1386 SatElv16 "SatElv16";
BA_ "ISignalName" SG_ 1386 SatElv16 "ISatElv16";
BA_ "LongName" SG_ 1386 SatElv16 "Satellite16 Elevation Angle";
BA_ "SysSignalName" SG_ 1386 SatElv16 "SatElv16";
BA_ "CompuMethodName" SG_ 1386 SatID16 "SatID16";
BA_ "ISignalName" SG_ 1386 SatID16 "ISatID16";
BA_ "LongName" SG_ 1386 SatID16 "Satellite16 Id";
BA_ "SysSignalName" SG_ 1386 SatID16 "SatID16";
BA_ "CompuMethodName" SG_ 1387 SatAz19 "SatAz19";
BA_ "ISignalName" SG_ 1387 SatAz19 "ISatAz19";
BA_ "LongName" SG_ 1387 SatAz19 "Satellite19 Azimuth Angle";
BA_ "SysSignalName" SG_ 1387 SatAz19 "SatAz19";
BA_ "CompuMethodName" SG_ 1387 SatCNO19 "SatCNO19";
BA_ "ISignalName" SG_ 1387 SatCNO19 "ISatCNO19";
BA_ "LongName" SG_ 1387 SatCNO19 "Satellite19 Cno";
BA_ "SysSignalName" SG_ 1387 SatCNO19 "SatCNO19";
BA_ "CompuMethodName" SG_ 1387 SatElv19 "SatElv19";
BA_ "ISignalName" SG_ 1387 SatElv19 "ISatElv19";
BA_ "LongName" SG_ 1387 SatElv19 "Satellite19 Elevation Angle";
BA_ "SysSignalName" SG_ 1387 SatElv19 "SatElv19";
BA_ "CompuMethodName" SG_ 1387 SatAz20 "SatAz20";
BA_ "ISignalName" SG_ 1387 SatAz20 "ISatAz20";
BA_ "LongName" SG_ 1387 SatAz20 "Satellite20 Azimuth Angle";
BA_ "SysSignalName" SG_ 1387 SatAz20 "SatAz20";
BA_ "CompuMethodName" SG_ 1387 SatID19 "SatID19";
BA_ "ISignalName" SG_ 1387 SatID19 "ISatID19";
BA_ "LongName" SG_ 1387 SatID19 "Satellite19 Id";
BA_ "SysSignalName" SG_ 1387 SatID19 "SatID19";
BA_ "CompuMethodName" SG_ 1387 SatCNO20 "SatCNO20";
BA_ "ISignalName" SG_ 1387 SatCNO20 "ISatCNO20";
BA_ "LongName" SG_ 1387 SatCNO20 "Satellite20 Cno";
BA_ "SysSignalName" SG_ 1387 SatCNO20 "SatCNO20";
BA_ "CompuMethodName" SG_ 1387 SatElv20 "SatElv20";
BA_ "ISignalName" SG_ 1387 SatElv20 "ISatElv20";
BA_ "LongName" SG_ 1387 SatElv20 "Satellite20 Elevation Angle";
BA_ "SysSignalName" SG_ 1387 SatElv20 "SatElv20";
BA_ "CompuMethodName" SG_ 1387 SatID20 "SatID20";
BA_ "ISignalName" SG_ 1387 SatID20 "ISatID20";
BA_ "LongName" SG_ 1387 SatID20 "Satellite20 Id";
BA_ "SysSignalName" SG_ 1387 SatID20 "SatID20";
BA_ "CompuMethodName" SG_ 1388 SatNum "SatNum";
BA_ "ISignalName" SG_ 1388 SatNum "ISatNum";
BA_ "LongName" SG_ 1388 SatNum "Satellites Number";
BA_ "SysSignalName" SG_ 1388 SatNum "SatNum";
BA_ "CompuMethodName" SG_ 1388 SvGroup "SvGroup";
BA_ "ISignalName" SG_ 1388 SvGroup "ISvGroup";
BA_ "LongName" SG_ 1388 SvGroup "Gpgsv Data Send Group";
BA_ "SysSignalName" SG_ 1388 SvGroup "SvGroup";
BA_ "CompuMethodName" SG_ 1380 SatAz3 "SatAz3";
BA_ "ISignalName" SG_ 1380 SatAz3 "ISatAz3";
BA_ "LongName" SG_ 1380 SatAz3 "Satellite3 Azimuth Angle";
BA_ "SysSignalName" SG_ 1380 SatAz3 "SatAz3";
BA_ "CompuMethodName" SG_ 1380 SatCNO3 "SatCNO3";
BA_ "ISignalName" SG_ 1380 SatCNO3 "ISatCNO3";
BA_ "LongName" SG_ 1380 SatCNO3 "Satellite3 Cno";
BA_ "SysSignalName" SG_ 1380 SatCNO3 "SatCNO3";
BA_ "CompuMethodName" SG_ 1380 SatElv3 "SatElv3";
BA_ "ISignalName" SG_ 1380 SatElv3 "ISatElv3";
BA_ "LongName" SG_ 1380 SatElv3 "Satellite3 Elevation Angle";
BA_ "SysSignalName" SG_ 1380 SatElv3 "SatElv3";
BA_ "CompuMethodName" SG_ 1380 SatAz4 "SatAz4";
BA_ "ISignalName" SG_ 1380 SatAz4 "ISatAz4";
BA_ "LongName" SG_ 1380 SatAz4 "Satellite4 Azimuth Angle";
BA_ "SysSignalName" SG_ 1380 SatAz4 "SatAz4";
BA_ "CompuMethodName" SG_ 1380 SatID3 "SatID3";
BA_ "ISignalName" SG_ 1380 SatID3 "ISatID3";
BA_ "LongName" SG_ 1380 SatID3 "Satellite3 Id";
BA_ "SysSignalName" SG_ 1380 SatID3 "SatID3";
BA_ "CompuMethodName" SG_ 1380 SatCNO4 "SatCNO4";
BA_ "ISignalName" SG_ 1380 SatCNO4 "ISatCNO4";
BA_ "LongName" SG_ 1380 SatCNO4 "Satellite4 Cno";
BA_ "SysSignalName" SG_ 1380 SatCNO4 "SatCNO4";
BA_ "CompuMethodName" SG_ 1380 SatElv4 "SatElv4";
BA_ "ISignalName" SG_ 1380 SatElv4 "ISatElv4";
BA_ "LongName" SG_ 1380 SatElv4 "Satellite4 Elevation Angle";
BA_ "SysSignalName" SG_ 1380 SatElv4 "SatElv4";
BA_ "CompuMethodName" SG_ 1380 SatID4 "SatID4";
BA_ "ISignalName" SG_ 1380 SatID4 "ISatID4";
BA_ "LongName" SG_ 1380 SatID4 "Satellite4 Id";
BA_ "SysSignalName" SG_ 1380 SatID4 "SatID4";
BA_ "CompuMethodName" SG_ 1082 CANprotocolinternalversion "CANprotocolinternalversion";
BA_ "ISignalName" SG_ 1082 CANprotocolinternalversion "ICANprotocolinternalversion";
BA_ "LongName" SG_ 1082 CANprotocolinternalversion "CANprotocolinternalversion";
BA_ "SysSignalName" SG_ 1082 CANprotocolinternalversion "CANprotocolinternalversion";
BA_ "CompuMethodName" SG_ 1082 DiffDataLinkBroken "DiffDataLinkBroken";
BA_ "ISignalName" SG_ 1082 DiffDataLinkBroken "IDiffDataLinkBroken";
BA_ "LongName" SG_ 1082 DiffDataLinkBroken "Diff_Data_Link_Broken";
BA_ "SysSignalName" SG_ 1082 DiffDataLinkBroken "DiffDataLinkBroken";
BA_ "CompuMethodName" SG_ 1082 GNSSAntennasBroken "GNSSAntennasBroken";
BA_ "ISignalName" SG_ 1082 GNSSAntennasBroken "IGNSSAntennasBroken";
BA_ "LongName" SG_ 1082 GNSSAntennasBroken "GNSSAntennasBroken";
BA_ "SysSignalName" SG_ 1082 GNSSAntennasBroken "GNSSAntennasBroken";
BA_ "CompuMethodName" SG_ 1082 GNSSAntennasInfo "GNSSAntennasInfo";
BA_ "ISignalName" SG_ 1082 GNSSAntennasInfo "IGNSSAntennasInfo";
BA_ "LongName" SG_ 1082 GNSSAntennasInfo "GNSSAntennasInfo";
BA_ "SysSignalName" SG_ 1082 GNSSAntennasInfo "GNSSAntennasInfo";
BA_ "CompuMethodName" SG_ 1082 Velnorthsigma "Velnorthsigma";
BA_ "ISignalName" SG_ 1082 Velnorthsigma "IVelnorthsigma";
BA_ "LongName" SG_ 1082 Velnorthsigma "Velnorthsigma";
BA_ "SysSignalName" SG_ 1082 Velnorthsigma "Velnorthsigma";
BA_ "CompuMethodName" SG_ 1082 Veleastsigma "Veleastsigma";
BA_ "ISignalName" SG_ 1082 Veleastsigma "IVeleastsigma";
BA_ "LongName" SG_ 1082 Veleastsigma "Veleastsigma";
BA_ "SysSignalName" SG_ 1082 Veleastsigma "Veleastsigma";
BA_ "CompuMethodName" SG_ 766 SatNoInAttitudeRTK "SatNoInAttitudeRTK";
BA_ "ISignalName" SG_ 766 SatNoInAttitudeRTK "ISatNoInAttitudeRTK";
BA_ "LongName" SG_ 766 SatNoInAttitudeRTK "SatNoInAttitudeRTK";
BA_ "SysSignalName" SG_ 766 SatNoInAttitudeRTK "SatNoInAttitudeRTK";
BA_ "CompuMethodName" SG_ 766 SatNoInPositionRTK "SatNoInPositionRTK";
BA_ "ISignalName" SG_ 766 SatNoInPositionRTK "ISatNoInPositionRTK";
BA_ "LongName" SG_ 766 SatNoInPositionRTK "SatNoInPositionRTK";
BA_ "SysSignalName" SG_ 766 SatNoInPositionRTK "SatNoInPositionRTK";
BA_ "CompuMethodName" SG_ 766 EastVelocityRTK "EastVelocityRTK";
BA_ "ISignalName" SG_ 766 EastVelocityRTK "IEastVelocityRTK";
BA_ "LongName" SG_ 766 EastVelocityRTK "EastVelocityRTK";
BA_ "SysSignalName" SG_ 766 EastVelocityRTK "EastVelocityRTK";
BA_ "CompuMethodName" SG_ 766 NorthVelocityRTK "NorthVelocityRTK";
BA_ "ISignalName" SG_ 766 NorthVelocityRTK "INorthVelocityRTK";
BA_ "LongName" SG_ 766 NorthVelocityRTK "NorthVelocityRTK";
BA_ "SysSignalName" SG_ 766 NorthVelocityRTK "NorthVelocityRTK";
BA_ "CompuMethodName" SG_ 335 DiffAgeInfo "DiffAgeInfo";
BA_ "ISignalName" SG_ 335 DiffAgeInfo "IDiffAgeInfo";
BA_ "LongName" SG_ 335 DiffAgeInfo "DiffAgeInfo";
BA_ "SysSignalName" SG_ 335 DiffAgeInfo "DiffAgeInfo";
BA_ "CompuMethodName" SG_ 335 PositionAttitudeStatus "PositionAttitudeStatus";
BA_ "ISignalName" SG_ 335 PositionAttitudeStatus "IPositionAttitudeStatus";
BA_ "LongName" SG_ 335 PositionAttitudeStatus "Position_And_Attitudestatus";
BA_ "SysSignalName" SG_ 335 PositionAttitudeStatus "PositionAttitudeStatus";
BA_ "CompuMethodName" SG_ 335 BaseLineLen "BaseLineLen";
BA_ "ISignalName" SG_ 335 BaseLineLen "IBaseLineLen";
BA_ "LongName" SG_ 335 BaseLineLen "BaseLineLength";
BA_ "SysSignalName" SG_ 335 BaseLineLen "BaseLineLen";
BA_ "CompuMethodName" SG_ 335 Veldownsigma "Veldownsigma";
BA_ "ISignalName" SG_ 335 Veldownsigma "IVeldownsigma";
BA_ "LongName" SG_ 335 Veldownsigma "Veldownsigma";
BA_ "SysSignalName" SG_ 335 Veldownsigma "Veldownsigma";
BA_ "CompuMethodName" SG_ 335 DownVelocityRTK "DownVelocityRTK";
BA_ "ISignalName" SG_ 335 DownVelocityRTK "IDownVelocityRTK";
BA_ "LongName" SG_ 335 DownVelocityRTK "DownVelocityRTK";
BA_ "SysSignalName" SG_ 335 DownVelocityRTK "DownVelocityRTK";
BA_ "CompuMethodName" SG_ 887 IAM_100ms_Group08_CRC "IAM_100ms_Group08_CRC";
BA_ "ISignalName" SG_ 887 IAM_100ms_Group08_CRC "IIAM_100ms_Group08_CRC";
BA_ "SysSignalName" SG_ 887 IAM_100ms_Group08_CRC "IAM_100ms_Group08_CRC";
BA_ "CompuMethodName" SG_ 887 IAM_100ms_Group08_RC "IAM_100ms_Group08_RC";
BA_ "ISignalName" SG_ 887 IAM_100ms_Group08_RC "IIAM_100ms_Group08_RC";
BA_ "SysSignalName" SG_ 887 IAM_100ms_Group08_RC "IAM_100ms_Group08_RC";
BA_ "CompuMethodName" SG_ 887 IAM_100ms_Group08_Reserved15 "IAM_100ms_Group08_Reserved15";
BA_ "GenSigStartValue" SG_ 887 IAM_100ms_Group08_Reserved15 15;
BA_ "ISignalName" SG_ 887 IAM_100ms_Group08_Reserved15 "IIAM_100ms_Group08_Reserved15";
BA_ "SysSignalName" SG_ 887 IAM_100ms_Group08_Reserved15 "IAM_100ms_Group08_Reserved15";
BA_ "CompuMethodName" SG_ 887 LatSigma "LatSigma";
BA_ "ISignalName" SG_ 887 LatSigma "ILatSigma";
BA_ "LongName" SG_ 887 LatSigma "LatSigma";
BA_ "SysSignalName" SG_ 887 LatSigma "LatSigma";
BA_ "CompuMethodName" SG_ 887 LonSigma "LonSigma";
BA_ "ISignalName" SG_ 887 LonSigma "ILonSigma";
BA_ "LongName" SG_ 887 LonSigma "LonSigma";
BA_ "SysSignalName" SG_ 887 LonSigma "LonSigma";
BA_ "CompuMethodName" SG_ 887 AltSigma "AltSigma";
BA_ "ISignalName" SG_ 887 AltSigma "IAltSigma";
BA_ "LongName" SG_ 887 AltSigma "AltSigma";
BA_ "SysSignalName" SG_ 887 AltSigma "AltSigma";
BA_ "CompuMethodName" SG_ 912 IAM_ZONE_100ms_Group34_CRC "IAM_ZONE_100ms_Group34_CRC";
BA_ "ISignalName" SG_ 912 IAM_ZONE_100ms_Group34_CRC "IIAM_ZONE_100ms_Group34_CRC";
BA_ "SysSignalName" SG_ 912 IAM_ZONE_100ms_Group34_CRC "IAM_ZONE_100ms_Group34_CRC";
BA_ "CompuMethodName" SG_ 912 IAM_ZONE_100ms_Group34_RC "IAM_ZONE_100ms_Group34_RC";
BA_ "ISignalName" SG_ 912 IAM_ZONE_100ms_Group34_RC "IIAM_ZONE_100ms_Group34_RC";
BA_ "SysSignalName" SG_ 912 IAM_ZONE_100ms_Group34_RC "IAM_ZONE_100ms_Group34_RC";
BA_ "CompuMethodName" SG_ 912 IAM_ZONE_100ms_Group34_Reserved1 "IAM_ZONE_100ms_Group34_Reserved15";
BA_ "GenSigStartValue" SG_ 912 IAM_ZONE_100ms_Group34_Reserved1 15;
BA_ "ISignalName" SG_ 912 IAM_ZONE_100ms_Group34_Reserved1 "IIAM_ZONE_100ms_Group34_Reserved15";
BA_ "SysSignalName" SG_ 912 IAM_ZONE_100ms_Group34_Reserved1 "IAM_ZONE_100ms_Group34_Reserved15";
BA_ "SystemSignalLongSymbol" SG_ 912 IAM_ZONE_100ms_Group34_Reserved1 "IAM_ZONE_100ms_Group34_Reserved15";
BA_ "CompuMethodName" SG_ 912 Pdop "Pdop";
BA_ "ISignalName" SG_ 912 Pdop "IPdop";
BA_ "LongName" SG_ 912 Pdop "Position Dilution Of Precision";
BA_ "SysSignalName" SG_ 912 Pdop "Pdop";
BA_ "CompuMethodName" SG_ 912 IAM_ZONE_100ms_Group34_Reserved2 "IAM_ZONE_100ms_Group34_Reserved23";
BA_ "GenSigStartValue" SG_ 912 IAM_ZONE_100ms_Group34_Reserved2 3;
BA_ "ISignalName" SG_ 912 IAM_ZONE_100ms_Group34_Reserved2 "IIAM_ZONE_100ms_Group34_Reserved23";
BA_ "SysSignalName" SG_ 912 IAM_ZONE_100ms_Group34_Reserved2 "IAM_ZONE_100ms_Group34_Reserved23";
BA_ "SystemSignalLongSymbol" SG_ 912 IAM_ZONE_100ms_Group34_Reserved2 "IAM_ZONE_100ms_Group34_Reserved23";
BA_ "CompuMethodName" SG_ 912 Vdop "Vdop";
BA_ "ISignalName" SG_ 912 Vdop "IVdop";
BA_ "LongName" SG_ 912 Vdop "Vertical Dilution Of Precision";
BA_ "SysSignalName" SG_ 912 Vdop "Vdop";
BA_ "CompuMethodName" SG_ 912 IAM_ZONE_100ms_Group34_Reserved3 "IAM_ZONE_100ms_Group34_Reserved39";
BA_ "GenSigStartValue" SG_ 912 IAM_ZONE_100ms_Group34_Reserved3 3;
BA_ "ISignalName" SG_ 912 IAM_ZONE_100ms_Group34_Reserved3 "IIAM_ZONE_100ms_Group34_Reserved39";
BA_ "SysSignalName" SG_ 912 IAM_ZONE_100ms_Group34_Reserved3 "IAM_ZONE_100ms_Group34_Reserved39";
BA_ "SystemSignalLongSymbol" SG_ 912 IAM_ZONE_100ms_Group34_Reserved3 "IAM_ZONE_100ms_Group34_Reserved39";
BA_ "CompuMethodName" SG_ 912 Hdop "Hdop";
BA_ "ISignalName" SG_ 912 Hdop "IHdop";
BA_ "LongName" SG_ 912 Hdop "Horizontal Dilution Of Position";
BA_ "SysSignalName" SG_ 912 Hdop "Hdop";
BA_ "CompuMethodName" SG_ 912 IAM_ZONE_100ms_Group34_Reserved5 "IAM_ZONE_100ms_Group34_Reserved55";
BA_ "GenSigStartValue" SG_ 912 IAM_ZONE_100ms_Group34_Reserved5 3;
BA_ "ISignalName" SG_ 912 IAM_ZONE_100ms_Group34_Reserved5 "IIAM_ZONE_100ms_Group34_Reserved55";
BA_ "SysSignalName" SG_ 912 IAM_ZONE_100ms_Group34_Reserved5 "IAM_ZONE_100ms_Group34_Reserved55";
BA_ "SystemSignalLongSymbol" SG_ 912 IAM_ZONE_100ms_Group34_Reserved5 "IAM_ZONE_100ms_Group34_Reserved55";
BA_ "CompuMethodName" SG_ 874 IAM_ZONE_100ms_Group40_CRC "IAM_ZONE_100ms_Group40_CRC";
BA_ "ISignalName" SG_ 874 IAM_ZONE_100ms_Group40_CRC "IIAM_ZONE_100ms_Group40_CRC";
BA_ "SysSignalName" SG_ 874 IAM_ZONE_100ms_Group40_CRC "IAM_ZONE_100ms_Group40_CRC";
BA_ "CompuMethodName" SG_ 874 IAM_ZONE_100ms_Group40_RC "IAM_ZONE_100ms_Group40_RC";
BA_ "ISignalName" SG_ 874 IAM_ZONE_100ms_Group40_RC "IIAM_ZONE_100ms_Group40_RC";
BA_ "SysSignalName" SG_ 874 IAM_ZONE_100ms_Group40_RC "IAM_ZONE_100ms_Group40_RC";
BA_ "CompuMethodName" SG_ 874 IAM_ZONE_100ms_Group40_Reserved1 "IAM_ZONE_100ms_Group40_Reserved15";
BA_ "GenSigStartValue" SG_ 874 IAM_ZONE_100ms_Group40_Reserved1 15;
BA_ "ISignalName" SG_ 874 IAM_ZONE_100ms_Group40_Reserved1 "IIAM_ZONE_100ms_Group40_Reserved15";
BA_ "SysSignalName" SG_ 874 IAM_ZONE_100ms_Group40_Reserved1 "IAM_ZONE_100ms_Group40_Reserved15";
BA_ "SystemSignalLongSymbol" SG_ 874 IAM_ZONE_100ms_Group40_Reserved1 "IAM_ZONE_100ms_Group40_Reserved15";
BA_ "CompuMethodName" SG_ 874 AltitudeRTK "AltitudeRTK";
BA_ "ISignalName" SG_ 874 AltitudeRTK "IAltitudeRTK";
BA_ "LongName" SG_ 874 AltitudeRTK "AltitudeRTK";
BA_ "SysSignalName" SG_ 874 AltitudeRTK "AltitudeRTK";
BA_ "CompuMethodName" SG_ 874 HeadingRTK "HeadingRTK";
BA_ "ISignalName" SG_ 874 HeadingRTK "IHeadingRTK";
BA_ "LongName" SG_ 874 HeadingRTK "HeadingRTK";
BA_ "SysSignalName" SG_ 874 HeadingRTK "HeadingRTK";
BA_ "CompuMethodName" SG_ 874 IAM_ZONE_100ms_Group40_Reserved6 "IAM_ZONE_100ms_Group40_Reserved63";
BA_ "GenSigStartValue" SG_ 874 IAM_ZONE_100ms_Group40_Reserved6 255;
BA_ "ISignalName" SG_ 874 IAM_ZONE_100ms_Group40_Reserved6 "IIAM_ZONE_100ms_Group40_Reserved63";
BA_ "SysSignalName" SG_ 874 IAM_ZONE_100ms_Group40_Reserved6 "IAM_ZONE_100ms_Group40_Reserved63";
BA_ "SystemSignalLongSymbol" SG_ 874 IAM_ZONE_100ms_Group40_Reserved6 "IAM_ZONE_100ms_Group40_Reserved63";
BA_ "CompuMethodName" SG_ 336 IAM_20ms_Group32_CRC "IAM_20ms_Group32_CRC";
BA_ "ISignalName" SG_ 336 IAM_20ms_Group32_CRC "IIAM_20ms_Group32_CRC";
BA_ "SysSignalName" SG_ 336 IAM_20ms_Group32_CRC "IAM_20ms_Group32_CRC";
BA_ "CompuMethodName" SG_ 336 IAM_20ms_Group32_RC "IAM_20ms_Group32_RC";
BA_ "ISignalName" SG_ 336 IAM_20ms_Group32_RC "IIAM_20ms_Group32_RC";
BA_ "SysSignalName" SG_ 336 IAM_20ms_Group32_RC "IAM_20ms_Group32_RC";
BA_ "CompuMethodName" SG_ 336 RmtParkngAstParkngOutDircnSeln "RmtParkngAstParkngOutDircnSeln";
BA_ "ISignalName" SG_ 336 RmtParkngAstParkngOutDircnSeln "IRmtParkngAstParkngOutDircnSeln";
BA_ "LongName" SG_ 336 RmtParkngAstParkngOutDircnSeln "Remote Parking Assist Parking Out Direction Selection";
BA_ "SysSignalName" SG_ 336 RmtParkngAstParkngOutDircnSeln "RmtParkngAstParkngOutDircnSeln";
BA_ "CompuMethodName" SG_ 336 RmtParkngAstBtnSts "RmtParkngAstBtnSts";
BA_ "ISignalName" SG_ 336 RmtParkngAstBtnSts "IRmtParkngAstBtnSts";
BA_ "LongName" SG_ 336 RmtParkngAstBtnSts "Remote Parking Assist Button Status";
BA_ "SysSignalName" SG_ 336 RmtParkngAstBtnSts "RmtParkngAstBtnSts";
BA_ "CompuMethodName" SG_ 336 VehFwdSwReq "VehFwdSwReq";
BA_ "ISignalName" SG_ 336 VehFwdSwReq "IVehFwdSwReq";
BA_ "LongName" SG_ 336 VehFwdSwReq "Vehicle Forward Switch Request";
BA_ "SysSignalName" SG_ 336 VehFwdSwReq "VehFwdSwReq";
BA_ "CompuMethodName" SG_ 336 VehBkwdSwReq "VehBkwdSwReq";
BA_ "ISignalName" SG_ 336 VehBkwdSwReq "IVehBkwdSwReq";
BA_ "LongName" SG_ 336 VehBkwdSwReq "Vehicle Backward Switch Request";
BA_ "SysSignalName" SG_ 336 VehBkwdSwReq "VehBkwdSwReq";
BA_ "CompuMethodName" SG_ 336 RmtParkngAstDvcSts "RmtParkngAstDvcSts";
BA_ "ISignalName" SG_ 336 RmtParkngAstDvcSts "IRmtParkngAstDvcSts";
BA_ "LongName" SG_ 336 RmtParkngAstDvcSts "Remote Parking Assist Device Status";
BA_ "SysSignalName" SG_ 336 RmtParkngAstDvcSts "RmtParkngAstDvcSts";
BA_ "CompuMethodName" SG_ 336 RmtDrvrTrgtEPSStrgWhlAng "RmtDrvrTrgtEPSStrgWhlAng";
BA_ "GenSigStartValue" SG_ 336 RmtDrvrTrgtEPSStrgWhlAng 32768;
BA_ "ISignalName" SG_ 336 RmtDrvrTrgtEPSStrgWhlAng "IRmtDrvrTrgtEPSStrgWhlAng";
BA_ "LongName" SG_ 336 RmtDrvrTrgtEPSStrgWhlAng "Remote Driver Target EPS Steering Wheel Angle";
BA_ "SysSignalName" SG_ 336 RmtDrvrTrgtEPSStrgWhlAng "RmtDrvrTrgtEPSStrgWhlAng";
BA_ "CompuMethodName" SG_ 336 VehRoadWhlRReq "VehRoadWhlRReq";
BA_ "ISignalName" SG_ 336 VehRoadWhlRReq "IVehRoadWhlRReq";
BA_ "LongName" SG_ 336 VehRoadWhlRReq "Vehicle Road Wheel Right Request";
BA_ "SysSignalName" SG_ 336 VehRoadWhlRReq "VehRoadWhlRReq";
BA_ "CompuMethodName" SG_ 336 VehRoadWhlLReq "VehRoadWhlLReq";
BA_ "ISignalName" SG_ 336 VehRoadWhlLReq "IVehRoadWhlLReq";
BA_ "LongName" SG_ 336 VehRoadWhlLReq "Vehicle Road Wheel Left Request";
BA_ "SysSignalName" SG_ 336 VehRoadWhlLReq "VehRoadWhlLReq";
BA_ "CompuMethodName" SG_ 336 RmtParkngAstAbotBtnSts "RmtParkngAstAbotBtnSts";
BA_ "GenSigStartValue" SG_ 336 RmtParkngAstAbotBtnSts 1;
BA_ "ISignalName" SG_ 336 RmtParkngAstAbotBtnSts "IRmtParkngAstAbotBtnSts";
BA_ "LongName" SG_ 336 RmtParkngAstAbotBtnSts "Remote Parking Assist Abort Button Status";
BA_ "SysSignalName" SG_ 336 RmtParkngAstAbotBtnSts "RmtParkngAstAbotBtnSts";
BA_ "CompuMethodName" SG_ 336 RmtParkngAstDvcFlrRsn "RmtParkngAstDvcFlrRsn";
BA_ "ISignalName" SG_ 336 RmtParkngAstDvcFlrRsn "IRmtParkngAstDvcFlrRsn";
BA_ "LongName" SG_ 336 RmtParkngAstDvcFlrRsn "Remote Parking Assist Device Failure Reason";
BA_ "SysSignalName" SG_ 336 RmtParkngAstDvcFlrRsn "RmtParkngAstDvcFlrRsn";
BA_ "CompuMethodName" SG_ 336 IAM_20ms_Group32_Reserved1 "IAM_20ms_Group32_Reserved1";
BA_ "GenSigStartValue" SG_ 336 IAM_20ms_Group32_Reserved1 15;
BA_ "ISignalName" SG_ 336 IAM_20ms_Group32_Reserved1 "IIAM_20ms_Group32_Reserved1";
BA_ "SysSignalName" SG_ 336 IAM_20ms_Group32_Reserved1 "IAM_20ms_Group32_Reserved1";
BA_ "CompuMethodName" SG_ 336 VehRoadWhlRReqV "VehRoadWhlRReqV";
BA_ "ISignalName" SG_ 336 VehRoadWhlRReqV "IVehRoadWhlRReqV";
BA_ "LongName" SG_ 336 VehRoadWhlRReqV "Vehicle Road Wheel Right Request Validity";
BA_ "SysSignalName" SG_ 336 VehRoadWhlRReqV "VehRoadWhlRReqV";
BA_ "CompuMethodName" SG_ 336 VehRoadWhlLReqV "VehRoadWhlLReqV";
BA_ "ISignalName" SG_ 336 VehRoadWhlLReqV "IVehRoadWhlLReqV";
BA_ "LongName" SG_ 336 VehRoadWhlLReqV "Vehicle Road Wheel Left Request Validity";
BA_ "SysSignalName" SG_ 336 VehRoadWhlLReqV "VehRoadWhlLReqV";
BA_ "CompuMethodName" SG_ 336 VehFwdSwReqV "VehFwdSwReqV";
BA_ "ISignalName" SG_ 336 VehFwdSwReqV "IVehFwdSwReqV";
BA_ "LongName" SG_ 336 VehFwdSwReqV "Vehicle Forward Switch Request Validity";
BA_ "SysSignalName" SG_ 336 VehFwdSwReqV "VehFwdSwReqV";
BA_ "CompuMethodName" SG_ 336 VehBkwdSwReqV "VehBkwdSwReqV";
BA_ "ISignalName" SG_ 336 VehBkwdSwReqV "IVehBkwdSwReqV";
BA_ "LongName" SG_ 336 VehBkwdSwReqV "Vehicle Backward Switch Request Validity";
BA_ "SysSignalName" SG_ 336 VehBkwdSwReqV "VehBkwdSwReqV";
BA_ "CompuMethodName" SG_ 336 IAM_20ms_Group32_Reserved2 "IAM_20ms_Group32_Reserved2";
BA_ "GenSigStartValue" SG_ 336 IAM_20ms_Group32_Reserved2 255;
BA_ "ISignalName" SG_ 336 IAM_20ms_Group32_Reserved2 "IIAM_20ms_Group32_Reserved2";
BA_ "SysSignalName" SG_ 336 IAM_20ms_Group32_Reserved2 "IAM_20ms_Group32_Reserved2";
BA_ "CompuMethodName" SG_ 336 IAM_20ms_Group32_Reserved3 "IAM_20ms_Group32_Reserved3";
BA_ "GenSigStartValue" SG_ 336 IAM_20ms_Group32_Reserved3 255;
BA_ "ISignalName" SG_ 336 IAM_20ms_Group32_Reserved3 "IIAM_20ms_Group32_Reserved3";
BA_ "SysSignalName" SG_ 336 IAM_20ms_Group32_Reserved3 "IAM_20ms_Group32_Reserved3";
BA_ "CompuMethodName" SG_ 336 IAM_20ms_Group32_Reserved4 "IAM_20ms_Group32_Reserved4";
BA_ "GenSigStartValue" SG_ 336 IAM_20ms_Group32_Reserved4 255;
BA_ "ISignalName" SG_ 336 IAM_20ms_Group32_Reserved4 "IIAM_20ms_Group32_Reserved4";
BA_ "SysSignalName" SG_ 336 IAM_20ms_Group32_Reserved4 "IAM_20ms_Group32_Reserved4";
BA_ "CompuMethodName" SG_ 336 IAM_20ms_Group32_Reserved5 "IAM_20ms_Group32_Reserved5";
BA_ "GenSigStartValue" SG_ 336 IAM_20ms_Group32_Reserved5 255;
BA_ "ISignalName" SG_ 336 IAM_20ms_Group32_Reserved5 "IIAM_20ms_Group32_Reserved5";
BA_ "SysSignalName" SG_ 336 IAM_20ms_Group32_Reserved5 "IAM_20ms_Group32_Reserved5";
BA_ "CompuMethodName" SG_ 336 IAM_20ms_Group32_Reserved6 "IAM_20ms_Group32_Reserved6";
BA_ "GenSigStartValue" SG_ 336 IAM_20ms_Group32_Reserved6 255;
BA_ "ISignalName" SG_ 336 IAM_20ms_Group32_Reserved6 "IIAM_20ms_Group32_Reserved6";
BA_ "SysSignalName" SG_ 336 IAM_20ms_Group32_Reserved6 "IAM_20ms_Group32_Reserved6";
BA_ "CompuMethodName" SG_ 336 IAM_20ms_Group32_Reserved7 "IAM_20ms_Group32_Reserved7";
BA_ "GenSigStartValue" SG_ 336 IAM_20ms_Group32_Reserved7 255;
BA_ "ISignalName" SG_ 336 IAM_20ms_Group32_Reserved7 "IIAM_20ms_Group32_Reserved7";
BA_ "SysSignalName" SG_ 336 IAM_20ms_Group32_Reserved7 "IAM_20ms_Group32_Reserved7";
BA_ "CompuMethodName" SG_ 336 IAM_20ms_Group32_Reserved8 "IAM_20ms_Group32_Reserved8";
BA_ "GenSigStartValue" SG_ 336 IAM_20ms_Group32_Reserved8 255;
BA_ "ISignalName" SG_ 336 IAM_20ms_Group32_Reserved8 "IIAM_20ms_Group32_Reserved8";
BA_ "SysSignalName" SG_ 336 IAM_20ms_Group32_Reserved8 "IAM_20ms_Group32_Reserved8";
BA_ "CompuMethodName" SG_ 336 IAM_20ms_Group32_Reserved9 "IAM_20ms_Group32_Reserved9";
BA_ "GenSigStartValue" SG_ 336 IAM_20ms_Group32_Reserved9 255;
BA_ "ISignalName" SG_ 336 IAM_20ms_Group32_Reserved9 "IIAM_20ms_Group32_Reserved9";
BA_ "SysSignalName" SG_ 336 IAM_20ms_Group32_Reserved9 "IAM_20ms_Group32_Reserved9";
BA_ "CompuMethodName" SG_ 336 IAM_20ms_Group32_Reserved10 "IAM_20ms_Group32_Reserved10";
BA_ "GenSigStartValue" SG_ 336 IAM_20ms_Group32_Reserved10 255;
BA_ "ISignalName" SG_ 336 IAM_20ms_Group32_Reserved10 "IIAM_20ms_Group32_Reserved10";
BA_ "SysSignalName" SG_ 336 IAM_20ms_Group32_Reserved10 "IAM_20ms_Group32_Reserved10";
BA_ "CompuMethodName" SG_ 89 IAMReststs "IAMReststs";
BA_ "ISignalName" SG_ 89 IAMReststs "IIAMReststs";
BA_ "LongName" SG_ 89 IAMReststs "IAM rest status";
BA_ "SysSignalName" SG_ 89 IAMReststs "IAMReststs";
BA_ "CompuMethodName" SG_ 1000 TrfcForbidDist "TrfcForbidDist";
BA_ "ISignalName" SG_ 1000 TrfcForbidDist "ITrfcForbidDist";
BA_ "LongName" SG_ 1000 TrfcForbidDist "Traffic_Forbidden_Distance";
BA_ "SysSignalName" SG_ 1000 TrfcForbidDist "TrfcForbidDist";
BA_ "CompuMethodName" SG_ 1000 TrfcInfoSignDist "TrfcInfoSignDist";
BA_ "ISignalName" SG_ 1000 TrfcInfoSignDist "ITrfcInfoSignDist";
BA_ "LongName" SG_ 1000 TrfcInfoSignDist "Traffic_Information_Distance";
BA_ "SysSignalName" SG_ 1000 TrfcInfoSignDist "TrfcInfoSignDist";
BA_ "CompuMethodName" SG_ 1000 SmtKeyAuthnSubModRunSts "SmtKeyAuthnSubModRunSts";
BA_ "ISignalName" SG_ 1000 SmtKeyAuthnSubModRunSts "ISmtKeyAuthnSubModRunSts";
BA_ "LongName" SG_ 1000 SmtKeyAuthnSubModRunSts "Smart_Key__Authentication_Smart_Key_Module_Run_Status";
BA_ "SysSignalName" SG_ 1000 SmtKeyAuthnSubModRunSts "SmtKeyAuthnSubModRunSts";
BA_ "CompuMethodName" SG_ 811 IAM_100ms_Group18_CRC "IAM_100ms_Group18_CRC";
BA_ "ISignalName" SG_ 811 IAM_100ms_Group18_CRC "IIAM_100ms_Group18_CRC";
BA_ "SysSignalName" SG_ 811 IAM_100ms_Group18_CRC "IAM_100ms_Group18_CRC";
BA_ "CompuMethodName" SG_ 811 IAM_100ms_Group18_RC "IAM_100ms_Group18_RC";
BA_ "ISignalName" SG_ 811 IAM_100ms_Group18_RC "IIAM_100ms_Group18_RC";
BA_ "SysSignalName" SG_ 811 IAM_100ms_Group18_RC "IAM_100ms_Group18_RC";
BA_ "CompuMethodName" SG_ 811 IAM_100ms_Group18_Reserved15 "IAM_100ms_Group18_Reserved15";
BA_ "GenSigStartValue" SG_ 811 IAM_100ms_Group18_Reserved15 15;
BA_ "ISignalName" SG_ 811 IAM_100ms_Group18_Reserved15 "IIAM_100ms_Group18_Reserved15";
BA_ "SysSignalName" SG_ 811 IAM_100ms_Group18_Reserved15 "IAM_100ms_Group18_Reserved15";
BA_ "CompuMethodName" SG_ 811 PitchRTK "PitchRTK";
BA_ "ISignalName" SG_ 811 PitchRTK "IPitchRTK";
BA_ "LongName" SG_ 811 PitchRTK "PitchRTK";
BA_ "SysSignalName" SG_ 811 PitchRTK "PitchRTK";
BA_ "CompuMethodName" SG_ 811 HeadingSigma "HeadingSigma";
BA_ "ISignalName" SG_ 811 HeadingSigma "IHeadingSigma";
BA_ "LongName" SG_ 811 HeadingSigma "HeadingSigma";
BA_ "SysSignalName" SG_ 811 HeadingSigma "HeadingSigma";
BA_ "CompuMethodName" SG_ 811 PitchSigma "PitchSigma";
BA_ "ISignalName" SG_ 811 PitchSigma "IPitchSigma";
BA_ "LongName" SG_ 811 PitchSigma "PitchSigma";
BA_ "SysSignalName" SG_ 811 PitchSigma "PitchSigma";
BA_ "CompuMethodName" SG_ 1358 KeyDeleResp "KeyDeleResp";
BA_ "ISignalName" SG_ 1358 KeyDeleResp "IKeyDeleResp";
BA_ "LongName" SG_ 1358 KeyDeleResp "Key Delete  Response";
BA_ "SysSignalName" SG_ 1358 KeyDeleResp "KeyDeleResp";
BA_ "CompuMethodName" SG_ 1358 AIParkngReq "AIParkngReq";
BA_ "ISignalName" SG_ 1358 AIParkngReq "IAIParkngReq";
BA_ "LongName" SG_ 1358 AIParkngReq "ParkingRequest";
BA_ "SysSignalName" SG_ 1358 AIParkngReq "AIParkngReq";
BA_ "CompuMethodName" SG_ 810 IAM_ZONE_100ms_Group57_CRC "IAM_ZONE_100ms_Group57_CRC";
BA_ "ISignalName" SG_ 810 IAM_ZONE_100ms_Group57_CRC "IIAM_ZONE_100ms_Group57_CRC";
BA_ "SysSignalName" SG_ 810 IAM_ZONE_100ms_Group57_CRC "IAM_ZONE_100ms_Group57_CRC";
BA_ "CompuMethodName" SG_ 810 IAM_ZONE_100ms_Group57_RC "IAM_ZONE_100ms_Group57_RC";
BA_ "ISignalName" SG_ 810 IAM_ZONE_100ms_Group57_RC "IIAM_ZONE_100ms_Group57_RC";
BA_ "SysSignalName" SG_ 810 IAM_ZONE_100ms_Group57_RC "IAM_ZONE_100ms_Group57_RC";
BA_ "CompuMethodName" SG_ 810 IAM_ZONE_100ms_Group57_Reserved1 "IAM_ZONE_100ms_Group57_Reserved15";
BA_ "GenSigStartValue" SG_ 810 IAM_ZONE_100ms_Group57_Reserved1 15;
BA_ "ISignalName" SG_ 810 IAM_ZONE_100ms_Group57_Reserved1 "IIAM_ZONE_100ms_Group57_Reserved15";
BA_ "SysSignalName" SG_ 810 IAM_ZONE_100ms_Group57_Reserved1 "IAM_ZONE_100ms_Group57_Reserved15";
BA_ "SystemSignalLongSymbol" SG_ 810 IAM_ZONE_100ms_Group57_Reserved1 "IAM_ZONE_100ms_Group57_Reserved15";
BA_ "CompuMethodName" SG_ 810 LongitudeRTK "LongitudeRTK";
BA_ "ISignalName" SG_ 810 LongitudeRTK "ILongitudeRTK";
BA_ "LongName" SG_ 810 LongitudeRTK "LongitudeRTK";
BA_ "SysSignalName" SG_ 810 LongitudeRTK "LongitudeRTK";
BA_ "CompuMethodName" SG_ 810 IAM_ZONE_100ms_Group57_Reserved6 "IAM_ZONE_100ms_Group57_Reserved63";
BA_ "GenSigStartValue" SG_ 810 IAM_ZONE_100ms_Group57_Reserved6 255;
BA_ "ISignalName" SG_ 810 IAM_ZONE_100ms_Group57_Reserved6 "IIAM_ZONE_100ms_Group57_Reserved63";
BA_ "SysSignalName" SG_ 810 IAM_ZONE_100ms_Group57_Reserved6 "IAM_ZONE_100ms_Group57_Reserved63";
BA_ "SystemSignalLongSymbol" SG_ 810 IAM_ZONE_100ms_Group57_Reserved6 "IAM_ZONE_100ms_Group57_Reserved63";
BA_ "CompuMethodName" SG_ 793 IAM_ZONE_100ms_Group35_CRC "IAM_ZONE_100ms_Group35_CRC";
BA_ "ISignalName" SG_ 793 IAM_ZONE_100ms_Group35_CRC "IIAM_ZONE_100ms_Group35_CRC";
BA_ "SysSignalName" SG_ 793 IAM_ZONE_100ms_Group35_CRC "IAM_ZONE_100ms_Group35_CRC";
BA_ "CompuMethodName" SG_ 793 IAM_ZONE_100ms_Group35_RC "IAM_ZONE_100ms_Group35_RC";
BA_ "ISignalName" SG_ 793 IAM_ZONE_100ms_Group35_RC "IIAM_ZONE_100ms_Group35_RC";
BA_ "SysSignalName" SG_ 793 IAM_ZONE_100ms_Group35_RC "IAM_ZONE_100ms_Group35_RC";
BA_ "CompuMethodName" SG_ 793 IAM_ZONE_100ms_Group35_Reserved1 "IAM_ZONE_100ms_Group35_Reserved15";
BA_ "GenSigStartValue" SG_ 793 IAM_ZONE_100ms_Group35_Reserved1 15;
BA_ "ISignalName" SG_ 793 IAM_ZONE_100ms_Group35_Reserved1 "IIAM_ZONE_100ms_Group35_Reserved15";
BA_ "SysSignalName" SG_ 793 IAM_ZONE_100ms_Group35_Reserved1 "IAM_ZONE_100ms_Group35_Reserved15";
BA_ "SystemSignalLongSymbol" SG_ 793 IAM_ZONE_100ms_Group35_Reserved1 "IAM_ZONE_100ms_Group35_Reserved15";
BA_ "CompuMethodName" SG_ 793 GNSSUTCTime "GNSSUTCTime";
BA_ "ISignalName" SG_ 793 GNSSUTCTime "IGNSSUTCTime";
BA_ "LongName" SG_ 793 GNSSUTCTime "Gnss Utc Time";
BA_ "SysSignalName" SG_ 793 GNSSUTCTime "GNSSUTCTime";
BA_ "CompuMethodName" SG_ 793 GNSSF9HCounter "GNSSF9HCounter";
BA_ "ISignalName" SG_ 793 GNSSF9HCounter "IGNSSF9HCounter";
BA_ "LongName" SG_ 793 GNSSF9HCounter "GNSSF9HCounter";
BA_ "SysSignalName" SG_ 793 GNSSF9HCounter "GNSSF9HCounter";
BA_ "CompuMethodName" SG_ 773 IAM_ZONE_100ms_Group13_CRC "IAM_ZONE_100ms_Group13_CRC";
BA_ "ISignalName" SG_ 773 IAM_ZONE_100ms_Group13_CRC "IIAM_ZONE_100ms_Group13_CRC";
BA_ "SysSignalName" SG_ 773 IAM_ZONE_100ms_Group13_CRC "IAM_ZONE_100ms_Group13_CRC";
BA_ "CompuMethodName" SG_ 773 IAM_ZONE_100ms_Group13_RC "IAM_ZONE_100ms_Group13_RC";
BA_ "ISignalName" SG_ 773 IAM_ZONE_100ms_Group13_RC "IIAM_ZONE_100ms_Group13_RC";
BA_ "SysSignalName" SG_ 773 IAM_ZONE_100ms_Group13_RC "IAM_ZONE_100ms_Group13_RC";
BA_ "CompuMethodName" SG_ 773 IAM_ZONE_100ms_Group13_Reserved1 "IAM_ZONE_100ms_Group13_Reserved13";
BA_ "GenSigStartValue" SG_ 773 IAM_ZONE_100ms_Group13_Reserved1 3;
BA_ "ISignalName" SG_ 773 IAM_ZONE_100ms_Group13_Reserved1 "IIAM_ZONE_100ms_Group13_Reserved13";
BA_ "SysSignalName" SG_ 773 IAM_ZONE_100ms_Group13_Reserved1 "IAM_ZONE_100ms_Group13_Reserved13";
BA_ "SystemSignalLongSymbol" SG_ 773 IAM_ZONE_100ms_Group13_Reserved1 "IAM_ZONE_100ms_Group13_Reserved13";
BA_ "CompuMethodName" SG_ 773 FixType "FixType";
BA_ "ISignalName" SG_ 773 FixType "IFixType";
BA_ "LongName" SG_ 773 FixType "Gnss Fix Type";
BA_ "SysSignalName" SG_ 773 FixType "FixType";
BA_ "CompuMethodName" SG_ 773 GNSSSeq "GNSSSeq";
BA_ "ISignalName" SG_ 773 GNSSSeq "IGNSSSeq";
BA_ "LongName" SG_ 773 GNSSSeq "Gnss Messages Sequence";
BA_ "SysSignalName" SG_ 773 GNSSSeq "GNSSSeq";
BA_ "CompuMethodName" SG_ 773 GNSSUTCTimeH "GNSSUTCTimeH";
BA_ "ISignalName" SG_ 773 GNSSUTCTimeH "IGNSSUTCTimeH";
BA_ "LongName" SG_ 773 GNSSUTCTimeH "Gnss Utc Time F9H";
BA_ "SysSignalName" SG_ 773 GNSSUTCTimeH "GNSSUTCTimeH";
BA_ "CompuMethodName" SG_ 974 IAM_100ms_Group56_CRC "IAM_100ms_Group56_CRC";
BA_ "ISignalName" SG_ 974 IAM_100ms_Group56_CRC "IIAM_100ms_Group56_CRC";
BA_ "SysSignalName" SG_ 974 IAM_100ms_Group56_CRC "IAM_100ms_Group56_CRC";
BA_ "CompuMethodName" SG_ 974 IAM_100ms_Group56_RC "IAM_100ms_Group56_RC";
BA_ "ISignalName" SG_ 974 IAM_100ms_Group56_RC "IIAM_100ms_Group56_RC";
BA_ "SysSignalName" SG_ 974 IAM_100ms_Group56_RC "IAM_100ms_Group56_RC";
BA_ "CompuMethodName" SG_ 974 IAM_100ms_Group56_Reserved13 "IAM_100ms_Group56_Reserved13";
BA_ "GenSigStartValue" SG_ 974 IAM_100ms_Group56_Reserved13 3;
BA_ "ISignalName" SG_ 974 IAM_100ms_Group56_Reserved13 "IIAM_100ms_Group56_Reserved13";
BA_ "SysSignalName" SG_ 974 IAM_100ms_Group56_Reserved13 "IAM_100ms_Group56_Reserved13";
BA_ "CompuMethodName" SG_ 974 IAM_GNSS_Signal_Status "IAM_GNSS_Signal_Status";
BA_ "ISignalName" SG_ 974 IAM_GNSS_Signal_Status "IIAM_GNSS_Signal_Status";
BA_ "LongName" SG_ 974 IAM_GNSS_Signal_Status "IAM GNSS signal status";
BA_ "SysSignalName" SG_ 974 IAM_GNSS_Signal_Status "IAM_GNSS_Signal_Status";
BA_ "CompuMethodName" SG_ 974 LatitudeRTK "LatitudeRTK";
BA_ "ISignalName" SG_ 974 LatitudeRTK "ILatitudeRTK";
BA_ "LongName" SG_ 974 LatitudeRTK "LatitudeRTK";
BA_ "SysSignalName" SG_ 974 LatitudeRTK "LatitudeRTK";
BA_ "CompuMethodName" SG_ 974 IAM_100ms_Group56_Reserved63 "IAM_100ms_Group56_Reserved63";
BA_ "GenSigStartValue" SG_ 974 IAM_100ms_Group56_Reserved63 255;
BA_ "ISignalName" SG_ 974 IAM_100ms_Group56_Reserved63 "IIAM_100ms_Group56_Reserved63";
BA_ "SysSignalName" SG_ 974 IAM_100ms_Group56_Reserved63 "IAM_100ms_Group56_Reserved63";
BA_ "CompuMethodName" SG_ 348 FCWSnstvtLvl "FCWSnstvtLvl";
BA_ "GenSigStartValue" SG_ 348 FCWSnstvtLvl 2;
BA_ "ISignalName" SG_ 348 FCWSnstvtLvl "IFCWSnstvtLvl";
BA_ "LongName" SG_ 348 FCWSnstvtLvl "Forward_Collision_Warning_Sensitivity_Level";
BA_ "SysSignalName" SG_ 348 FCWSnstvtLvl "FCWSnstvtLvl";
BA_ "CompuMethodName" SG_ 348 AEBDspCmd "AEBDspCmd";
BA_ "GenSigStartValue" SG_ 348 AEBDspCmd 2;
BA_ "ISignalName" SG_ 348 AEBDspCmd "IAEBDspCmd";
BA_ "LongName" SG_ 348 AEBDspCmd "Autonomous_Emergency_Braking_Display_Command";
BA_ "SysSignalName" SG_ 348 AEBDspCmd "AEBDspCmd";
BA_ "CompuMethodName" SG_ 348 AEBMsgReq "AEBMsgReq";
BA_ "ISignalName" SG_ 348 AEBMsgReq "IAEBMsgReq";
BA_ "LongName" SG_ 348 AEBMsgReq "Autonomous_Emergency_Braking_Message_Request";
BA_ "SysSignalName" SG_ 348 AEBMsgReq "AEBMsgReq";
BA_ "CompuMethodName" SG_ 348 FCWDspCmd "FCWDspCmd";
BA_ "GenSigStartValue" SG_ 348 FCWDspCmd 2;
BA_ "ISignalName" SG_ 348 FCWDspCmd "IFCWDspCmd";
BA_ "LongName" SG_ 348 FCWDspCmd "Forward_Collision_Warning_Display_Command";
BA_ "SysSignalName" SG_ 348 FCWDspCmd "FCWDspCmd";
BA_ "CompuMethodName" SG_ 348 FCWSysFltSts "FCWSysFltSts";
BA_ "ISignalName" SG_ 348 FCWSysFltSts "IFCWSysFltSts";
BA_ "LongName" SG_ 348 FCWSysFltSts "Forward_Collision_Warning_System_Fault_Status";
BA_ "SysSignalName" SG_ 348 FCWSysFltSts "FCWSysFltSts";
BA_ "CompuMethodName" SG_ 348 FCWrnngSts "FCWrnngSts";
BA_ "ISignalName" SG_ 348 FCWrnngSts "IFCWrnngSts";
BA_ "LongName" SG_ 348 FCWrnngSts "Forward Collision Warning Status";
BA_ "SysSignalName" SG_ 348 FCWrnngSts "FCWrnngSts";
BA_ "CompuMethodName" SG_ 348 FCTSysFltSts "FCTSysFltSts";
BA_ "ISignalName" SG_ 348 FCTSysFltSts "IFCTSysFltSts";
BA_ "LongName" SG_ 348 FCTSysFltSts "FCTA/B System Fault status";
BA_ "SysSignalName" SG_ 348 FCTSysFltSts "FCTSysFltSts";
BA_ "CompuMethodName" SG_ 348 FCTSwSts "FCTSwSts";
BA_ "GenSigStartValue" SG_ 348 FCTSwSts 1;
BA_ "ISignalName" SG_ 348 FCTSwSts "IFCTSwSts";
BA_ "LongName" SG_ 348 FCTSwSts "FCTA/B  Switch status";
BA_ "SysSignalName" SG_ 348 FCTSwSts "FCTSwSts";
BA_ "CompuMethodName" SG_ 348 LFCTWrnng "LFCTWrnng";
BA_ "ISignalName" SG_ 348 LFCTWrnng "ILFCTWrnng";
BA_ "LongName" SG_ 348 LFCTWrnng "Left_FCTA/B_Warning";
BA_ "SysSignalName" SG_ 348 LFCTWrnng "LFCTWrnng";
BA_ "CompuMethodName" SG_ 348 RFCTWrnng "RFCTWrnng";
BA_ "ISignalName" SG_ 348 RFCTWrnng "IRFCTWrnng";
BA_ "LongName" SG_ 348 RFCTWrnng "Left_FCTA/B_Warning";
BA_ "SysSignalName" SG_ 348 RFCTWrnng "RFCTWrnng";
BA_ "CompuMethodName" SG_ 917 AIPilotIntervQuit "AIPilotIntervQuit";
BA_ "ISignalName" SG_ 917 AIPilotIntervQuit "IAIPilotIntervQuit";
BA_ "LongName" SG_ 917 AIPilotIntervQuit "Ai Pilot Intervene Quit";
BA_ "SysSignalName" SG_ 917 AIPilotIntervQuit "AIPilotIntervQuit";
BA_ "CompuMethodName" SG_ 917 AIParkngDsp "AIParkngDsp";
BA_ "ISignalName" SG_ 917 AIParkngDsp "IAIParkngDsp";
BA_ "LongName" SG_ 917 AIParkngDsp "Ai Parking Display";
BA_ "SysSignalName" SG_ 917 AIParkngDsp "AIParkngDsp";
BA_ "CompuMethodName" SG_ 917 AIParkngSts "AIParkngSts";
BA_ "ISignalName" SG_ 917 AIParkngSts "IAIParkngSts";
BA_ "LongName" SG_ 917 AIParkngSts "Ai Parking Status";
BA_ "SysSignalName" SG_ 917 AIParkngSts "AIParkngSts";
BA_ "CompuMethodName" SG_ 859 SpdAstCndStsCamr "SpdAstCndStsCamr";
BA_ "ISignalName" SG_ 859 SpdAstCndStsCamr "ISpdAstCndStsCamr";
BA_ "LongName" SG_ 859 SpdAstCndStsCamr "Speed Assist Condition Status Camera";
BA_ "SysSignalName" SG_ 859 SpdAstCndStsCamr "SpdAstCndStsCamr";
BA_ "CompuMethodName" SG_ 859 TrgtCndSpdReqCamr "TrgtCndSpdReqCamr";
BA_ "ISignalName" SG_ 859 TrgtCndSpdReqCamr "ITrgtCndSpdReqCamr";
BA_ "LongName" SG_ 859 TrgtCndSpdReqCamr "Target Condition Speed Request Camera";
BA_ "SysSignalName" SG_ 859 TrgtCndSpdReqCamr "TrgtCndSpdReqCamr";
BA_ "CompuMethodName" SG_ 859 DistSinceTrgtCamr "DistSinceTrgtCamr";
BA_ "ISignalName" SG_ 859 DistSinceTrgtCamr "IDistSinceTrgtCamr";
BA_ "LongName" SG_ 859 DistSinceTrgtCamr "Distance Since Target Camera";
BA_ "SysSignalName" SG_ 859 DistSinceTrgtCamr "DistSinceTrgtCamr";
BA_ "CompuMethodName" SG_ 859 SpdLmtMdResp "SpdLmtMdResp";
BA_ "ISignalName" SG_ 859 SpdLmtMdResp "ISpdLmtMdResp";
BA_ "LongName" SG_ 859 SpdLmtMdResp "Speed_Limit_Mode_Response";
BA_ "SysSignalName" SG_ 859 SpdLmtMdResp "SpdLmtMdResp";
BA_ "CompuMethodName" SG_ 859 AutoMainBeamLghtReq "AutoMainBeamLghtReq";
BA_ "ISignalName" SG_ 859 AutoMainBeamLghtReq "IAutoMainBeamLghtReq";
BA_ "LongName" SG_ 859 AutoMainBeamLghtReq "Auto main beam light Request";
BA_ "SysSignalName" SG_ 859 AutoMainBeamLghtReq "AutoMainBeamLghtReq";
BA_ "CompuMethodName" SG_ 895 NarwSpcAstSwSts "NarwSpcAstSwSts";
BA_ "GenSigStartValue" SG_ 895 NarwSpcAstSwSts 2;
BA_ "ISignalName" SG_ 895 NarwSpcAstSwSts "INarwSpcAstSwSts";
BA_ "LongName" SG_ 895 NarwSpcAstSwSts "Narrow Space Assist Switch Status";
BA_ "SysSignalName" SG_ 895 NarwSpcAstSwSts "NarwSpcAstSwSts";
BA_ "CompuMethodName" SG_ 895 IPDStsResp "IPDStsResp";
BA_ "ISignalName" SG_ 895 IPDStsResp "IIPDStsResp";
BA_ "LongName" SG_ 895 IPDStsResp "IPD Status Response";
BA_ "SysSignalName" SG_ 895 IPDStsResp "IPDStsResp";
BA_ "CompuMethodName" SG_ 895 NarwSpcAstBtnSts "NarwSpcAstBtnSts";
BA_ "ISignalName" SG_ 895 NarwSpcAstBtnSts "INarwSpcAstBtnSts";
BA_ "LongName" SG_ 895 NarwSpcAstBtnSts "Narrow Space Assist Button Status";
BA_ "SysSignalName" SG_ 895 NarwSpcAstBtnSts "NarwSpcAstBtnSts";
BA_ "CompuMethodName" SG_ 895 IPD_VehLckCtrlReq "IPD_VehLckCtrlReq";
BA_ "ISignalName" SG_ 895 IPD_VehLckCtrlReq "IIPD_VehLckCtrlReq";
BA_ "LongName" SG_ 895 IPD_VehLckCtrlReq "Vehicle lock request";
BA_ "SysSignalName" SG_ 895 IPD_VehLckCtrlReq "IPD_VehLckCtrlReq";
BA_ "CompuMethodName" SG_ 895 IPDMCUTemp "IPDMCUTemp";
BA_ "GenSigStartValue" SG_ 895 IPDMCUTemp 255;
BA_ "ISignalName" SG_ 895 IPDMCUTemp "IIPDMCUTemp";
BA_ "LongName" SG_ 895 IPDMCUTemp "IPD MCU Temperature";
BA_ "SysSignalName" SG_ 895 IPDMCUTemp "IPDMCUTemp";
BA_ "CompuMethodName" SG_ 895 IPDWtrClntInltReqFlg "IPDWtrClntInltReqFlg";
BA_ "ISignalName" SG_ 895 IPDWtrClntInltReqFlg "IIPDWtrClntInltReqFlg";
BA_ "LongName" SG_ 895 IPDWtrClntInltReqFlg "IPD_water_coolant_inlet_request_flag";
BA_ "SysSignalName" SG_ 895 IPDWtrClntInltReqFlg "IPDWtrClntInltReqFlg";
BA_ "CompuMethodName" SG_ 895 TrfGreenLghtActn "TrfGreenLghtActn";
BA_ "ISignalName" SG_ 895 TrfGreenLghtActn "ITrfGreenLghtActn";
BA_ "LongName" SG_ 895 TrfGreenLghtActn "Traffic Green Light Attention";
BA_ "SysSignalName" SG_ 895 TrfGreenLghtActn "TrfGreenLghtActn";

VAL_ 1319 AIParkngSpcID 0 "AIParkngSpcID_0_NoRequest" 1 "AIParkngSpcID_1_ParktoParkingSpaceID1" 2 "AIParkngSpcID_2_ParktoParkingSpaceID2" 3 "AIParkngSpcID_3_ParktoParkingSpaceID3" 4 "AIParkngSpcID_4_ParktoParkingSpaceID4" 5 "AIParkngSpcID_5_ParktoParkingSpaceID5" 6 "AIParkngSpcID_6_ParktoParkingSpaceID6" 7 "AIParkngSpcID_7_ParktoParkingSpaceID7" 8 "AIParkngSpcID_8_ParktoParkingSpaceID8" 9 "AIParkngSpcID_9_ParktoParkingSpaceID9" 10 "AIParkngSpcID_10_ParktoParkingSpaceID10" 11 "AIParkngSpcID_11_ParktoParkingSpaceID11" 12 "AIParkngSpcID_12_ParktoParkingSpaceID12" 13 "AIParkngSpcID_13_ParktoParkingSpaceID13" 14 "AIParkngSpcID_14_ParktoParkingSpaceID14" 15 "AIParkngSpcID_15_ParktoParkingSpaceID15" 16 "AIParkngSpcID_16_ParktoParkingSpaceID16" 17 "AIParkngSpcID_17_ParktoDIYSpace";
VAL_ 898 FDRSts 0 "FDRSts_0_normal" 1 "FDRSts_1_blindness" 2 "FDRSts_2_misalignment" 3 "FDRSts_3_other_error";
VAL_ 1254 FDR_NM_BSMtoRMS_BKPCANFD 0 "FDR_NM_BSMtoRMS_BKPCANFD_0_False" 1 "FDR_NM_BSMtoRMS_BKPCANFD_1_True";
VAL_ 1254 FDR_NM_PBSMtoRMS_BKPCANFD 0 "FDR_NM_PBSMtoRMS_BKPCANFD_0_False" 1 "FDR_NM_PBSMtoRMS_BKPCANFD_1_True";
VAL_ 1254 FDR_NM_RMStoNOS_BKPCANFD 0 "FDR_NM_RMStoNOS_BKPCANFD_0_False" 1 "FDR_NM_RMStoNOS_BKPCANFD_1_True";
VAL_ 1254 FDR_NM_RSStoNOS_BKPCANFD 0 "FDR_NM_RSStoNOS_BKPCANFD_0_False" 1 "FDR_NM_RSStoNOS_BKPCANFD_1_True";
VAL_ 1254 FDR_NM_RSStoRMS_BKPCANFD 0 "FDR_NM_RSStoRMS_BKPCANFD_0_False" 1 "FDR_NM_RSStoRMS_BKPCANFD_1_True";
VAL_ 1254 FDR_NM_NOStoRMS_BKPCANFD 0 "FDR_NM_NOStoRMS_BKPCANFD_0_False" 1 "FDR_NM_NOStoRMS_BKPCANFD_1_True";
VAL_ 1254 FDR_NM_NOSSta_BKPCANFD 0 "FDR_NM_NOSSta_BKPCANFD_0_False" 1 "FDR_NM_NOSSta_BKPCANFD_1_True";
VAL_ 1254 FDR_NM_RMSSta_BKPCANFD 0 "FDR_NM_RMSSta_BKPCANFD_0_False" 1 "FDR_NM_RMSSta_BKPCANFD_1_True";
VAL_ 1254 FDR_NWI_BKPCANFD 0 "FDR_NWI_BKPCANFD_0_NoWakeNetworkSource";
VAL_ 1254 FDR_NOI_BKPCANFD 0 "FDR_NOI_BKPCANFD_0_NoRequest" 65535 "FDR_NOI_BKPCANFD_65535_AllNetworkOperationActive";
VAL_ 1254 FDR_NKI_BKPCANFD 0 "FDR_NKI_BKPCANFD_0_NoRequest" 1 "FDR_NKI_BKPCANFD_1_PowerModeIsNonOFF";
VAL_ 958 ACCDetObj1Risk 0 "ACCDetObj1Risk_0_NoRisk" 1 "ACCDetObj1Risk_1_RiskExist";
VAL_ 958 ACCDetObj2Risk 0 "ACCDetObj2Risk_0_NoRisk" 1 "ACCDetObj2Risk_1_RiskExist";
VAL_ 958 ACCDetObj3Risk 0 "ACCDetObj3Risk_0_NoRisk" 1 "ACCDetObj3Risk_1_RiskExist";
VAL_ 958 ACCConfmSw 0 "ACCConfmSw_0_unavailable" 1 "ACCConfmSw_1_NoConfirm" 2 "ACCConfmSw_2_Confirm" 3 "ACCConfmSw_3_Reserve";
VAL_ 958 ACCCurveSpdSw 0 "ACCCurveSpdSw_0_unavailable" 1 "ACCCurveSpdSw_1_Off" 2 "ACCCurveSpdSw_2_On" 3 "ACCCurveSpdSw_3_Reserve";
VAL_ 958 ELKWarning 0 "ELKWarning_0_LRoadedge" 1 "ELKWarning_1_RRoadedge" 2 "ELKWarning_2_LOncoming" 3 "ELKWarning_3_ROncoming" 4 "ELKWarning_4_LOvertaking" 5 "ELKWarning_5_ROvertaking" 6 "ELKWarning_6_no_warning" 7 "ELKWarning_7_Reserve2";
VAL_ 958 ACCDetObj2Typ 0 "ACCDetObj2Typ_0_Unknown" 1 "ACCDetObj2Typ_1_Car" 2 "ACCDetObj2Typ_2_Truck" 3 "ACCDetObj2Typ_3_Motorbike" 4 "ACCDetObj2Typ_4_Bicycle" 5 "ACCDetObj2Typ_5_Reserved" 6 "ACCDetObj2Typ_6_Reserved" 7 "ACCDetObj2Typ_7_Reserved";
VAL_ 958 ACCDetObj1Typ 0 "ACCDetObj1Typ_0_Unknown" 1 "ACCDetObj1Typ_1_Car" 2 "ACCDetObj1Typ_2_Truck" 3 "ACCDetObj1Typ_3_Motorbike" 4 "ACCDetObj1Typ_4_Bicycle" 5 "ACCDetObj1Typ_5_Reserved" 6 "ACCDetObj1Typ_6_Reserved" 7 "ACCDetObj1Typ_7_Reserved";
VAL_ 958 ACCDrvrTkovReq 0 "ACCDrvrTkovReq_0_False" 1 "ACCDrvrTkovReq_1_True";
VAL_ 958 ACCDetObj3Typ 0 "ACCDetObj3Typ_0_Unknown" 1 "ACCDetObj3Typ_1_Car" 2 "ACCDetObj3Typ_2_Truck" 3 "ACCDetObj3Typ_3_Motorbike" 4 "ACCDetObj3Typ_4_Bicycle" 5 "ACCDetObj3Typ_5_Reserved" 6 "ACCDetObj3Typ_6_Reserved" 7 "ACCDetObj3Typ_7_Reserved";
VAL_ 956 PilotSysMsg 0 "PilotSysMsg_0_No_display" 1 "PilotSysMsg_1_ACC_Active" 2 "PilotSysMsg_2_ACC_Exit" 3 "PilotSysMsg_3_LCC_Active" 4 "PilotSysMsg_4_LCC_UpgradeFromACC" 5 "PilotSysMsg_5_LCC_DegradationToACC" 6 "PilotSysMsg_6_LCC_Exit" 7 "PilotSysMsg_7_NOA_Active" 8 "PilotSysMsg_8_NOA_Upgrade" 9 "PilotSysMsg_9_NOA_DegradationToLCC" 10 "PilotSysMsg_10_NOA_DegradationToACC" 11 "PilotSysMsg_11_NOA_Exit" 12 "PilotSysMsg_12_Reserved" 13 "PilotSysMsg_13_Reserved" 14 "PilotSysMsg_14_Reserved" 15 "PilotSysMsg_15_Reserved";
VAL_ 956 TLRMsgReq 0 "TLRMsgReq_0_NoDisplay" 1 "TLRMsgReq_1_Countdown" 2 "TLRMsgReq_2_Reserved" 3 "TLRMsgReq_3_Reserved";
VAL_ 956 Lane0_MarkerColor 0 "Lane0_MarkerColor_00_no_line" 1 "Lane0_MarkerColor_01_white" 2 "Lane0_MarkerColor_02_red" 3 "Lane0_MarkerColor_03_yellow" 4 "Lane0_MarkerColor_04_other";
VAL_ 956 Lane0_location 0 "Lane0_location_0_Left" 1 "Lane0_location_1_Right" 2 "Lane0_location_2_NextLeft" 3 "Lane0_location_3_NextRight";
VAL_ 956 TLRSysSts 0 "TLRSysSts_0_Off" 1 "TLRSysSts_1_StandBy" 2 "TLRSysSts_2_Active" 3 "TLRSysSts_3_Error";
VAL_ 956 Lane1_location 0 "Lane1_location_0_Left" 1 "Lane1_location_1_Right" 2 "Lane1_location_2_NextLeft" 3 "Lane1_location_3_NextRight";
VAL_ 956 Lane0_MarkerType 0 "Lane0_MarkerType_00_no_line" 1 "Lane0_MarkerType_01_solid" 2 "Lane0_MarkerType_02_dashed" 3 "Lane0_MarkerType_03_curbstone" 4 "Lane0_MarkerType_04_grass" 5 "Lane0_MarkerType_05_Bot_Dott" 6 "Lane0_MarkerType_06_other";
VAL_ 956 Lane1_MarkerType 0 "Lane1_MarkerType_00_no_line" 1 "Lane1_MarkerType_01_solid" 2 "Lane1_MarkerType_02_dashed" 3 "Lane1_MarkerType_03_curbstone" 4 "Lane1_MarkerType_04_grass" 5 "Lane1_MarkerType_05_Bot_Dott" 6 "Lane1_MarkerType_06_other";
VAL_ 956 Lane1_MarkerColor 0 "Lane1_MarkerColor_00_no_line" 1 "Lane1_MarkerColor_01_white" 2 "Lane1_MarkerColor_02_red" 3 "Lane1_MarkerColor_03_yellow" 4 "Lane1_MarkerColor_04_other";
VAL_ 956 Lane2_MarkerColor 0 "Lane2_MarkerColor_00_no_line" 1 "Lane2_MarkerColor_01_white" 2 "Lane2_MarkerColor_02_red" 3 "Lane2_MarkerColor_03_yellow" 4 "Lane2_MarkerColor_04_other";
VAL_ 956 Lane2_location 0 "Lane2_location_0_Left" 1 "Lane2_location_1_Right" 2 "Lane2_location_2_NextLeft" 3 "Lane2_location_3_NextRight";
VAL_ 956 Lane3_location 0 "Lane3_location_0_Left" 1 "Lane3_location_1_Right" 2 "Lane3_location_2_NextLeft" 3 "Lane3_location_3_NextRight";
VAL_ 956 Lane2_MarkerType 0 "Lane2_MarkerType_00_no_line" 1 "Lane2_MarkerType_01_solid" 2 "Lane2_MarkerType_02_dashed" 3 "Lane2_MarkerType_03_curbstone" 4 "Lane2_MarkerType_04_grass" 5 "Lane2_MarkerType_05_Bot_Dott" 6 "Lane2_MarkerType_06_other";
VAL_ 956 Lane3_MarkerType 0 "Lane3_MarkerType_00_no_line" 1 "Lane3_MarkerType_01_solid" 2 "Lane3_MarkerType_02_dashed" 3 "Lane3_MarkerType_03_curbstone" 4 "Lane3_MarkerType_04_grass" 5 "Lane3_MarkerType_05_Bot_Dott" 6 "Lane3_MarkerType_06_other";
VAL_ 956 Lane3_MarkerColor 0 "Lane3_MarkerColor_00_no_line" 1 "Lane3_MarkerColor_01_white" 2 "Lane3_MarkerColor_02_red" 3 "Lane3_MarkerColor_03_yellow" 4 "Lane3_MarkerColor_04_other";
VAL_ 956 TLRWarning 0 "TLRWarning_0_NoRequest" 1 "TLRWarning_1_GreenLightStartAlert_lvl1" 2 "TLRWarning_2_GreenLightStartAlert_lvl2" 3 "TLRWarning_3_RedLightRunAlert_lvl1" 4 "TLRWarning_4_RedLightRunAlert_lvl2" 5 "TLRWarning_5_Reserved" 6 "TLRWarning_6_Reserved";
VAL_ 956 TLRMdSwDspCmd 0 "TLRMdSwDspCmd_0_unavailable" 1 "TLRMdSwDspCmd_1_TLR_on" 2 "TLRMdSwDspCmd_2_TLR_off" 3 "TLRMdSwDspCmd_3_TLR_alert_off" 4 "TLRMdSwDspCmd_4_TLR_alert_on" 5 "TLRMdSwDspCmd_5_Reserved" 6 "TLRMdSwDspCmd_6_Reserved";
VAL_ 956 CCSpdVcCmdCnfm 0 "CCSpdVcCmdCnfm_0_NoResponse" 1 "CCSpdVcCmdCnfm_1_SpeedIsConfirmed" 2 "CCSpdVcCmdCnfm_2_DistanceIsConfirmed" 3 "CCSpdVcCmdCnfm_3_NotInTheRange" 4 "CCSpdVcCmdCnfm_4_AlreadyInMaximunRange" 5 "CCSpdVcCmdCnfm_5_AlreadyInMinimumRange" 6 "CCSpdVcCmdCnfm_6_ACCisActived" 7 "CCSpdVcCmdCnfm_7_ACCisDeactived";
VAL_ 307 ACCDrvrSelTrgtSpd 0 "ACCDrvrSelTrgtSpd_0_no_speed_set";
VAL_ 307 ACCGoNotfr 0 "ACCGoNotfr_0_False" 1 "ACCGoNotfr_1_True";
VAL_ 307 ACCDetObjDistLvl 0 "ACCDetObjDistLvl_0_NoGapSet" 1 "ACCDetObjDistLvl_1_DistanceLevel1" 2 "ACCDetObjDistLvl_2_DistanceLevel2" 3 "ACCDetObjDistLvl_3_DistanceLevel3" 4 "ACCDetObjDistLvl_4_DistanceLevel4" 5 "ACCDetObjDistLvl_5_DistanceLevel5" 6 "ACCDetObjDistLvl_6_reserved" 7 "ACCDetObjDistLvl_7_reserved";
VAL_ 307 ELKSysSts_IPD 0 "ELKSysSts_IPD_0_off" 1 "ELKSysSts_IPD_1_Passive" 2 "ELKSysSts_IPD_2_Stand_by" 3 "ELKSysSts_IPD_3_Active_Roadedge" 4 "ELKSysSts_IPD_4_Active_Oncoming" 5 "ELKSysSts_IPD_5_Active_Overtaking" 6 "ELKSysSts_IPD_6_Overrride" 7 "ELKSysSts_IPD_7_Error" 8 "ELKSysSts_IPD_8_Reserve";
VAL_ 307 ACCTotWhlToqReqSts 0 "ACCTotWhlToqReqSts_0_NoRequest" 1 "ACCTotWhlToqReqSts_1_TorqueRequest" 2 "ACCTotWhlToqReqSts_2_Reserved";
VAL_ 307 ACCTJAMdSwDspCmd 0 "ACCTJAMdSwDspCmd_0_unavailable" 1 "ACCTJAMdSwDspCmd_1_ACC" 2 "ACCTJAMdSwDspCmd_2_TJA" 3 "ACCTJAMdSwDspCmd_3_SHWA" 4 "ACCTJAMdSwDspCmd_4_Off" 5 "ACCTJAMdSwDspCmd_5_Reserved" 6 "ACCTJAMdSwDspCmd_6_Reserved" 7 "ACCTJAMdSwDspCmd_7_Reserved";
VAL_ 307 ACCSeldTrgtDistLvl 0 "ACCSeldTrgtDistLvl_0_NoGapSet" 1 "ACCSeldTrgtDistLvl_1_DistanceLevel1" 2 "ACCSeldTrgtDistLvl_2_DistanceLevel2" 3 "ACCSeldTrgtDistLvl_3_DistanceLevel3" 4 "ACCSeldTrgtDistLvl_4_DistanceLevel4" 5 "ACCSeldTrgtDistLvl_5_DistanceLevel5";
VAL_ 307 HandOffStrgWhlDetnSta 0 "HandOffStrgWhlDetnSta_0_Hands_On" 1 "HandOffStrgWhlDetnSta_1_Hands_Off_level_1" 2 "HandOffStrgWhlDetnSta_2_Hands_Off_level_2" 3 "HandOffStrgWhlDetnSta_3_Hands_Off_level_3";
VAL_ 307 ILCActvnDircnDspCmd 0 "ILCActvnDircnDspCmd_0_Unavailable" 1 "ILCActvnDircnDspCmd_1_IlcNotActive" 2 "ILCActvnDircnDspCmd_2_IlcActiveLeft" 3 "ILCActvnDircnDspCmd_3_IlcActiveRight";
VAL_ 307 ILCSwDspCmd 0 "ILCSwDspCmd_0_unavailable" 1 "ILCSwDspCmd_1_off" 2 "ILCSwDspCmd_2_on" 3 "ILCSwDspCmd_3_reserved";
VAL_ 307 ILCSysSts 0 "ILCSysSts_0_Off" 1 "ILCSysSts_1_Failure" 2 "ILCSysSts_2_Standby" 3 "ILCSysSts_3_Passive" 4 "ILCSysSts_4_ActiveRequest" 5 "ILCSysSts_5_ActiveControl" 6 "ILCSysSts_6_Reserved" 7 "ILCSysSts_7_Reserved";
VAL_ 307 ILCActvnVelDspCmd 0 "ILCActvnVelDspCmd_0_Unavailable" 1 "ILCActvnVelDspCmd_1_IlcNotActive" 2 "ILCActvnVelDspCmd_2_IlcAcceleration" 3 "ILCActvnVelDspCmd_3_IlcDeceleration";
VAL_ 307 HandOffStrgWhlDetnStaV 0 "HandOffStrgWhlDetnStaV_0_Valid" 1 "HandOffStrgWhlDetnStaV_1_Invalid";
VAL_ 307 LDWLKAAudReq 0 "LDWLKAAudReq_0_no_request" 1 "LDWLKAAudReq_1_level_1" 2 "LDWLKAAudReq_2_level_2" 3 "LDWLKAAudReq_3_level_3";
VAL_ 307 LDWAdoWrnngDspCmd 0 "LDWAdoWrnngDspCmd_0_Unavailable" 1 "LDWAdoWrnngDspCmd_1_off" 2 "LDWAdoWrnngDspCmd_2_on" 3 "LDWAdoWrnngDspCmd_3_reserved";
VAL_ 307 LDWLKADspCmd 0 "LDWLKADspCmd_0_Unavailable" 1 "LDWLKADspCmd_1_off" 2 "LDWLKADspCmd_2_LDW" 3 "LDWLKADspCmd_3_LDP0" 4 "LDWLKADspCmd_4_LKA" 5 "LDWLKADspCmd_5_LDW_ELK" 6 "LDWLKADspCmd_6_LDP_ELK";
VAL_ 307 LKADrvrTkovReq 0 "LKADrvrTkovReq_0_False" 1 "LKADrvrTkovReq_1_True";
VAL_ 307 LDWSnstvtLvl 0 "LDWSnstvtLvl_0_unavailable" 1 "LDWSnstvtLvl_1_Low" 2 "LDWSnstvtLvl_2_Standard" 3 "LDWSnstvtLvl_3_High";
VAL_ 307 LDWLKAHptWrnngDspCmd 0 "LDWLKAHptWrnngDspCmd_0_unavailable" 1 "LDWLKAHptWrnngDspCmd_1_off" 2 "LDWLKAHptWrnngDspCmd_2_on";
VAL_ 307 EyeOffRoadDetnSta 0 "EyeOffRoadDetnSta_0_Eye_On" 1 "EyeOffRoadDetnSta_1_Eye_Off_level_1" 2 "EyeOffRoadDetnSta_2_Eye_Off_level_2" 3 "EyeOffRoadDetnSta_3_Eye_Off_level_3";
VAL_ 307 EyeOffRoadDetnStaV 0 "EyeOffRoadDetnStaV_0_Valid" 1 "EyeOffRoadDetnStaV_1_Invalid";
VAL_ 307 ACCMsgReq 0 "ACCMsgReq_0_NoDisplay" 1 "ACCMsgReq_1_Speed_is_lower_than_boundary" 2 "ACCMsgReq_2_active_failed_because_of_Handoff_Prohibition" 3 "ACCMsgReq_3_go_notifier_between_10s_and_50s" 4 "ACCMsgReq_4_go_notifier_between_50s_and_300s" 5 "ACCMsgReq_5_system_fault" 6 "ACCMsgReq_6_Reserved" 7 "ACCMsgReq_7_TCS_or_VSE_off" 8 "ACCMsgReq_8_Brake_pedal_is_not_pressed_when_vehicle_is_standstill" 9 "ACCMsgReq_9_Brake_pedal_is_not_released_during_driving" 10 "ACCMsgReq_10_Speed_is_out_of_boundary" 11 "ACCMsgReq_11_EPB_applied" 12 "ACCMsgReq_12_shift_is_not_in_D" 13 "ACCMsgReq_13_door_or_bonnet_is_open" 14 "ACCMsgReq_14_Driver_Seatbelt_released" 15 "ACCMsgReq_15_Driver_mode_not_support" 16 "ACCMsgReq_16_Reserve" 17 "ACCMsgReq_17_Reserve" 18 "ACCMsgReq_18_Reserve" 19 "ACCMsgReq_19_Reserve" 20 "ACCMsgReq_20_Reserve" 21 "ACCMsgReq_21_Reserve" 22 "ACCMsgReq_22_Reserve" 23 "ACCMsgReq_23_Reserve" 24 "ACCMsgReq_24_Reserve" 25 "ACCMsgReq_25_Reserve" 26 "ACCMsgReq_26_Reserve" 27 "ACCMsgReq_27_Reserve" 28 "ACCMsgReq_28_Reserve" 29 "ACCMsgReq_29_Reserve" 30 "ACCMsgReq_30_Reserve" 31 "ACCMsgReq_31_Reserve";
VAL_ 336 RmtParkngAstParkngOutDircnSeln 0 "RmtParkngAstParkngOutDircnSeln_0_none" 1 "RmtParkngAstParkngOutDircnSeln_1_FrontLeftCross" 2 "RmtParkngAstParkngOutDircnSeln_2_FrontLeftParallel" 3 "RmtParkngAstParkngOutDircnSeln_3_FrontOut" 4 "RmtParkngAstParkngOutDircnSeln_4_FrontRightCross" 5 "RmtParkngAstParkngOutDircnSeln_5_FrontRightParallel" 6 "RmtParkngAstParkngOutDircnSeln_6_BackOut" 7 "RmtParkngAstParkngOutDircnSeln_7_BackLeftCross" 8 "RmtParkngAstParkngOutDircnSeln_8_BackRightCross";
VAL_ 336 RmtParkngAstBtnSts 0 "RmtParkngAstBtnSts_0_NotPressed" 1 "RmtParkngAstBtnSts_1_Pressed";
VAL_ 336 VehFwdSwReq 0 "VehFwdSwReq_0_NoReq" 1 "VehFwdSwReq_1_Slow" 2 "VehFwdSwReq_2_Normal" 3 "VehFwdSwReq_3_Fast";
VAL_ 336 VehBkwdSwReq 0 "VehBkwdSwReq_0_NoReq" 1 "VehBkwdSwReq_1_Slow" 2 "VehBkwdSwReq_2_Normal" 3 "VehBkwdSwReq_3_Fast";
VAL_ 336 RmtParkngAstDvcSts 0 "RmtParkngAstDvcSts_0_RD_Inactive" 1 "RmtParkngAstDvcSts_1_RD_Ready" 2 "RmtParkngAstDvcSts_2_RD_Active" 3 "RmtParkngAstDvcSts_3_RD_Fault" 4 "RmtParkngAstDvcSts_4_Reserved";
VAL_ 336 RmtDrvrTrgtEPSStrgWhlAng 65535 "RmtDrvrTrgtEPSStrgWhlAng_65535_error_mark";
VAL_ 336 VehRoadWhlRReq 0 "VehRoadWhlRReq_0_NoReq" 1 "VehRoadWhlRReq_1_Slow" 2 "VehRoadWhlRReq_2_Normal" 3 "VehRoadWhlRReq_3_Fast";
VAL_ 336 VehRoadWhlLReq 0 "VehRoadWhlLReq_0_NoReq" 1 "VehRoadWhlLReq_1_Slow" 2 "VehRoadWhlLReq_2_Normal" 3 "VehRoadWhlLReq_3_Fast";
VAL_ 336 RmtParkngAstAbotBtnSts 0 "RmtParkngAstAbotBtnSts_0_NoPress" 1 "RmtParkngAstAbotBtnSts_1_Press";
VAL_ 336 RmtParkngAstDvcFlrRsn 0 "RmtParkngAstDvcFlrRsn_0_RD_NoFailure" 1 "RmtParkngAstDvcFlrRsn_1_RD_Offline" 2 "RmtParkngAstDvcFlrRsn_2_RD_OutOfRange" 3 "RmtParkngAstDvcFlrRsn_3_RD_LowBatt" 4 "RmtParkngAstDvcFlrRsn_4_APPAbnormal";
VAL_ 336 VehRoadWhlRReqV 0 "VehRoadWhlRReqV_0_Valid" 1 "VehRoadWhlRReqV_1_Invalid";
VAL_ 336 VehRoadWhlLReqV 0 "VehRoadWhlLReqV_0_Valid" 1 "VehRoadWhlLReqV_1_Invalid";
VAL_ 336 VehFwdSwReqV 0 "VehFwdSwReqV_0_Valid" 1 "VehFwdSwReqV_1_Invalid";
VAL_ 336 VehBkwdSwReqV 0 "VehBkwdSwReqV_0_Valid" 1 "VehBkwdSwReqV_1_Invalid";
VAL_ 89 IAMReststs 0 "IAMReststs_0_reserved" 1 "IAMReststs_1_Restarting";
VAL_ 1000 SmtKeyAuthnSubModRunSts 0 "SmtKeyAuthnSubModRunSts_0_Initialization" 1 "SmtKeyAuthnSubModRunSts_1_Running" 2 "SmtKeyAuthnSubModRunSts_2_ResponseSucess" 3 "SmtKeyAuthnSubModRunSts_3_Failure_Attack" 4 "SmtKeyAuthnSubModRunSts_4_Failure_NoChallenge" 5 "SmtKeyAuthnSubModRunSts_5_Failure_NoCipher" 6 "SmtKeyAuthnSubModRunSts_6_Reserved" 7 "SmtKeyAuthnSubModRunSts_7_Reserved";
VAL_ 1358 KeyDeleResp 0 "KeyDeleResp_0_default" 1 "KeyDeleResp_1_success" 2 "KeyDeleResp_2_IAM_No_key" 3 "KeyDeleResp_3_IAMsystemfault" 4 "KeyDeleResp_4_TSPfault" 5 "KeyDeleResp_5_timeout" 6 "KeyDeleResp_6_TSP_No_key" 7 "KeyDeleResp_7_VehicleMinusCloud_Link_Failure" 15 "KeyDeleResp_15_reserve";
VAL_ 1358 AIParkngReq 0 "AIParkngReq_0_No_Request" 1 "AIParkngReq_1_Start_Parking_in" 2 "AIParkngReq_2_Start_Parking_out" 3 "AIParkngReq_3_Pause" 4 "AIParkngReq_4_Continue" 5 "AIParkngReq_5_Cancel" 7 "AIParkngReq_7_Left_Parking_out" 8 "AIParkngReq_8_Right_Parking_out" 9 "AIParkngReq_9_Fast_Parking" 10 "AIParkngReq_10_Line_out_System_Start" 11 "AIParkngReq_11_Line_back_System_Start" 12 "AIParkngReq_12_Call_to_Position_X" 13 "AIParkngReq_13_StartParkingScanningManualDriving" 14 "AIParkngReq_14_Remote_turn_left" 15 "AIParkngReq_15_Remote_turn_right" 16 "AIParkngReq_16_RememberBuildMap" 17 "AIParkngReq_17_Remember_Park_In" 18 "AIParkngReq_18_Remember_Summon" 19 "AIParkngReq_19_Start_Remember_Parking" 20 "AIParkngReq_20_Keep_Going_Forword" 21 "AIParkngReq_21_Keep_Going_Back" 22 "AIParkngReq_22_Start_AVP_in" 23 "AIParkngReq_23_Start_AVP_out" 24 "AIParkngReq_24_Back_Left_Parking_out" 25 "AIParkngReq_25_Back_Right_Parking_out" 26 "AIParkngReq_26_Start_NRCD" 27 "AIParkngReq_27_Front_Left_Cross_Park_Out" 28 "AIParkngReq_28_Front_Left_Parallel_Park_Out" 29 "AIParkngReq_29_Front_Out_Park_Out" 30 "AIParkngReq_30_Front_Right_Cross_Park_Out" 31 "AIParkngReq_31_Front_Right_Parallel_Park_Out" 32 "AIParkngReq_32_Back_Out_Park_Out" 33 "AIParkngReq_33_Back_Left_Cross_Park_Out" 34 "AIParkngReq_34_Back_Right_Cross_Park_Out" 35 "AIParkngReq_35_Start_Confirm" 36 "AIParkngReq_36_Start_RPI" 37 "AIParkngReq_37_Start_RPI_Super" 38 "AIParkngReq_38_Confirm" 39 "AIParkngReq_39_Quit" 40 "AIParkngReq_40_Start_RADS" 41 "AIParkngReq_41_Start_NPA" 42 "AIParkngReq_42_Recover_Remember_Park_in_XEquals1" 43 "AIParkngReq_43_Park_in_nearby_slot_XEquals1" 128 "AIParkngReq_128_Wakeup_network_XEquals8";
VAL_ 773 FixType 0 "FixType_0_nofix" 1 "FixType_1_2dfix" 2 "FixType_2_3dfix";
VAL_ 974 IAM_GNSS_Signal_Status 0 "IAM_GNSS_Signal_Status_0_Normal" 1 "IAM_GNSS_Signal_Status_1_Failure";
VAL_ 348 FCWSnstvtLvl 0 "FCWSnstvtLvl_0_Unavailable" 1 "FCWSnstvtLvl_1_level1_low" 2 "FCWSnstvtLvl_2_level2_middle" 3 "FCWSnstvtLvl_3_level3_high";
VAL_ 348 AEBDspCmd 0 "AEBDspCmd_0_unavailable" 1 "AEBDspCmd_1_off" 2 "AEBDspCmd_2_on";
VAL_ 348 AEBMsgReq 0 "AEBMsgReq_0_NoDisplay" 1 "AEBMsgReq_1_UnableToActiveAeb" 2 "AEBMsgReq_2_Active" 3 "AEBMsgReq_3_AebIsInErrorMode" 4 "AEBMsgReq_4_AebIsSwitchedOn" 5 "AEBMsgReq_5_AebIsSwitchedOff" 6 "AEBMsgReq_6_RadarError" 7 "AEBMsgReq_7_reserved";
VAL_ 348 FCWDspCmd 0 "FCWDspCmd_0_unavailable" 1 "FCWDspCmd_1_off" 2 "FCWDspCmd_2_on";
VAL_ 348 FCWSysFltSts 0 "FCWSysFltSts_0_NoError" 1 "FCWSysFltSts_1_PerformanceDegradation" 2 "FCWSysFltSts_2_SystemTemporaryUnvailable" 3 "FCWSysFltSts_3_ServiceRequired";
VAL_ 348 FCWrnngSts 0 "FCWrnngSts_0_NoRequest" 1 "FCWrnngSts_1_level1_low" 2 "FCWrnngSts_2_level2_middle" 3 "FCWrnngSts_3_level3_high";
VAL_ 348 FCTSysFltSts 0 "FCTSysFltSts_0_No_Error" 1 "FCTSysFltSts_1_System_Temporary_Unvailable" 2 "FCTSysFltSts_2_Service_Required" 3 "FCTSysFltSts_3_Service_Required";
VAL_ 348 FCTSwSts 0 "FCTSwSts_0_unavaliable" 1 "FCTSwSts_1_driver_switch_FCTA_off" 2 "FCTSwSts_2_driver_switch_FCTA_on" 3 "FCTSwSts_3_driver_switch_FCTB__FCTA__on" 4 "FCTSwSts_4_Reserved" 5 "FCTSwSts_FunctionStatus_5_Reserved" 6 "FCTSwSts_FunctionStatus_6_Reserved" 7 "FCTSwSts_FunctionStatus_7_Reserved";
VAL_ 348 LFCTWrnng 0 "LFCTAWrnng_0_no_warning" 1 "LFCTAWrnng_1_warning_level_1" 2 "LFCTAWrnng_2_warning_level_2" 3 "LFCTBActive_3_Active" 4 "LFCTAWrnng_4_reserved" 5 "LFCTAWrnng_5_reserved" 6 "LFCTAWrnng_6_reserved";
VAL_ 348 RFCTWrnng 0 "RFCTAWrnng_0_no_warning" 1 "RFCTAWrnng_1_warning_level_1" 2 "RFCTAWrnng_2_warning_level_2" 3 "RFCTBActive_3_Active" 4 "RFCTAWrnng_4_reserved" 5 "RFCTAWrnng_5_reserved" 6 "RFCTAWrnng_6_reserved";
VAL_ 917 AIPilotIntervQuit 0 "AIPiloTIntervQuit_0_No_display" 1 "AIPiloTIntervQuit_1_SystemFailed_AIPilotIsQuit" 2 "AIPiloTIntervQuit_2_TrunkOpen_TakeOverPlease" 3 "AIPiloTIntervQuit_3_SeatbeltReleased_AIPilotIsQuit" 4 "AIPiloTIntervQuit_4_EPBSwitchPressed_AIPilotIsQuit" 5 "AIPiloTIntervQuit_5_DoorsOpen_AIPilotIsQuit" 6 "AIPiloTIntervQuit_6_HoodOpen_AIPilotIsQuit" 7 "AIPiloTIntervQuit_7_please_parking_the_vehicle" 8 "AIPiloTIntervQuit_8_VehicleSpeedIsTooFast_AIPilotIsQuit" 9 "AIPiloTIntervQuit_9_ESP_active_AIPilotIsQuit" 10 "AIPiloTIntervQuit_10_ParkingTimeOver15min_AIPilotIsQuit" 11 "AIPiloTIntervQuit_11_AIPilotIsQuit" 12 "AIPiloTIntervQuit_12_Camera_is_blocked_ACCIsQuit" 13 "AIPiloTIntervQuit_13_The_end_of_NOA" 14 "AIPiloTIntervQuit_14_NOA_is_not_available_at_the_front_XXM" 15 "AIPiloTIntervQuit_15_NOA_is_finished_at_the_front_XXM" 16 "AIPiloTIntervQuit_16_Waiting_for_timeout__AIPilotIsQuit" 17 "AIPiloTIntervQuit_17_Too_long_time_to_step_on_the_accelerator_TakeOverPlease" 18 "AIPiloTIntervQuit_18_ESP_is_closed_TakeOverPlease" 19 "AIPiloTIntervQuit_19_Reserved_1" 20 "AIPiloTIntervQuit_20_Reserved_2" 21 "AIPiloTIntervQuit_21_Reserved_3" 22 "AIPiloTIntervQuit_22_Reserved_4" 23 "AIPiloTIntervQuit_23_Reserved_5" 24 "AIPiloTIntervQuit_24_Reserved_6" 25 "AIPiloTIntervQuit_25_Reserved_7" 26 "AIPiloTIntervQuit_26_Reserved_8" 27 "AIPiloTIntervQuit_27_Reserved_9" 28 "AIPiloTIntervQuit_28_Reserved_10" 29 "AIPiloTIntervQuit_29_Reserved_11" 30 "AIPiloTIntervQuit_30_Reserved_12" 31 "AIPiloTIntervQuit_31_Reserved_13" 32 "AIPiloTIntervQuit_32_Reserved_14" 33 "AIPiloTIntervQuit_33_Reserved_15" 34 "AIPiloTIntervQuit_34_Reserved_16" 35 "AIPiloTIntervQuit_35_Reserved_17" 36 "AIPiloTIntervQuit_36_Reserved_18" 37 "AIPiloTIntervQuit_37_Reserved_19" 38 "AIPiloTIntervQuit_38_Reserved_20" 39 "AIPiloTIntervQuit_39_Reserved_21" 40 "AIPiloTIntervQuit_40_Reserved_22" 41 "AIPiloTIntervQuit_41_Reserved_23" 42 "AIPiloTIntervQuit_42_Reserved_24" 43 "AIPiloTIntervQuit_43_Reserved_25" 44 "AIPiloTIntervQuit_44_Reserved_26" 45 "AIPiloTIntervQuit_45_Reserved_27" 46 "AIPiloTIntervQuit_46_Reserved_28" 47 "AIPiloTIntervQuit_47_Reserved_29" 48 "AIPiloTIntervQuit_48_Reserved_30" 49 "AIPiloTIntervQuit_49_Reserved_31" 50 "AIPiloTIntervQuit_50_Reserved_32" 51 "AIPiloTIntervQuit_51_Reserved_33" 52 "AIPiloTIntervQuit_52_Reserved_34" 53 "AIPiloTIntervQuit_53_Reserved_35" 54 "AIPiloTIntervQuit_54_Reserved_36" 55 "AIPiloTIntervQuit_55_Reserved_37" 56 "AIPiloTIntervQuit_56_Reserved_38" 57 "AIPiloTIntervQuit_57_Reserved_39" 58 "AIPiloTIntervQuit_58_Reserved_40" 59 "AIPiloTIntervQuit_59_Reserved_41" 60 "AIPiloTIntervQuit_60_Reserved_42" 61 "AIPiloTIntervQuit_61_Reserved_43" 62 "AIPiloTIntervQuit_62_Reserved_44" 63 "AIPiloTIntervQuit_63_Reserved_45";
VAL_ 917 AIParkngDsp 0 "AIParkngDsp_0_NoDisplay" 1 "AIParkngDsp_1_BrakePedalStepDownArtificiallyAutoParkingHasExitedTakeOverPlease" 2 "AIParkngDsp_2_SelfTestTimeoutAutoParkingHasExitedTakeOverPlease" 3 "AIParkngDsp_3_FlameoutTimeoutAutoParkingHasExitedTakeOverPlease" 4 "AIParkngDsp_4_BluetoothdisconnectedAutoParkingHasExitedTakeOverPlease" 5 "AIParkngDsp_5_NotUseOnPublicRoadMapBuildingfailed" 6 "AIParkngDsp_6_ElectricLockCompleted" 7 "AIParkngDsp_7_FailedLockCarAutoParkingHasExitedTakeOverPlease" 8 "AIParkngDsp_8_VehicleSelfTestFailureAutoParkingHasExitedTakeOverPlease" 9 "AIParkngDsp_9_FlameoutFailedAutoParkingHasExitedTakeOverPlease" 10 "AIParkngDsp_10_AutoParkingHasStopped" 11 "AIParkngDsp_11_FailedToCancelAutoParkingTryAgainOrTakeOver" 12 "AIParkngDsp_12_SystemFailedAutoParkingCancel" 13 "AIParkngDsp_13_NotUseOnPublicRoadTakeOverPlease" 14 "AIParkngDsp_14_WirelessCharginglocationIsSelectedpleaseslowdownandstop" 15 "AIParkngDsp_15_SystemTimeOutAutoParkingCancel" 16 "AIParkngDsp_16_AutoParkingIsSuspendedPressButtonToContiuneOrSelectAPPToContinueParkingIn" 17 "AIParkngDsp_17_SteeringWheelInterveneAutoParkingCancel" 18 "AIParkngDsp_18_PressContinueToPointAtWLC" 19 "AIParkngDsp_19_SheftLevelInterveneAutoParkingCancel" 20 "AIParkngDsp_20_CanntPointAtWLC" 21 "AIParkngDsp_21_ParkingDistanceIsBeyondLimitationAutoParkingCancel" 22 "AIParkngDsp_22_NumberOfAdjustmentsExceedsLimitationAutoParkingCancel" 23 "AIParkngDsp_23_AutoParkingRespondsToAccelerationDecelerateTobelow15kph" 24 "AIParkngDsp_24_VehicleSpeedHighAutoParkingCancel" 25 "AIParkngDsp_25_DoorsOrHoodOrTrunklidIsOpenMapBuildingfailed" 26 "AIParkngDsp_26_TrunkIsOpenAutoParkingCancel" 27 "AIParkngDsp_27_HoodIsOpenAutoParkingCancel" 28 "AIParkngDsp_28_AParkingSpaceIsFoundSelectOneOrStopPlease" 29 "AIParkngDsp_29_PressToStartParkingOrGetOffInPGearToSelectAPPOrKeyToContinueParkingIn" 30 "AIParkngDsp_30_Pleasebackupafterarrivingyourspace" 31 "AIParkngDsp_31_SearchForParkingSpaceSurroundingEnvironmentCarefully" 33 "AIParkngDsp_33_AutoParkingFinish" 34 "AIParkngDsp_34_AutoParkingCancelTakeOverPlease" 35 "AIParkngDsp_35_VehicleSpeedExceedDrivingRangeTakeOverPlease" 36 "AIParkngDsp_36_IntelligentParkingSurroundingEnvironmentCarefully" 37 "AIParkngDsp_37_ReleaseBrakePedalAndAutoParkingContinue" 38 "AIParkngDsp_38_ChargerIschargingAutoParkingCancel" 39 "AIParkngDsp_39_ExteriorMirrorIsAbnormalTakeOverPlease" 40 "AIParkngDsp_40_CameraIsBlockedTakeOverPlease" 41 "AIParkngDsp_41_EnvironmentIsAbnormalTakeOverPlease" 42 "AIParkngDsp_42_EncounteringObstaclesParkingIsSuspended" 43 "AIParkngDsp_43_ReversingtoolongMapBuildingfailed" 44 "AIParkngDsp_44_DoorIsOpen" 45 "AIParkngDsp_45_PowerButtonIsPressedAutoParkingCancel" 46 "AIParkngDsp_46_ObstaclesInParkingSpaceChangeOnePlease" 47 "AIParkngDsp_47_VehicleSpeedHigh" 48 "AIParkngDsp_48_SteeringWheelInterveneAutoParkingPaused" 49 "AIParkngDsp_49_PressToStartParkingOrGetOffToSelectAPPOrKeyToContinueParkingIn" 50 "AIParkngDsp_50_ObstaclesInTheTargetParkingSpaceRemove" 51 "AIParkngDsp_51_NotinspaceMapBuildingfailed" 52 "AIParkngDsp_52_PleaseHangPGear" 53 "AIParkngDsp_53_WaitMapFileUpgradeCompleted" 54 "AIParkngDsp_54_WaitAppUpgradeCompleted" 55 "AIParkngDsp_55_VehicleIsStart" 56 "AIParkngDsp_56_AirbagIsExpandedAutoParkingUnavailable" 57 "AIParkngDsp_57_TirePresureInormalAutoParkingUnavailable" 58 "AIParkngDsp_58_Aboutoparkinthespace" 59 "AIParkngDsp_59_MemoryparkingBeAwareOfSurroundings" 60 "AIParkngDsp_60_LongPressAndSearching" 61 "AIParkngDsp_61_AbnormalEnvironmentFunctionExit" 62 "AIParkngDsp_62_SteeringWheelTurnedArtificiallyTakeOver" 63 "AIParkngDsp_63_VehicleSlowDownAndStopPleaseReleaseAcceleratorPedal" 64 "AIParkngDsp_64_LongPressButtonToContinueParkIn" 65 "AIParkngDsp_65_APFunctionPausingPressTheButtonToContinue" 66 "AIParkngDsp_66_APFunctionPausingPressContinueButtonToContinue" 67 "AIParkngDsp_67_ExecutingRemoteCarMovingPleaseSetWheelAngleAndMovingDirecitonThenLongPressTheButton" 68 "AIParkngDsp_68_PassTheCrossingBeAwareOfSurroundings" 69 "AIParkngDsp_69_RemoteCarMovingPausingLongPressTheButtonToContinue" 70 "AIParkngDsp_70_Thedecelerationbeltisbumpy" 71 "AIParkngDsp_71_ParkingInFailedDoUWantToContinueSearchParkingSpace" 72 "AIParkngDsp_72_ThereAreXXXLeftPathLearningDistance" 73 "AIParkngDsp_73_NoLeftPathLearningDistanceAndOutOfLimitLearningFailed" 74 "AIParkngDsp_74_Turnleftahead" 75 "AIParkngDsp_75_Turnrightahead" 76 "AIParkngDsp_76_IntelligentMapEstablishing" 77 "AIParkngDsp_77_IntelligentMapEstablished" 78 "AIParkngDsp_78_LocalizationInitialized" 79 "AIParkngDsp_79_LocationInitializingPleaseDriveTheCarToStartPointOfEstablishedPath" 80 "AIParkngDsp_80_ParkingToThatDirectionIsDifficultPleaseChangeAnotherDirection" 81 "AIParkngDsp_81_CarDeviatingThePlanningPathPleaseSetCarStraight" 82 "AIParkngDsp_82_AvoidingBeAwareOfSurroundings" 83 "AIParkngDsp_83_FunctionDegradedToManulDrivingBecauseOfSystemTimeOut" 84 "AIParkngDsp_84_AVPParkingLotExistingAroundTheDestination" 85 "AIParkngDsp_85_PleaseDriveTheCarToSpecifiedLocation" 86 "AIParkngDsp_86_SloplargeMapBuildingfailed" 87 "AIParkngDsp_87_CarHasArrivedAtTheMeetingSpotPleaseTakeOver" 88 "AIParkngDsp_88_UnableToPassPleaseTakeOver" 89 "AIParkngDsp_89_MapVersionMismatchingPleaseUpdateMapVersion" 90 "AIParkngDsp_90_PathLocationLostPleaseTakeOver" 91 "AIParkngDsp_91_VideoChannelOccupiedCannotOpen360SorroundedView" 92 "AIParkngDsp_92_ConnectionDisconnectPleaseTakeOver" 93 "AIParkngDsp_93_IfSettingCarSpotFirstStopTheCarAndThenSettingTheSpot" 94 "AIParkngDsp_94_MapDownloading" 95 "AIParkngDsp_95_PositioningInitializationFailed" 96 "AIParkngDsp_96_PleasePutIntoGearPAndGetDownWithTheMobilePhoneToConnectTheVehicle" 97 "AIParkngDsp_97_PleasePutIntoGearPAndGetDownWithTheMobilePhoneToConnectTheVehicle" 98 "AIParkngDsp_98_AVPFunctionFinished" 99 "AIParkngDsp_99_AVPFunctionFailed" 100 "AIParkngDsp_100_SystemFailedMapBuildingfailed" 101 "AIParkngDsp_101_TheInternetDisable" 102 "AIParkngDsp_102_TimeOut" 103 "AIParkngDsp_103_MapDownloadingfailed" 104 "AIParkngDsp_104_Pleasemakesurethatyouhaveparkedinthestoragespaceandkeepthevehiclestationaryfor3seconds" 105 "AIParkngDsp_105_IntelligentMapBuildingfailed" 106 "AIParkngDsp_106_SpeedistoohighMapBuildingfailed" 107 "AIParkngDsp_107_DistancetooshortMapBuildingfailed" 108 "AIParkngDsp_108_DrivingonrampBeAwareOfSurroundings" 109 "AIParkngDsp_109_Theparkinginmaphasfailledandtheparkingoutmaphassucceed" 110 "AIParkngDsp_110_Themapisbeinggeneratedtheusercanleavenormallyandthepowerwillbeautomaticallypoweredoffaftercompletion" 111 "AIParkngDsp_111_PlschangeOthSpc" 113 "AIParkngDsp_113_ThereAre50LeftPathLearningDistance" 114 "AIParkngDsp_114_ThereAre10LeftPathLearningDistance" 115 "AIParkngDsp_115_SlowdowntobelowXXXPlease" 116 "AIParkngDsp_116_SloplargePleaseTakeOver" 117 "AIParkngDsp_117_BrakesteponPleaseTakeOver" 118 "AIParkngDsp_118_BeltRleasePleaseTakeOver" 119 "AIParkngDsp_119_TargetspacenotavailableOtherspaceforyou" 120 "AIParkngDsp_120_PayattentiontoenvironmentPlease" 121 "AIParkngDsp_121_PayattentiontoThecollisionriskPlease" 122 "AIParkngDsp_122_Reserved" 123 "AIParkngDsp_123_Reserved" 124 "AIParkngDsp_124_Reserved" 125 "AIParkngDsp_125_Reserved" 126 "AIParkngDsp_126_Reserved" 127 "AIParkngDsp_127_Reserved" 128 "AIParkngDsp_128_ParkoutByourselfPlease" 129 "AIParkngDsp_129_DistanceTooShort" 130 "AIParkngDsp_130_ExcessiveSlop" 131 "AIParkngDsp_131_LackOfFeatures" 132 "AIParkngDsp_132_DistanceTooLong" 133 "AIParkngDsp_133_TimeTooLong" 134 "AIParkngDsp_134_VerificationTooLong" 135 "AIParkngDsp_135_WriteInFailure" 136 "AIParkngDsp_136_Reserved" 137 "AIParkngDsp_137_Reserved" 138 "AIParkngDsp_138_Reserved" 139 "AIParkngDsp_139_Reserved" 140 "AIParkngDsp_140_Reserved" 141 "AIParkngDsp_141_Reserved" 142 "AIParkngDsp_142_Reserved" 143 "AIParkngDsp_143_Reserved" 144 "AIParkngDsp_144_DnagerTakeoverPlease" 145 "AIParkngDsp_145_DnagerTakeoverPlease" 146 "AIParkngDsp_146_ReverseParkingPayattentiontoenvironmentPlease" 147 "AIParkngDsp_147_ApplybrakeClickstartreversing" 148 "AIParkngDsp_148_trailisabouttoendTakeoverPlease" 149 "AIParkngDsp_149_trailisendTakeoverPlease" 150 "AIParkngDsp_150_FunctionexitTakeoverPlease" 151 "AIParkngDsp_151_PayattentiontoenvironmentPlease" 152 "AIParkngDsp_152_Completedhorizontaledging" 153 "AIParkngDsp_153_PleasePushPedel" 154 "AIParkngDsp_154_UnexpectedOperationInsideVehicle" 155 "AIParkngDsp_155_Reserved" 156 "AIParkngDsp_156_Reserved" 157 "AIParkngDsp_157_Reserved" 158 "AIParkngDsp_158_Reserved" 159 "AIParkngDsp_159_Reserved" 160 "AIParkngDsp_160_Reserved" 161 "AIParkngDsp_161_Reserved" 162 "AIParkngDsp_162_Reserved" 163 "AIParkngDsp_163_Reserved" 164 "AIParkngDsp_164_Reserved" 165 "AIParkngDsp_165_Reserved" 166 "AIParkngDsp_166_Reserved" 167 "AIParkngDsp_167_Reserved" 168 "AIParkngDsp_168_Reserved" 169 "AIParkngDsp_169_Reserved" 170 "AIParkngDsp_170_Reserved" 171 "AIParkngDsp_171_Reserved" 172 "AIParkngDsp_172_Reserved" 173 "AIParkngDsp_173_Reserved" 174 "AIParkngDsp_174_Reserved" 175 "AIParkngDsp_175_Reserved" 176 "AIParkngDsp_176_Reserved" 177 "AIParkngDsp_177_Reserved" 178 "AIParkngDsp_178_Reserved" 179 "AIParkngDsp_179_Reserved" 180 "AIParkngDsp_180_Reserved" 181 "AIParkngDsp_181_Reserved" 182 "AIParkngDsp_182_Reserved" 183 "AIParkngDsp_183_Reserved" 184 "AIParkngDsp_184_Reserved" 185 "AIParkngDsp_185_Reserved" 186 "AIParkngDsp_186_Reserved" 187 "AIParkngDsp_187_Reserved" 188 "AIParkngDsp_188_Reserved" 189 "AIParkngDsp_189_Reserved" 190 "AIParkngDsp_190_Reserved" 191 "AIParkngDsp_191_Reserved" 192 "AIParkngDsp_192_Reserved" 193 "AIParkngDsp_193_Reserved" 194 "AIParkngDsp_194_Reserved" 195 "AIParkngDsp_195_Reserved" 196 "AIParkngDsp_196_Reserved" 197 "AIParkngDsp_197_Reserved" 198 "AIParkngDsp_198_Reserved" 199 "AIParkngDsp_199_Reserved" 200 "AIParkngDsp_200_Reserved" 201 "AIParkngDsp_201_Reserved" 202 "AIParkngDsp_202_Reserved" 203 "AIParkngDsp_203_Reserved" 204 "AIParkngDsp_204_Reserved" 205 "AIParkngDsp_205_Reserved" 206 "AIParkngDsp_206_Reserved" 207 "AIParkngDsp_207_Reserved" 208 "AIParkngDsp_208_Reserved" 209 "AIParkngDsp_209_Reserved" 210 "AIParkngDsp_210_Reserved" 211 "AIParkngDsp_211_Reserved" 212 "AIParkngDsp_212_Reserved" 213 "AIParkngDsp_213_Reserved" 214 "AIParkngDsp_214_Reserved" 215 "AIParkngDsp_215_Reserved" 216 "AIParkngDsp_216_Reserved" 217 "AIParkngDsp_217_Reserved" 218 "AIParkngDsp_218_Reserved" 219 "AIParkngDsp_219_Reserved" 220 "AIParkngDsp_220_Reserved" 221 "AIParkngDsp_221_Reserved" 222 "AIParkngDsp_222_Reserved" 223 "AIParkngDsp_223_Reserved" 224 "AIParkngDsp_224_Reserved" 225 "AIParkngDsp_225_Reserved" 226 "AIParkngDsp_226_Reserved" 227 "AIParkngDsp_227_Reserved" 228 "AIParkngDsp_228_Reserved" 229 "AIParkngDsp_229_Reserved" 230 "AIParkngDsp_230_Reserved" 231 "AIParkngDsp_231_Reserved" 232 "AIParkngDsp_232_Reserved" 233 "AIParkngDsp_233_Reserved" 234 "AIParkngDsp_234_Reserved" 235 "AIParkngDsp_235_Reserved" 236 "AIParkngDsp_236_Reserved" 237 "AIParkngDsp_237_Reserved" 238 "AIParkngDsp_238_Reserved" 239 "AIParkngDsp_239_Reserved" 240 "AIParkngDsp_240_Reserved" 241 "AIParkngDsp_241_Reserved" 242 "AIParkngDsp_242_Reserved" 243 "AIParkngDsp_243_Reserved" 244 "AIParkngDsp_244_Reserved" 245 "AIParkngDsp_245_Reserved" 246 "AIParkngDsp_246_Reserved" 247 "AIParkngDsp_247_Reserved" 248 "AIParkngDsp_248_Reserved" 249 "AIParkngDsp_249_Reserved" 250 "AIParkngDsp_250_Reserved" 251 "AIParkngDsp_251_Reserved" 252 "AIParkngDsp_252_Reserved" 253 "AIParkngDsp_253_Reserved" 254 "AIParkngDsp_254_Reserved" 255 "AIParkngDsp_255_Reserved";
VAL_ 917 AIParkngSts 0 "AIParkngSts_0_Off" 1 "AIParkngSts_1_ParkingDisable" 2 "AIParkngSts_2_ParkingJudging" 3 "AIParkngSts_3_SummonDisable" 4 "AIParkngSts_4_SummonJudging" 5 "AIParkngSts_5_MapBuilding" 6 "AIParkngSts_6_MapBuilding_APA_DrivingConfirming" 7 "AIParkngSts_7_LineMoving" 8 "AIParkngSts_8_LineMovePausing" 9 "AIParkngSts_9_MapBuilding_APA_ParkingInParking_ficm" 10 "AIParkngSts_10_ManualParkingInScanningParking_ficm" 11 "AIParkngSts_11_ManualParkingInScanningParking_ipk" 12 "AIParkngSts_12_LineMoveActive" 13 "AIParkngSts_13_SummonPausing" 14 "AIParkngSts_14_LVP_APA_Pausing" 15 "AIParkngSts_15_RememberParkingOut" 16 "AIParkngSts_16_Reserved" 17 "AIParkngSts_17_RememberParkOutPausing" 18 "AIParkngSts_18_LVP_ParkingInScanning_ficm" 19 "AIParkngSts_19_ParkingInScanning_app" 20 "AIParkngSts_20_ParkingInScanPausing" 21 "AIParkngSts_21_ParkingInSpaceConfirming" 22 "AIParkngSts_22_ParkingInParking_ficm" 23 "AIParkngSts_23_ParkingInParking_app" 24 "AIParkngSts_24_ParkingInParkPausing" 25 "AIParkngSts_25_ParkingOutParking_ficm" 26 "AIParkngSts_26_ParkingOutParking_app" 27 "AIParkngSts_27_ParkingOutPausing" 28 "AIParkngSts_28_ParkingOutParking_key" 29 "AIParkngSts_29_ParkingInParking_key" 30 "AIParkngSts_30_LVP_RemenberParkInSpaceConfirming" 31 "AIParkngSts_31_OtherFunctionConflictg" 32 "AIParkngSts_33_Reserved" 33 "AIParkngSts_33_AVPMapLoading" 34 "AIParkngSts_34_AVPCrusing" 35 "AIParkngSts_35_AVParkNaving" 36 "AIParkngSts_36_AVParkNavPausing" 37 "AIParkngSts_37_AVParking" 38 "AIParkngSts_38_AVParkPausing" 39 "AIParkngSts_39_AVParkingout" 40 "AIParkngSts_40_AVParkoutPausing" 41 "AIParkngSts_41_APAParkoutPreactive" 42 "AIParkngSts_42_Suspend" 43 "AIParkngSts_43_ManualDrivingConfirming" 44 "AIParkngSts_44_ConfirmingMobile" 45 "AIParkngSts_45_ParkingStandby" 46 "AIParkngSts_46_LVPStandby_confirming" 47 "AIParkngSts_47_MapBuilding_APA_ParkingDisable" 48 "AIParkngSts_48_Reserved" 49 "AIParkngSts_49_ManualParkingInScanningParking_wlc" 50 "AIParkngSts_50_MapBuilding_APA_Suspend" 51 "AIParkngSts_51_MapSuspend" 52 "AIParkngSts_52_MapBuilding_APA_ParkingJudging" 53 "AIParkngSts_53_LVPStandby" 54 "AIParkngSts_54_LVPPreactive" 55 "AIParkngSts_55_LVPParkingPreactive" 56 "AIParkngSts_56_LVPCruising" 57 "AIParkngSts_57_LVP_APA_Suspend" 58 "AIParkngSts_58_LVPComplete" 59 "AIParkngSts_59_MapBuildingComplete" 60 "AIParkngSts_60_MapBuildingFailure" 61 "AIParkngSts_61_MapCheck" 62 "AIParkngSts_62_MapBuilding_APA_ParkingInParkPausing" 63 "AIParkngSts_63_ParkoutMapBuildingComplete" 64 "AIParkngSts_64_ParkoutMapBuilding" 65 "AIParkngSts_65_LineMoveFailure" 66 "AIParkngSts_66_LVPFailure" 67 "AIParkngSts_67_AVP_Park_in_Preactive" 68 "AIParkngSts_68_AVP_Park_out_Preactive" 69 "AIParkngSts_69_LVP_APA_ParkingIN" 70 "AIParkngSts_70_RPAParkingoutPreactive" 71 "AIParkngSts_71_ParkingoutPausing_RPA" 72 "AIParkngSts_72_ManualConfirming_Key" 73 "AIParkngSts_73_ParkingInParkPausing_key" 74 "AIParkngSts_74_Suspend_key" 75 "AIParkngSts_75_OneClickAdjust" 76 "AIParkngSts_76_OneClickAdjustPausing" 77 "AIParkngSts_77_FunctionFailed" 78 "AIParkngSts_78_Reserved" 79 "AIParkngSts_79_Reserved" 80 "AIParkngSts_80_Reserved" 81 "AIParkngSts_81_Reserved" 82 "AIParkngSts_82_Reserved" 83 "AIParkngSts_83_Reserved" 84 "AIParkngSts_84_Reserved" 85 "AIParkngSts_85_Reserved" 86 "AIParkngSts_86_Reserved" 87 "AIParkngSts_87_Reserved" 88 "AIParkngSts_88_Reserved" 89 "AIParkngSts_89_Reserved" 90 "AIParkngSts_90_Reserved" 91 "AIParkngSts_91_Reserved" 92 "AIParkngSts_92_Reserved" 93 "AIParkngSts_93_Reserved" 94 "AIParkngSts_94_Reserved" 95 "AIParkngSts_95_Reserved" 96 "AIParkngSts_96_Reserved" 97 "AIParkngSts_97_Reserved" 98 "AIParkngSts_98_Reserved" 99 "AIParkngSts_99_Reserved" 100 "AIParkngSts_100_Reserved" 101 "AIParkngSts_101_Reserved" 102 "AIParkngSts_102_Reserved" 103 "AIParkngSts_103_Reserved" 104 "AIParkngSts_104_Reserved" 105 "AIParkngSts_105_Reserved" 106 "AIParkngSts_106_Reserved" 107 "AIParkngSts_107_Reserved" 108 "AIParkngSts_108_Reserved" 109 "AIParkngSts_109_Reserved" 110 "AIParkngSts_110_Reserved" 111 "AIParkngSts_111_Reserved" 112 "AIParkngSts_112_Reserved" 113 "AIParkngSts_113_Reserved" 114 "AIParkngSts_114_Reserved" 115 "AIParkngSts_115_Reserved" 116 "AIParkngSts_116_Reserved" 117 "AIParkngSts_117_Reserved" 118 "AIParkngSts_118_Reserved" 119 "AIParkngSts_119_Reserved" 120 "AIParkngSts_120_Reserved" 121 "AIParkngSts_121_Reserved" 122 "AIParkngSts_122_Reserved" 123 "AIParkngSts_123_Reserved" 124 "AIParkngSts_124_Reserved" 125 "AIParkngSts_125_Reserved" 126 "AIParkngSts_126_Reserved" 127 "AIParkngSts_127_Reserved" 128 "AIParkngSts_128_Reserved" 129 "AIParkngSts_129_Reserved" 130 "AIParkngSts_130_Reserved" 131 "AIParkngSts_131_Reserved" 132 "AIParkngSts_132_Reserved" 133 "AIParkngSts_133_Reserved" 134 "AIParkngSts_134_Reserved" 135 "AIParkngSts_135_Reserved" 136 "AIParkngSts_136_Reserved" 137 "AIParkngSts_137_Reserved" 138 "AIParkngSts_138_Reserved" 139 "AIParkngSts_139_Reserved" 140 "AIParkngSts_140_Reserved" 141 "AIParkngSts_141_Reserved" 142 "AIParkngSts_142_Reserved" 143 "AIParkngSts_143_Reserved" 144 "AIParkngSts_144_Reserved" 145 "AIParkngSts_145_Reserved" 146 "AIParkngSts_146_Reserved" 147 "AIParkngSts_147_Reserved" 148 "AIParkngSts_148_Reserved" 149 "AIParkngSts_149_Reserved" 150 "AIParkngSts_150_Reserved" 151 "AIParkngSts_151_Reserved" 152 "AIParkngSts_152_Reserved" 153 "AIParkngSts_153_Reserved" 154 "AIParkngSts_154_Reserved" 155 "AIParkngSts_155_Reserved" 156 "AIParkngSts_156_Reserved" 157 "AIParkngSts_157_Reserved" 158 "AIParkngSts_158_Reserved" 159 "AIParkngSts_159_Reserved" 160 "AIParkngSts_160_Reserved" 161 "AIParkngSts_161_Reserved" 162 "AIParkngSts_162_Reserved" 163 "AIParkngSts_163_Reserved" 164 "AIParkngSts_164_Reserved" 165 "AIParkngSts_165_Reserved" 166 "AIParkngSts_166_Reserved" 167 "AIParkngSts_167_Reserved" 168 "AIParkngSts_168_Reserved" 169 "AIParkngSts_169_Reserved" 170 "AIParkngSts_170_Reserved" 171 "AIParkngSts_171_Reserved" 172 "AIParkngSts_172_Reserved" 173 "AIParkngSts_173_Reserved" 174 "AIParkngSts_174_Reserved" 175 "AIParkngSts_175_Reserved" 176 "AIParkngSts_176_Reserved" 177 "AIParkngSts_177_Reserved" 178 "AIParkngSts_178_Reserved" 179 "AIParkngSts_179_Reserved" 180 "AIParkngSts_180_Reserved" 181 "AIParkngSts_181_Reserved" 182 "AIParkngSts_182_Reserved" 183 "AIParkngSts_183_Reserved" 184 "AIParkngSts_184_Reserved" 185 "AIParkngSts_185_Reserved" 186 "AIParkngSts_186_Reserved" 187 "AIParkngSts_187_Reserved" 188 "AIParkngSts_188_Reserved" 189 "AIParkngSts_189_Reserved" 190 "AIParkngSts_190_Reserved" 191 "AIParkngSts_191_Reserved" 192 "AIParkngSts_192_Reserved" 193 "AIParkngSts_193_Reserved" 194 "AIParkngSts_194_Reserved" 195 "AIParkngSts_195_Reserved" 196 "AIParkngSts_196_Reserved" 197 "AIParkngSts_197_Reserved" 198 "AIParkngSts_198_Reserved" 199 "AIParkngSts_199_Reserved" 200 "AIParkngSts_200_Reserved" 201 "AIParkngSts_201_Reserved" 202 "AIParkngSts_202_Reserved" 203 "AIParkngSts_203_Reserved" 204 "AIParkngSts_204_Reserved" 205 "AIParkngSts_205_Reserved" 206 "AIParkngSts_206_Reserved" 207 "AIParkngSts_207_Reserved" 208 "AIParkngSts_208_Reserved" 209 "AIParkngSts_209_Reserved" 210 "AIParkngSts_210_Reserved" 211 "AIParkngSts_211_Reserved" 212 "AIParkngSts_212_Reserved" 213 "AIParkngSts_213_Reserved" 214 "AIParkngSts_214_Reserved" 215 "AIParkngSts_215_Reserved" 216 "AIParkngSts_216_Reserved" 217 "AIParkngSts_217_Reserved" 218 "AIParkngSts_218_Reserved" 219 "AIParkngSts_219_Reserved" 220 "AIParkngSts_220_Reserved" 221 "AIParkngSts_221_Reserved" 222 "AIParkngSts_222_Reserved" 223 "AIParkngSts_223_Reserved" 224 "AIParkngSts_224_Reserved" 225 "AIParkngSts_225_Reserved" 226 "AIParkngSts_226_Reserved" 227 "AIParkngSts_227_Reserved" 228 "AIParkngSts_228_Reserved" 229 "AIParkngSts_229_Reserved" 230 "AIParkngSts_230_Reserved" 231 "AIParkngSts_231_Reserved" 232 "AIParkngSts_232_Reserved" 233 "AIParkngSts_233_Reserved" 234 "AIParkngSts_234_Reserved" 235 "AIParkngSts_235_Reserved" 236 "AIParkngSts_236_Reserved" 237 "AIParkngSts_237_Reserved" 238 "AIParkngSts_238_Reserved" 239 "AIParkngSts_239_Reserved" 240 "AIParkngSts_240_Reserved" 241 "AIParkngSts_241_Reserved" 242 "AIParkngSts_242_Reserved" 243 "AIParkngSts_243_Reserved" 244 "AIParkngSts_244_Reserved" 245 "AIParkngSts_245_Reserved" 246 "AIParkngSts_246_Reserved" 247 "AIParkngSts_247_Reserved" 248 "AIParkngSts_248_Reserved" 249 "AIParkngSts_249_Reserved" 250 "AIParkngSts_250_Reserved" 251 "AIParkngSts_251_Reserved" 252 "AIParkngSts_252_Reserved" 253 "AIParkngSts_253_Reserved" 254 "AIParkngSts_254_Reserved" 255 "AIParkngSts_255_Reserved";
VAL_ 859 SpdAstCndStsCamr 0 "SpdAstCndStsCamr_0_non_conditionalspeedlimit" 1 "SpdAstCndStsCamr_1_conditionalspeedlimit" 2 "SpdAstCndStsCamr_2_Conditional_speed_limit_apply" 3 "SpdAstCndStsCamr_3_Conditional_speed_limit_Not_apply" 4 "SpdAstCndStsCamr_4_Conditional_speed_limit_Unknown" 5 "SpdAstCndStsCamr_5_conditional_speed_limit_Snow_Icy_Warning_only" 15 "SpdAstCndStsCamr_15_nationalspeedlimit";
VAL_ 859 SpdLmtMdResp 0 "SpdLmtMdResp_0_Unavailable" 1 "SpdLmtMdResp_1_Off" 2 "SpdLmtMdResp_2_SLIF" 3 "SpdLmtMdResp_3_ISA";
VAL_ 859 AutoMainBeamLghtReq 0 "AutoMainBeamLghtReq_0_NoRequest" 1 "AutoMainBeamLghtReq_1_RequestOnFromCamera" 2 "AutoMainBeamLghtReq_2_RequestOffFromCamera" 3 "AutoMainBeamLghtReq_3_CannotDetectedTheEnvironment";
VAL_ 895 NarwSpcAstSwSts 0 "NarwSpcAstSwSts_0_Narwspcastswsts_0_Unavailable" 1 "NarwSpcAstSwSts_1_ON" 2 "NarwSpcAstSwSts_2_OFF";
VAL_ 895 IPDStsResp 0 "IPDStsResp_0_NoRequest" 1 "IPDStsResp_1_ON" 2 "IPDStsResp_2_OFF";
VAL_ 895 NarwSpcAstBtnSts 0 "NarwSpcAstBtnSts_0_Off" 1 "NarwSpcAstBtnSts_1_OnlyForwardAvailable" 2 "NarwSpcAstBtnSts_2_OnlyBackwardAvailable" 3 "NarwSpcAstBtnSts_3_ForwardAndBackwardAvailable" 4 "NarwSpcAstBtnSts_4_Unavailable";
VAL_ 895 IPD_VehLckCtrlReq 0 "VehLckCtrlReq_0_NoRequest" 1 "VehLckCtrlReq_1_InteriorUnlockRequest" 2 "VehLckCtrlReq_2_ExteriorUnlockRequest" 3 "VehLckCtrlReq_3_InteriorLockRequest" 4 "VehLckCtrlReq_4_ExteriorLockRequest";
VAL_ 895 IPDMCUTemp 255 "IPDAurixTemp_255_Invalid_Value";
VAL_ 895 IPDWtrClntInltReqFlg 0 "IPDWtrClntInltReqFlg_0_Request" 1 "IPDWtrClntInltReqFlg_1_No_Request";
VAL_ 895 TrfGreenLghtActn 0 "TrfGreenLghtActn_0_NoDisplay" 1 "TrfGreenLghtActn_1_GreenLight_warning";
SIG_GROUP_ 898 IFDR_100ms_Group01 1 : FDRSts FDR_100ms_Group01_CRC FDR_100ms_Group01_RC FDR_100ms_Group01_Reserved1 FDR_100ms_Group01_Reserved2 FDR_100ms_Group01_Reserved3 FDR_100ms_Group01_Reserved4 FDR_100ms_Group01_Reserved5 FDR_100ms_Group01_Reserved6 FDR_100ms_Group01_Reserved7;
SIG_GROUP_ 307 IFVCM_20ms_Group02 1 : ACCDetObjDistLvl ACCDrvrSelTrgtSpd ACCGoNotfr ACCMsgReq ACCSeldTrgtDistLvl ACCTJAMdSwDspCmd ACCTotWhlToqReqSts ACCTotWhlToqReqVal ELKSysSts_IPD EyeOffRoadDetnSta EyeOffRoadDetnStaV FVCM_20ms_Group02_CRC FVCM_20ms_Group02_RC FVCM_20ms_Group02_Reserved1 FVCM_20ms_Group02_Reserved2 FVCM_20ms_Group02_Reserved3 FVCM_20ms_Group02_Reserved4 FVCM_20ms_Group02_Reserved5 FVCM_20ms_Group02_Reserved6 FVCM_20ms_Group02_Reserved7 FVCM_20ms_Group02_Reserved8 HandOffStrgWhlDetnSta HandOffStrgWhlDetnStaV ILCActvnDircnDspCmd ILCActvnVelDspCmd ILCSwDspCmd ILCSysSts LDWAdoWrnngDspCmd LDWLKAAudReq LDWLKADspCmd LDWLKAHptWrnngDspCmd LDWSnstvtLvl LKADrvrTkovReq;
SIG_GROUP_ 887 IIAM_100ms_Group08 1 : AltSigma IAM_100ms_Group08_CRC IAM_100ms_Group08_RC IAM_100ms_Group08_Reserved15 LatSigma LonSigma;
SIG_GROUP_ 912 IIAM_ZONE_100ms_Group34 1 : Hdop IAM_ZONE_100ms_Group34_CRC IAM_ZONE_100ms_Group34_RC IAM_ZONE_100ms_Group34_Reserved1 IAM_ZONE_100ms_Group34_Reserved2 IAM_ZONE_100ms_Group34_Reserved3 IAM_ZONE_100ms_Group34_Reserved5 Pdop Vdop;
SIG_GROUP_ 874 IIAM_ZONE_100ms_Group40 1 : AltitudeRTK HeadingRTK IAM_ZONE_100ms_Group40_CRC IAM_ZONE_100ms_Group40_RC IAM_ZONE_100ms_Group40_Reserved1 IAM_ZONE_100ms_Group40_Reserved6;
SIG_GROUP_ 336 IIAM_20ms_Group32 1 : IAM_20ms_Group32_CRC IAM_20ms_Group32_RC IAM_20ms_Group32_Reserved1 IAM_20ms_Group32_Reserved10 IAM_20ms_Group32_Reserved2 IAM_20ms_Group32_Reserved3 IAM_20ms_Group32_Reserved4 IAM_20ms_Group32_Reserved5 IAM_20ms_Group32_Reserved6 IAM_20ms_Group32_Reserved7 IAM_20ms_Group32_Reserved8 IAM_20ms_Group32_Reserved9 RmtDrvrTrgtEPSStrgWhlAng RmtParkngAstAbotBtnSts RmtParkngAstBtnSts RmtParkngAstDvcFlrRsn RmtParkngAstDvcSts RmtParkngAstParkngOutDircnSeln VehBkwdSwReq VehBkwdSwReqV VehFwdSwReq VehFwdSwReqV VehRoadWhlLReq VehRoadWhlLReqV VehRoadWhlRReq VehRoadWhlRReqV;
SIG_GROUP_ 811 IIAM_100ms_Group18 1 : HeadingSigma IAM_100ms_Group18_CRC IAM_100ms_Group18_RC IAM_100ms_Group18_Reserved15 PitchRTK PitchSigma;
SIG_GROUP_ 810 IIAM_ZONE_100ms_Group57 1 : IAM_ZONE_100ms_Group57_CRC IAM_ZONE_100ms_Group57_RC IAM_ZONE_100ms_Group57_Reserved1 IAM_ZONE_100ms_Group57_Reserved6 LongitudeRTK;
SIG_GROUP_ 793 IIAM_ZONE_100ms_Group35 1 : GNSSF9HCounter GNSSUTCTime IAM_ZONE_100ms_Group35_CRC IAM_ZONE_100ms_Group35_RC IAM_ZONE_100ms_Group35_Reserved1;
SIG_GROUP_ 773 IIAM_ZONE_100ms_Group13 1 : FixType GNSSSeq GNSSUTCTimeH IAM_ZONE_100ms_Group13_CRC IAM_ZONE_100ms_Group13_RC IAM_ZONE_100ms_Group13_Reserved1;
SIG_GROUP_ 974 IIAM_100ms_Group56 1 : IAM_100ms_Group56_CRC IAM_100ms_Group56_RC IAM_100ms_Group56_Reserved13 IAM_100ms_Group56_Reserved63 IAM_GNSS_Signal_Status LatitudeRTK;
